VERSION ""

NS_ :

BS_:

BU_: CH DIPF DIPR ETH FC HVI HVS PARTY SDCV VEH VIRT

BO_ 777 DAS_object: 8 CH
 SG_ DAS_leadVeh2Id m0 : 58|6@1+ (1,0) [0|63] ""  aps
 SG_ DAS_leftVeh2Id m1 : 58|6@1+ (1,0) [0|63] ""  aps
 SG_ DAS_rightVeh2Id m2 : 58|6@1+ (1,0) [0|63] ""  aps
 SG_ DAS_cutinVehHeading m5 : 56|8@1+ (0.0245437,-3.1415936) [-3.1415936|3.0925062] "rad"  aps
 SG_ DAS_rightVeh2Dy m2 : 51|7@1+ (0.35,-22.05) [-22.05|22.4] "m"  aps
 SG_ DAS_leadVeh2Dy m0 : 51|7@1+ (0.35,-22.05) [-22.05|22.4] "m"  aps
 SG_ DAS_leftVeh2Dy m1 : 51|7@1+ (0.35,-22.05) [-22.05|22.4] "m"  aps
 SG_ DAS_rightVeh2Heading m5 : 48|8@1+ (0.0245437,-3.1415936) [-3.1415936|3.0925062] "rad"  aps
 SG_ DAS_leftVeh2VxRel m1 : 47|4@1+ (4,-30) [-30|26] "m/s"  aps
 SG_ DAS_rightVeh2VxRel m2 : 47|4@1+ (4,-30) [-30|26] "m/s"  aps
 SG_ DAS_leadVeh2VxRel m0 : 47|4@1+ (4,-30) [-30|26] "m/s"  aps
 SG_ DAS_rightVehHeading m5 : 40|8@1+ (0.0245437,-3.1415936) [-3.1415936|3.0925062] "rad"  aps
 SG_ DAS_leftVeh2Dx m1 : 39|8@1+ (0.5,0) [0|127] "m"  aps
 SG_ DAS_rightVeh2Dx m2 : 39|8@1+ (0.5,0) [0|127] "m"  aps
 SG_ DAS_leadVeh2Dx m0 : 39|8@1+ (0.5,0) [0|127] "m"  aps
 SG_ DAS_leadVeh2RelevantForControl m0 : 38|1@1+ (1,0) [0|1] ""  aps
 SG_ DAS_rightVeh2RelevantForControl m2 : 38|1@1+ (1,0) [0|1] ""  aps
 SG_ DAS_leftVeh2RelevantForControl m1 : 38|1@1+ (1,0) [0|1] ""  aps
 SG_ DAS_leadVeh2Type m0 : 34|3@1+ (1,0) [0|5] ""  aps
 SG_ DAS_leftVeh2Type m1 : 34|3@1+ (1,0) [0|5] ""  aps
 SG_ DAS_rightVeh2Type m2 : 34|3@1+ (1,0) [0|5] ""  aps
 SG_ DAS_leftVeh2Heading m5 : 32|8@1+ (0.0245437,-3.1415936) [-3.1415936|3.0925062] "rad"  aps
 SG_ DAS_roadSignOrientation m4 : 30|2@1+ (1,0) [0|2] ""  aps
 SG_ DAS_roadSignArrow m4 : 27|3@1+ (1,0) [0|4] ""  aps
 SG_ DAS_rightVehId m2 : 27|7@1+ (1,0) [0|127] ""  aps
 SG_ DAS_leadVehId m0 : 27|7@1+ (1,0) [0|127] ""  aps
 SG_ DAS_cutinVehId m3 : 27|7@1+ (1,0) [0|127] ""  aps
 SG_ DAS_leftVehId m1 : 27|7@1+ (1,0) [0|127] ""  aps
 SG_ DAS_roadSignSource m4 : 25|2@1+ (1,0) [0|2] ""  aps
 SG_ DAS_roadSignControlActive m4 : 24|1@1+ (1,0) [0|1] ""  aps
 SG_ DAS_leftVehHeading m5 : 24|8@1+ (0.0245437,-3.1415936) [-3.1415936|3.0925062] "rad"  aps
 SG_ DAS_leadVehDy m0 : 20|7@1+ (0.35,-22.05) [-22.05|22.4] "m"  aps
 SG_ DAS_cutinVehDy m3 : 20|7@1+ (0.35,-22.05) [-22.05|22.4] "m"  aps
 SG_ DAS_leftVehDy m1 : 20|7@1+ (0.35,-22.05) [-22.05|22.4] "m"  aps
 SG_ DAS_rightVehDy m2 : 20|7@1+ (0.35,-22.05) [-22.05|22.4] "m"  aps
 SG_ DAS_leadVehVxRel m0 : 16|4@1+ (4,-30) [-30|26] "m/s"  aps
 SG_ DAS_cutinVehVxRel m3 : 16|4@1+ (4,-30) [-30|26] "m/s"  aps
 SG_ DAS_rightVehVxRel m2 : 16|4@1+ (4,-30) [-30|26] "m/s"  aps
 SG_ DAS_leftVehVxRel m1 : 16|4@1+ (4,-30) [-30|26] "m/s"  aps
 SG_ DAS_leadVeh2Heading m5 : 16|8@1+ (0.0245437,-3.1415936) [-3.1415936|3.0925062] "rad"  aps
 SG_ DAS_roadSignStopLineDist m4 : 14|10@1+ (0.2,-20) [-20|184.4] "m"  aps
 SG_ DAS_rightVehDx m2 : 8|8@1+ (0.5,0) [0|127] "m"  aps
 SG_ DAS_cutinVehDx m3 : 8|8@1+ (0.5,0) [0|127] "m"  aps
 SG_ DAS_leftVehDx m1 : 8|8@1+ (0.5,0) [0|127] "m"  aps
 SG_ DAS_leadVehDx m0 : 8|8@1+ (0.5,0) [0|127] "m"  aps
 SG_ DAS_leadVehHeading m5 : 8|8@1+ (0.0245437,-3.1415936) [-3.1415936|3.0925062] "rad"  aps
 SG_ DAS_leftVehRelevantForControl m1 : 7|1@1+ (1,0) [0|1] ""  aps
 SG_ DAS_rightVehRelevantForControl m2 : 7|1@1+ (1,0) [0|1] ""  aps
 SG_ DAS_leadVehRelevantForControl m0 : 7|1@1+ (1,0) [0|1] ""  aps
 SG_ DAS_cutinVehRelevantForControl m3 : 7|1@1+ (1,0) [0|1] ""  aps
 SG_ DAS_roadSignId m4 : 6|8@1+ (1,0) [0|255] ""  aps
 SG_ DAS_leadVehType m0 : 3|3@1+ (1,0) [0|6] ""  aps
 SG_ DAS_rightVehType m2 : 3|3@1+ (1,0) [0|5] ""  aps
 SG_ DAS_roadSignColor m4 : 3|3@1+ (1,0) [0|4] ""  aps
 SG_ DAS_leftVehType m1 : 3|3@1+ (1,0) [0|5] ""  aps
 SG_ DAS_cutinVehType m3 : 3|3@1+ (1,0) [0|5] ""  aps
 SG_ DAS_objectId M : 0|3@1+ (1,0) [0|5] ""  aps

BO_ 1796 DBG_xcpPMCommand: 8 CH
 SG_ DBG_xcpPMCommand : 7|64@0+ (1,0) [0|18446744073709551615] ""  X

BO_ 737 VCFRONT_status: 8 CH
 SG_ VCFRONT_frunkAccessPost m0 : 62|1@1+ (1,0) [0|1] ""  X
 SG_ VCFRONT_headlampRightFanStatus m0 : 61|1@1+ (1,0) [0|1] ""  X
 SG_ VCFRONT_headlampLeftFanStatus m0 : 60|1@1+ (1,0) [0|1] ""  X
 SG_ VCFRONT_12VOverchargeCounter m4 : 59|4@1+ (1,0) [0|15] ""  X
 SG_ VCFRONT_sleepCurrent m1 : 53|10@1- (1,0) [-512|511] "mA"  X
 SG_ VCFRONT_wiperPositionDeg m0 : 52|8@1+ (1,0) [0|255] "deg"  X
 SG_ VCFRONT_hornOn m0 : 51|1@1+ (1,0) [0|1] ""  X
 SG_ VCFRONT_anyDoorOpen m0 : 50|1@1+ (1,0) [0|1] ""  tas
 SG_ VCFRONT_anyClosureOpen m0 : 49|1@1+ (1,0) [0|1] ""  tas
 SG_ VCFRONT_wiperCycles m3 : 48|16@1+ (100,0) [0|6553500] "Cycles"  X
 SG_ VCFRONT_homelinkCommStatus m2 : 48|2@1+ (1,0) [0|3] ""  X
 SG_ VCFRONT_frunkInteriorRelSwitch m0 : 48|1@1+ (1,0) [0|1] ""  X
 SG_ VCFRONT_timeSpentSleeping m1 : 45|8@1+ (1,0) [0|255] "s"  X
 SG_ VCFRONT_IBSUnfilteredTemperature m4 : 43|16@1- (0.01,0) [-327.68|327.67] "degC"  X
 SG_ VCFRONT_HSDInitCompleteU16 m4 : 42|1@1+ (1,0) [0|1] ""  X
 SG_ VCFRONT_HSDInitCompleteU13 m4 : 41|1@1+ (1,0) [0|1] ""  X
 SG_ VCFRONT_PEResetLineState m4 : 40|1@1+ (1,0) [0|1] ""  X
 SG_ VCFRONT_pressureRefrigDischarge m3 : 40|8@1+ (0.125,0) [0|31.75] "bar"  X
 SG_ VCFRONT_homelinkV2Response4 m2 : 40|8@1+ (1,0) [0|255] ""  X
 SG_ VCFRONT_IBSFault m4 : 39|1@1+ (1,0) [0|1] ""  X
 SG_ VCFRONT_PCSMia m4 : 38|1@1+ (1,0) [0|1] ""  X
 SG_ VCFRONT_headlightRightVPosition m0 : 38|10@1+ (1,0) [0|1023] "ticks"  X
 SG_ VCFRONT_chargeNeeded m4 : 37|1@1+ (1,0) [0|1] ""  X
 SG_ VCFRONT_timeSpentDischarging m1 : 35|10@1+ (1,0) [0|1023] "min"  X
 SG_ VCFRONT_pressureRefrigSuction m3 : 32|7@1+ (0.125,0) [0|11.5] "bar"  X
 SG_ VCFRONT_homelinkV2Response3 m2 : 32|8@1+ (1,0) [0|255] ""  X
 SG_ VCFRONT_hasLowRefrigerant m3 : 29|1@1+ (1,0) [0|1] ""  X
 SG_ VCFRONT_headlightLeftVPosition m0 : 28|10@1+ (1,0) [0|1023] "ticks"  X
 SG_ VCFRONT_compPerfRecoveryLimited m3 : 27|1@1+ (1,0) [0|1] ""  X
 SG_ VCFRONT_chillerDemandActive m3 : 26|1@1+ (1,0) [0|1] ""  X
 SG_ VCFRONT_timeSpentCharging m1 : 25|10@1+ (1,0) [0|1023] "min"  X
 SG_ VCFRONT_isEvapOperationAllowed m3 : 25|1@1+ (1,0) [0|1] ""  X
 SG_ VCFRONT_airCompressorStatus m0 : 25|3@1+ (1,0) [0|7] ""  tas
 SG_ VCFRONT_AS8510Voltage m4 : 25|12@1+ (0.005443676098,0) [0|22.28641] "V"  X
 SG_ VCFRONT_crashUnlockOverrideSet m0 : 24|1@1+ (1,0) [0|1] ""  X
 SG_ VCFRONT_freezeEvapITerm m3 : 24|1@1+ (1,0) [0|1] ""  X
 SG_ VCFRONT_homelinkV2Response2 m2 : 24|8@1+ (1,0) [0|255] ""  X
 SG_ VCFRONT_crashState m0 : 22|2@1+ (1,0) [0|2] ""  X
 SG_ VCFRONT_batterySMState m1 : 22|3@1+ (1,0) [0|7] ""  X
 SG_ VCFRONT_reverseBatteryFault m1 : 21|1@1+ (1,0) [0|1] ""  X
 SG_ VCFRONT_crashDetectedType m0 : 20|2@1+ (1,0) [0|2] ""  X
 SG_ VCFRONT_vehicleStatusDBG m1 : 16|5@1+ (1,0) [0|17] ""  X
 SG_ VCFRONT_wiperState m0 : 16|4@1+ (1,0) [0|12] ""  das
 SG_ VCFRONT_homelinkV2Response1 m2 : 16|8@1+ (1,0) [0|255] ""  X
 SG_ VCFRONT_minEvapHeatRejection m3 : 16|8@1+ (10,0) [0|2500] "W"  X
 SG_ VCFRONT_vbatMonitorVoltage m4 : 13|12@1+ (0.005443676098,0) [0|22.28641] "V"  X
 SG_ VCFRONT_iBoosterStateDBG m1 : 12|3@1+ (1,0) [0|4] ""  X
 SG_ VCFRONT_wiperPosition m0 : 12|3@1+ (1,0) [0|4] ""  X
 SG_ VCFRONT_epasWakeLine m1 : 11|1@1+ (1,0) [0|1] ""  X
 SG_ VCFRONT_iBoosterWakeLine m1 : 10|1@1+ (1,0) [0|1] ""  X
 SG_ VCFRONT_ChargePumpVoltageStable m1 : 9|1@1+ (1,0) [0|1] ""  X
 SG_ VCFRONT_homelinkV2Response0 m2 : 8|8@1+ (1,0) [0|255] ""  X
 SG_ VCFRONT_railBState m1 : 8|1@1+ (1,0) [0|1] ""  X
 SG_ VCFRONT_maxEvapHeatRejection m3 : 8|8@1+ (32,0) [0|8000] "W"  X
 SG_ VCFRONT_wiperSpeed m0 : 8|4@1+ (1,0) [0|8] ""  das
 SG_ VCFRONT_railAState m1 : 7|1@1+ (1,0) [0|1] ""  X
 SG_ VCFRONT_12VBRailStable m1 : 6|1@1+ (1,0) [0|1] ""  X
 SG_ VCFRONT_12VARailStable m1 : 5|1@1+ (1,0) [0|1] ""  X
 SG_ VCFRONT_5VBRailStable m1 : 4|1@1+ (1,0) [0|1] ""  X
 SG_ VCFRONT_frunkLatchStatus m0 : 3|4@1+ (1,0) [0|8] ""  X
 SG_ VCFRONT_tempCompTargetVoltage m4 : 3|10@1+ (0.01,9) [9|16] "V"  X
 SG_ VCFRONT_5VARailStable m1 : 3|1@1+ (1,0) [0|1] ""  X
 SG_ VCFRONT_statusIndex M : 0|3@1+ (1,0) [0|5] ""  X

BO_ 1030 DAS_robDebug: 8 CH
 SG_ DAS_eObj03Elevated m3 : 58|1@1+ (1,0) [0|1] ""  X
 SG_ DAS_eObj00Elevated m0 : 58|1@1+ (1,0) [0|1] ""  X
 SG_ DAS_eObj01Elevated m1 : 58|1@1+ (1,0) [0|1] ""  X
 SG_ DAS_eObj02Elevated m2 : 58|1@1+ (1,0) [0|1] ""  X
 SG_ DAS_eObj00Blacklist m0 : 57|1@1+ (1,0) [0|1] ""  X
 SG_ DAS_eObj01Blacklist m1 : 57|1@1+ (1,0) [0|1] ""  X
 SG_ DAS_eObj02Blacklist m2 : 57|1@1+ (1,0) [0|1] ""  X
 SG_ DAS_eObj03Blacklist m3 : 57|1@1+ (1,0) [0|1] ""  X
 SG_ DAS_eObj00InPath m0 : 56|1@1+ (1,0) [0|1] ""  X
 SG_ DAS_eObj01InPath m1 : 56|1@1+ (1,0) [0|1] ""  X
 SG_ DAS_eObj02InPath m2 : 56|1@1+ (1,0) [0|1] ""  X
 SG_ DAS_robTimeCollision m4 : 56|8@1+ (0.05,0) [0|12.75] "s"  X
 SG_ DAS_eObj03InPath m3 : 56|1@1+ (1,0) [0|1] ""  X
 SG_ DAS_eObj01Moment3 m1 : 48|8@1+ (0.25,-31.875) [-31.875|31.85] "m"  X
 SG_ DAS_eObj02Moment3 m2 : 48|8@1+ (0.25,-31.875) [-31.875|31.85] "m"  X
 SG_ DAS_eObj03Moment3 m3 : 48|8@1+ (0.25,-31.875) [-31.875|31.85] "m"  X
 SG_ DAS_eObj00Moment3 m0 : 48|8@1+ (0.25,-31.875) [-31.875|31.85] "m"  X
 SG_ DAS_robOverlapObstacle m4 : 48|8@1+ (0.1,0) [0|25.5] "m"  X
 SG_ DAS_robWidthObstacle m4 : 40|8@1+ (0.1,0) [0|25.5] "m"  X
 SG_ DAS_eObj02Moment2 m2 : 40|8@1+ (0.25,-31.875) [-31.875|31.85] "m"  X
 SG_ DAS_eObj01Moment2 m1 : 40|8@1+ (0.25,-31.875) [-31.875|31.85] "m"  X
 SG_ DAS_eObj00Moment2 m0 : 40|8@1+ (0.25,-31.875) [-31.875|31.85] "m"  X
 SG_ DAS_eObj03Moment2 m3 : 40|8@1+ (0.25,-31.875) [-31.875|31.85] "m"  X
 SG_ DAS_eObj03Moment1 m3 : 32|8@1+ (0.25,-31.875) [-31.875|31.85] "m"  X
 SG_ DAS_eObj00Moment1 m0 : 32|8@1+ (0.25,-31.875) [-31.875|31.85] "m"  X
 SG_ DAS_eObj01Moment1 m1 : 32|8@1+ (0.25,-31.875) [-31.875|31.85] "m"  X
 SG_ DAS_eObj02Moment1 m2 : 32|8@1+ (0.25,-31.875) [-31.875|31.85] "m"  X
 SG_ DAS_robDistanceObstacle m4 : 32|8@1+ (1,0) [0|255] "m"  X
 SG_ DAS_robActiveLogging m5 : 29|1@1+ (1,0) [0|1] ""  X
 SG_ DAS_robRadarBlind m5 : 28|1@1+ (1,0) [0|1] ""  X
 SG_ DAS_robRadarFault m5 : 27|1@1+ (1,0) [0|1] ""  X
 SG_ DAS_robGPSHealthy m5 : 26|1@1+ (1,0) [0|1] ""  X
 SG_ DAS_robEnableBraking m5 : 25|1@1+ (1,0) [0|1] ""  X
 SG_ DAS_robMapTrust m5 : 24|1@1+ (1,0) [0|1] ""  X
 SG_ DAS_eObj00Moment0 m0 : 24|8@1+ (0.25,-31.875) [-31.875|31.85] "m"  X
 SG_ DAS_eObj03Moment0 m3 : 24|8@1+ (0.25,-31.875) [-31.875|31.85] "m"  X
 SG_ DAS_eObj02Moment0 m2 : 24|8@1+ (0.25,-31.875) [-31.875|31.85] "m"  X
 SG_ DAS_eObj01Moment0 m1 : 24|8@1+ (0.25,-31.875) [-31.875|31.85] "m"  X
 SG_ DAS_robCriticalObjIndex m4 : 24|4@1+ (1,0) [0|15] ""  X
 SG_ DAS_robCriticalObjAge m4 : 20|4@1+ (1,0) [0|15] ""  X
 SG_ DAS_eObj02PositionY m2 : 16|8@1+ (0.25,-31.875) [-31.875|31.85] "m"  X
 SG_ DAS_eObj01PositionY m1 : 16|8@1+ (0.25,-31.875) [-31.875|31.85] "m"  X
 SG_ DAS_robCollisionConf m4 : 16|4@1+ (1,0) [0|15] ""  X
 SG_ DAS_eObj00PositionY m0 : 16|8@1+ (0.25,-31.875) [-31.875|31.85] "m"  X
 SG_ DAS_robClusterEnd m5 : 16|8@1+ (1,0) [0|255] "m"  X
 SG_ DAS_eObj03PositionY m3 : 16|8@1+ (0.25,-31.875) [-31.875|31.85] "m"  X
 SG_ DAS_robMapTrusted m4 : 13|1@1+ (1,0) [0|1] ""  X
 SG_ DAS_robAEBAlertLatch m4 : 12|1@1+ (1,0) [0|1] ""  X
 SG_ DAS_robInfrastructure m4 : 11|1@1+ (1,0) [0|1] ""  X
 SG_ DAS_robRequestEventRecorder m4 : 10|1@1+ (1,0) [0|1] ""  X
 SG_ DAS_robActiveBraking m4 : 9|1@1+ (1,0) [0|1] ""  X
 SG_ DAS_eObj01PositionX m1 : 8|8@1+ (0.5,0) [0|127.5] "m"  X
 SG_ DAS_eObj02PositionX m2 : 8|8@1+ (0.5,0) [0|127.5] "m"  X
 SG_ DAS_robClusterStart m5 : 8|8@1+ (1,-95) [-95|160] "m"  X
 SG_ DAS_eObj03PositionX m3 : 8|8@1+ (0.5,0) [0|127.5] "m"  X
 SG_ DAS_robPossibleCollision m4 : 8|1@1+ (1,0) [0|1] ""  X
 SG_ DAS_eObj00PositionX m0 : 8|8@1+ (0.5,0) [0|127.5] "m"  X
 SG_ DAS_eObj03Age m3 : 5|3@1+ (1,0) [0|7] ""  X
 SG_ DAS_eObj00Age m0 : 5|3@1+ (1,0) [0|7] ""  X
 SG_ DAS_eObj01Age m1 : 5|3@1+ (1,0) [0|7] ""  X
 SG_ DAS_eObj02Age m2 : 5|3@1+ (1,0) [0|7] ""  X
 SG_ DAS_eObj00Valid m0 : 4|1@1+ (1,0) [0|1] ""  X
 SG_ DAS_eObj03Valid m3 : 4|1@1+ (1,0) [0|1] ""  X
 SG_ DAS_eObj02Valid m2 : 4|1@1+ (1,0) [0|1] ""  X
 SG_ DAS_eObj01Valid m1 : 4|1@1+ (1,0) [0|1] ""  X
 SG_ DAS_eObjMultiplexer M : 0|4@1+ (1,0) [0|5] ""  X

BO_ 848 APS_warningMatrix3: 8 CH
 SG_ APS_w231_idfEvent : 38|1@1+ (1,0) [0|1] ""  gtw
 SG_ APS_w230_alcUltrasoundBlocked : 37|1@1+ (1,0) [0|1] ""  gtw
 SG_ APS_w229_alcUltrasoundDamaged : 36|1@1+ (1,0) [0|1] ""  gtw
 SG_ APS_w228_DEPRECATED : 35|1@1+ (1,0) [0|1] ""  gtw
 SG_ APS_w227_virtualWallBlocked : 34|1@1+ (1,0) [0|1] ""  gtw
 SG_ APS_w226_lcCamCalNeededSpeedLmt : 33|1@1+ (1,0) [0|1] ""  gtw
 SG_ APS_w225_lcDegradedVisSpeedLmt : 32|1@1+ (1,0) [0|1] ""  gtw
 SG_ APS_w224_accCameraCalibration : 31|1@1+ (1,0) [0|1] ""  gtw
 SG_ APS_w223_accObjectInPath : 30|1@1+ (1,0) [0|1] ""  gtw
 SG_ APS_w222_accCameraBlind : 29|1@1+ (1,0) [0|1] ""  gtw
 SG_ APS_w221_accRadarBlind : 28|1@1+ (1,0) [0|1] ""  gtw
 SG_ APS_w220_lcTempUnavailableRoad : 27|1@1+ (1,0) [0|1] ""  gtw
 SG_ APS_w219_lcTempUnavailableSpeed : 26|1@1+ (1,0) [0|1] ""  gtw
 SG_ APS_w218_lcSpeedExceededLimit : 25|1@1+ (1,0) [0|1] ""  gtw
 SG_ APS_w217_lcUnavailableSpeeding : 24|1@1+ (1,0) [0|1] ""  gtw
 SG_ APS_w216_driverOverriding : 23|1@1+ (1,0) [0|1] ""  gtw
 SG_ APS_w215_contDriverNotIntracting : 22|1@1+ (1,0) [0|1] ""  gtw
 SG_ APS_w214_driverNotIntracting : 21|1@1+ (1,0) [0|1] ""  gtw
 SG_ APS_w213_autosteerStruckOut : 20|1@1+ (1,0) [0|1] ""  gtw
 SG_ APS_w212_lcUnavailableStrikeOut : 19|1@1+ (1,0) [0|1] ""  gtw
 SG_ APS_w211_accNoSeatBelt : 18|1@1+ (1,0) [0|1] ""  gtw
 SG_ APS_w210_camObstrcted : 17|1@1+ (1,0) [0|1] ""  gtw
 SG_ APS_w209_autoSummonRequest : 16|1@1+ (1,0) [0|1] ""  gtw
 SG_ APS_w208_rackDetected : 15|1@1+ (1,0) [0|1] ""  gtw
 SG_ APS_w207_autosteerUnavailable : 14|1@1+ (1,0) [0|1] ""  gtw
 SG_ APS_w206_autosteerNotEnabled : 13|1@1+ (1,0) [0|1] ""  gtw
 SG_ APS_w205_apcFinalRear : 12|1@1+ (1,0) [0|1] ""  gtw
 SG_ APS_w204_apcFinalFront : 11|1@1+ (1,0) [0|1] ""  gtw
 SG_ APS_w203_apcActivation : 10|1@1+ (1,0) [0|1] ""  gtw
 SG_ APS_w202_scwNoisyEnvironment : 9|1@1+ (1,0) [0|1] ""  gtw
 SG_ APS_w201_lcAborting : 8|1@1+ (1,0) [0|1] ""  gtw
 SG_ APS_w200_lcSlowdown : 7|1@1+ (1,0) [0|1] ""  gtw
 SG_ APS_w199_apcAbort : 6|1@1+ (1,0) [0|1] ""  gtw
 SG_ APS_w198_tsrUnavailable : 5|1@1+ (1,0) [0|1] ""  gtw
 SG_ APS_w197_redLightWarning : 4|1@1+ (1,0) [0|1] ""  gtw
 SG_ APS_w196_stopSignWarning : 3|1@1+ (1,0) [0|1] ""  gtw
 SG_ APS_w195_scwUnavailable : 2|1@1+ (1,0) [0|1] ""  gtw
 SG_ APS_w194_accDriverResumeRqrd : 1|1@1+ (1,0) [0|1] ""  gtw
 SG_ APS_w193_camWindshieldUnclean : 0|1@1+ (1,0) [0|1] ""  gtw

BO_ 1481 APS_alertLog: 8 CH
 SG_ APS_sw060_accActive m60 : 63|1@1+ (1,0) [0|1] ""  gtw
 SG_ APS_sw053_a62strRackMismatch m53 : 63|1@1+ (1,0) [0|1] ""  gtw
 SG_ APS_sw017_Any_FCW_PCW_Msg_Recd m17 : 63|1@1+ (1,0) [0|1] ""  gtw
 SG_ APS_sw050_accActive m50 : 63|1@1+ (1,0) [0|1] ""  gtw
 SG_ APS_sw074_autopilotActive m74 : 63|1@1+ (1,0) [0|1] ""  gtw
 SG_ APS_sw076_accActive m76 : 63|1@1+ (1,0) [0|1] ""  gtw
 SG_ APS_sw016_accActive m16 : 63|1@1+ (1,0) [0|1] ""  gtw
 SG_ APS_sw072_userTimeout m72 : 62|1@1+ (1,0) [0|1] ""  gtw
 SG_ APS_sw027_Unused_word m27 : 62|2@1+ (1,0) [0|3] ""  gtw
 SG_ APS_sw053_a61radPositionMismatch m53 : 62|1@1+ (1,0) [0|1] ""  gtw
 SG_ APS_sw017_Any_Common_Msg_Recd m17 : 62|1@1+ (1,0) [0|1] ""  gtw
 SG_ APS_sw074_cruiseActive m74 : 62|1@1+ (1,0) [0|1] ""  gtw
 SG_ APS_sw016_fcmModeAtEvent m16 : 61|2@1+ (1,0) [0|3] ""  gtw
 SG_ APS_sw076_fcmModeAtEvent m76 : 61|2@1+ (1,0) [0|3] ""  gtw
 SG_ APS_sw053_a60drmiInvalidCount m53 : 61|1@1+ (1,0) [0|1] ""  gtw
 SG_ APS_sw004_visionNotRunning m4 : 61|1@1+ (1,0) [0|1] ""  gtw
 SG_ APS_sw050_fcmModeAtEvent m50 : 61|2@1+ (1,0) [0|3] ""  gtw
 SG_ APS_sw072_garageOpened m72 : 61|1@1+ (1,0) [0|1] ""  gtw
 SG_ APS_sw027_PORST m27 : 61|1@1+ (1,0) [0|1] ""  gtw
 SG_ APS_sw017_Any_Hlb_Msg_Recd m17 : 61|1@1+ (1,0) [0|1] ""  gtw
 SG_ APS_sw060_collisionWarningSource m60 : 60|3@1+ (1,0) [0|7] ""  gtw
 SG_ APS_sw004_SelfGlare m4 : 60|1@1+ (1,0) [0|1] ""  gtw
 SG_ APS_sw016_overrideSteer m16 : 60|1@1+ (1,0) [0|1] ""  gtw
 SG_ APS_sw072_keyfobPress m72 : 60|1@1+ (1,0) [0|1] ""  gtw
 SG_ APS_sw073_freespaceRightFarZ m73 : 60|4@1+ (4,0) [0|60] "m"  gtw
 SG_ APS_sw076_overrideSteer m76 : 60|1@1+ (1,0) [0|1] ""  gtw
 SG_ APS_sw231_predOverlap m231 : 60|4@1+ (10,0) [0|150] "percent"  gtw
 SG_ APS_sw053_a59drmiInvalidChkSm m53 : 60|1@1+ (1,0) [0|1] ""  gtw
 SG_ APS_sw027_STDBY_WDG m27 : 60|1@1+ (1,0) [0|1] ""  gtw
 SG_ APS_sw017_Any_Tsr_Msg_Recd m17 : 60|1@1+ (1,0) [0|1] ""  gtw
 SG_ APS_sw199_numShifts m199 : 60|4@1+ (1,0) [0|15] ""  gtw
 SG_ APS_sw013_numTransportErrors m13 : 60|4@1+ (1,0) [0|15] ""  gtw
 SG_ APS_sw050_overrideSteer m50 : 60|1@1+ (1,0) [0|1] ""  gtw
 SG_ APS_sw072_handlePress m72 : 59|1@1+ (1,0) [0|1] ""  gtw
 SG_ APS_sw074_roadClass m74 : 59|3@1+ (1,0) [0|7] ""  gtw
 SG_ APS_sw027_SWD m27 : 59|1@1+ (1,0) [0|1] ""  gtw
 SG_ APS_sw083_Targ5_wNonObj m83 : 59|5@1+ (0.03125,0) [0|0.96875] "%"  gtw
 SG_ APS_sw016_overrideBrake m16 : 59|1@1+ (1,0) [0|1] ""  gtw
 SG_ APS_sw004_FoggyLights m4 : 59|1@1+ (1,0) [0|1] ""  gtw
 SG_ APS_sw076_overrideBrake m76 : 59|1@1+ (1,0) [0|1] ""  gtw
 SG_ APS_sw103_radAlignment m103 : 59|5@1+ (0.015625,-0.2343) [-0.2343|0.25] "rad"  gtw
 SG_ APS_sw060_overrideSteer m60 : 59|1@1+ (1,0) [0|1] ""  gtw
 SG_ APS_sw050_overrideBrake m50 : 59|1@1+ (1,0) [0|1] ""  gtw
 SG_ APS_sw053_a57dimodValidity m53 : 59|1@1+ (1,0) [0|1] ""  gtw
 SG_ APS_sw231_steeringOverride m231 : 59|1@1+ (1,0) [0|1] ""  gtw
 SG_ APS_sw016_overrideBlinker m16 : 58|1@1+ (1,0) [0|1] ""  gtw
 SG_ APS_sw072_guidanceTimer m72 : 58|1@1+ (1,0) [0|1] ""  gtw
 SG_ APS_sw027_EVR33 m27 : 58|1@1+ (1,0) [0|1] ""  gtw
 SG_ APS_sw053_a56bcmodValidity m53 : 58|1@1+ (1,0) [0|1] ""  gtw
 SG_ APS_sw129_railID m129 : 58|6@1+ (1,0) [0|63] ""  gtw
 SG_ APS_sw047_unused m47 : 58|6@1+ (1,0) [0|63] ""  gtw
 SG_ APS_sw076_overrideBlinker m76 : 58|1@1+ (1,0) [0|1] ""  gtw
 SG_ APS_sw060_overrideBrake m60 : 58|1@1+ (1,0) [0|1] ""  gtw
 SG_ APS_sw006_timeOfDay m6 : 58|2@1+ (1,0) [0|3] ""  gtw
 SG_ APS_sw085_freeSpaceC0Right m85 : 58|5@1+ (1,-15) [-15|16] "m"  gtw
 SG_ APS_sw004_SmearedHalos m4 : 58|1@1+ (1,0) [0|1] ""  gtw
 SG_ APS_sw050_overrideBlinker m50 : 58|1@1+ (1,0) [0|1] ""  gtw
 SG_ APS_sw006_trailerMode m6 : 57|1@1+ (1,0) [0|1] ""  gtw
 SG_ APS_sw053_a55stwmodValidity m53 : 57|1@1+ (1,0) [0|1] ""  gtw
 SG_ APS_sw060_overrideBlinker m60 : 57|1@1+ (1,0) [0|1] ""  gtw
 SG_ APS_sw103_constArea m103 : 57|2@1+ (1,0) [0|3] ""  gtw
 SG_ APS_sw050_overrideAccelPed m50 : 57|1@1+ (1,0) [0|1] ""  gtw
 SG_ APS_sw004_FullBlockage m4 : 57|1@1+ (1,0) [0|1] ""  gtw
 SG_ APS_sw027_EVR13 m27 : 57|1@1+ (1,0) [0|1] ""  gtw
 SG_ APS_sw129_railControl m129 : 57|1@1+ (1,0) [0|1] ""  gtw
 SG_ APS_sw076_overrideAccelPed m76 : 57|1@1+ (1,0) [0|1] ""  gtw
 SG_ APS_sw072_guidanceRunaway m72 : 57|1@1+ (1,0) [0|1] ""  gtw
 SG_ APS_sw026_veh_mean_utilization m26 : 57|7@1+ (1,0) [0|127] "percent"  gtw
 SG_ APS_sw016_overrideAccelPed m16 : 57|1@1+ (1,0) [0|1] ""  gtw
 SG_ APS_sw076_driverPressedBrakePed m76 : 56|1@1+ (1,0) [0|1] ""  gtw
 SG_ APS_sw042_road_class m42 : 56|3@1+ (1,0) [0|7] ""  gtw
 SG_ APS_sw129_powerSequnceError m129 : 56|1@1+ (1,0) [0|1] ""  gtw
 SG_ APS_sw073_freespaceLeftFarZ m73 : 56|4@1+ (4,0) [0|60] "m"  gtw
 SG_ APS_sw047_edrLoggerBuffer m47 : 56|2@1+ (1,0) [0|3] ""  gtw
 SG_ APS_sw016_driverPressedBrakePed m16 : 56|1@1+ (1,0) [0|1] ""  gtw
 SG_ APS_sw027_CBS_APP m27 : 56|1@1+ (1,0) [0|1] ""  gtw
 SG_ APS_sw072_guidanceComplete m72 : 56|1@1+ (1,0) [0|1] ""  gtw
 SG_ APS_sw205_rrRightMiddle m205 : 56|8@1+ (1,0) [0|255] "cm"  gtw
 SG_ APS_sw067_offsetEstimator m67 : 56|8@1+ (0.1,-12.8) [-12.8|12.8] "deg"  gtw
 SG_ APS_sw015_NarrowCameraBadAssoc m15 : 56|2@1+ (1,0) [0|3] ""  gtw
 SG_ APS_sw011_laneWidth m11 : 56|8@1+ (0.025,0) [0|6.375] "m"  gtw
 SG_ APS_sw078_radarTarg1_VxRel m78 : 56|8@1+ (0.2,-25.6) [-25.6|25.4] "m/s"  gtw
 SG_ APS_sw131_trapTaskPrio m131 : 56|8@1+ (1,0) [0|255] ""  gtw
 SG_ APS_sw204_maxSpeed m204 : 56|8@1+ (0.1,-12.2) [-12.2|12.2] "mph"  gtw
 SG_ APS_sw053_a54gtwmodValidity m53 : 56|1@1+ (1,0) [0|1] ""  gtw
 SG_ APS_sw060_overrideAccelPed m60 : 56|1@1+ (1,0) [0|1] ""  gtw
 SG_ APS_sw050_driverPressedBrakePed m50 : 56|1@1+ (1,0) [0|1] ""  gtw
 SG_ APS_sw006_brakeLights m6 : 56|1@1+ (1,0) [0|1] ""  gtw
 SG_ APS_sw103_ipsoApproved m103 : 56|1@1+ (1,0) [0|1] ""  gtw
 SG_ APS_sw004_AutofixOutOfCalibYaw m4 : 56|1@1+ (1,0) [0|1] ""  gtw
 SG_ APS_sw063_detectedSubMinorVer m63 : 56|8@1+ (1,0) [0|255] ""  gtw
 SG_ APS_sw040_view_range m40 : 56|8@1+ (1,0) [0|255] "m"  gtw
 SG_ APS_sw071_activationType m71 : 56|2@1+ (1,0) [0|3] ""  gtw
 SG_ APS_sw004_AutofixOutOfCalibHorzn m4 : 55|1@1+ (1,0) [0|1] ""  gtw
 SG_ APS_sw060_driverPressedBrakePed m60 : 55|1@1+ (1,0) [0|1] ""  gtw
 SG_ APS_sw016_driverPressedAccelPed m16 : 55|1@1+ (1,0) [0|1] ""  gtw
 SG_ APS_sw027_CBS_DEBUG m27 : 55|1@1+ (1,0) [0|1] ""  gtw
 SG_ APS_sw042_controlled_access m42 : 55|1@1+ (1,0) [0|1] ""  gtw
 SG_ APS_sw006_DIaebStateUnavailable m6 : 55|1@1+ (1,0) [0|1] ""  gtw
 SG_ APS_sw076_driverPressedAccelPed m76 : 55|1@1+ (1,0) [0|1] ""  gtw
 SG_ APS_sw053_a53espmodValidity m53 : 55|1@1+ (1,0) [0|1] ""  gtw
 SG_ APS_sw050_driverPressedAccelPed m50 : 55|1@1+ (1,0) [0|1] ""  gtw
 SG_ APS_sw069_drivingLaneRight m69 : 54|8@1+ (1,0) [0|255] ""  gtw
 SG_ APS_sw027_CBS_SYSTEM m27 : 54|1@1+ (1,0) [0|1] ""  gtw
 SG_ APS_sw053_a51yawSanity m53 : 54|1@1+ (1,0) [0|1] ""  gtw
 SG_ APS_sw231_egoVehicleSpeed m231 : 54|5@1+ (5,0) [0|155] "kph"  gtw
 SG_ APS_sw004_AutofixOutOfCalib m4 : 54|1@1+ (1,0) [0|1] ""  gtw
 SG_ APS_sw015_MainCameraBadAssoc m15 : 54|2@1+ (1,0) [0|3] ""  gtw
 SG_ APS_sw006_DIaebState_SNA m6 : 54|1@1+ (1,0) [0|1] ""  gtw
 SG_ APS_sw083_Targ5_wObj m83 : 54|5@1+ (0.03125,0) [0|0.96875] "%"  gtw
 SG_ APS_sw077_oocOffCourseDist_cm m77 : 54|10@1- (1,0) [-512|511] ""  gtw
 SG_ APS_sw074_ipsowExist m74 : 54|5@1+ (1,0) [0|31] ""  gtw
 SG_ APS_sw042_road_match m42 : 54|1@1+ (1,0) [0|1] ""  gtw
 SG_ APS_sw011_scaReasonEldw m11 : 53|1@1+ (1,0) [0|1] ""  gtw
 SG_ APS_sw085_freeSpaceC0Left m85 : 53|5@1+ (1,-15) [-15|16] "m"  gtw
 SG_ APS_sw053_a50velocitySanity m53 : 53|1@1+ (1,0) [0|1] ""  gtw
 SG_ APS_sw080_cruise_speed_check m80 : 53|1@1+ (1,0) [0|1] ""  gtw
 SG_ APS_sw004_PartialBlockage m4 : 53|1@1+ (1,0) [0|1] ""  gtw
 SG_ APS_sw027_STM2 m27 : 53|1@1+ (1,0) [0|1] ""  gtw
 SG_ APS_sw042_cam_OutofFocus m42 : 53|1@1+ (1,0) [0|1] ""  gtw
 SG_ APS_sw012_freescaleTemp m12 : 53|8@1- (1,0) [-128|127] "degC"  gtw
 SG_ APS_sw006_yawRate m6 : 53|1@1+ (1,0) [0|1] ""  gtw
 SG_ APS_sw231_targetIsACar m231 : 53|1@1+ (1,0) [0|1] ""  gtw
 SG_ APS_sw027_STM1 m27 : 52|1@1+ (1,0) [0|1] ""  gtw
 SG_ APS_sw004_SmearedSpots m4 : 52|1@1+ (1,0) [0|1] ""  gtw
 SG_ APS_sw042_cam_SelfGlare m42 : 52|1@1+ (1,0) [0|1] ""  gtw
 SG_ APS_sw011_egoCentered m11 : 52|1@1+ (1,0) [0|1] ""  gtw
 SG_ APS_sw015_NarrowCameraLowLight m15 : 52|2@1+ (1,0) [0|3] ""  gtw
 SG_ APS_sw053_a49tireSizeSanity m53 : 52|1@1+ (1,0) [0|1] ""  gtw
 SG_ APS_sw203_vehicleSkew m203 : 52|12@1+ (0.002,0) [0|8.19] "radians"  gtw
 SG_ APS_sw006_longAccel m6 : 52|1@1+ (1,0) [0|1] ""  gtw
 SG_ APS_sw199_maxSpeed m199 : 52|8@1+ (0.1,-12.2) [-12.2|12.2] "mph"  gtw
 SG_ APS_sw027_STM0 m27 : 51|1@1+ (1,0) [0|1] ""  gtw
 SG_ APS_sw131_trapTIN m131 : 51|3@1+ (1,0) [0|7] ""  gtw
 SG_ APS_sw060_RadarAssociationAge m60 : 51|4@1+ (100,0) [0|1500] "ms"  gtw
 SG_ APS_sw086_activeBraking m86 : 51|1@1+ (1,0) [0|1] ""  gtw
 SG_ APS_sw004_LowSun m4 : 51|1@1+ (1,0) [0|1] ""  gtw
 SG_ APS_sw042_cam_FoggySpots m42 : 51|1@1+ (1,0) [0|1] ""  gtw
 SG_ APS_sw053_a48steerAngOffSanity m53 : 51|1@1+ (1,0) [0|1] ""  gtw
 SG_ APS_sw006_camFcwPcwMsg m6 : 51|1@1+ (1,0) [0|1] ""  gtw
 SG_ APS_sw011_polyValid m11 : 51|1@1+ (1,0) [0|1] ""  gtw
 SG_ APS_sw042_cam_SmearedHalos m42 : 50|1@1+ (1,0) [0|1] ""  gtw
 SG_ APS_sw026_mob_mean_utilization m26 : 50|7@1+ (1,0) [0|127] "percent"  gtw
 SG_ APS_sw004_BlurredImage m4 : 50|1@1+ (1,0) [0|1] ""  gtw
 SG_ APS_sw027_SW m27 : 50|1@1+ (1,0) [0|1] ""  gtw
 SG_ APS_sw011_egoMovingLeft m11 : 50|1@1+ (1,0) [0|1] ""  gtw
 SG_ APS_sw006_camCommonMsg m6 : 50|1@1+ (1,0) [0|1] ""  gtw
 SG_ APS_sw015_MainCameraLowLight m15 : 50|2@1+ (1,0) [0|3] ""  gtw
 SG_ APS_sw080_cruise_lever_state m80 : 50|3@1+ (1,0) [0|7] ""  gtw
 SG_ APS_sw012_mespDDRTempStatus m12 : 50|3@1+ (1,0) [0|7] ""  gtw
 SG_ APS_sw053_a44yawValidity m53 : 50|1@1+ (1,0) [0|1] ""  gtw
 SG_ APS_sw138_ubxErrorReported m138 : 50|1@1+ (1,0) [0|1] ""  gtw
 SG_ APS_sw080_min_speed_check m80 : 49|1@1+ (1,0) [0|1] ""  gtw
 SG_ APS_sw011_egoLeftOfCenter m11 : 49|1@1+ (1,0) [0|1] ""  gtw
 SG_ APS_sw042_cam_FullBlock m42 : 49|1@1+ (1,0) [0|1] ""  gtw
 SG_ APS_sw006_camObjHeader m6 : 49|1@1+ (1,0) [0|1] ""  gtw
 SG_ APS_sw053_a43yawOffValidity m53 : 49|1@1+ (1,0) [0|1] ""  gtw
 SG_ APS_sw004_Splashes m4 : 49|1@1+ (1,0) [0|1] ""  gtw
 SG_ APS_sw027_ESR1 m27 : 49|1@1+ (1,0) [0|1] ""  gtw
 SG_ APS_sw138_gpsReadCfgNoResponse m138 : 49|1@1+ (1,0) [0|1] ""  gtw
 SG_ APS_sw058_unusedW1 m58 : 48|16@1+ (1,0) [0|65535] ""  gtw
 SG_ APS_sw050_hostLongAccel m50 : 48|7@1+ (0.15625,-10) [-10|10] "m/s^2"  gtw
 SG_ APS_sw062_VmaPlausibility m62 : 48|16@1+ (1.52587890625005e-05,0) [0|0.99998474121097] "FIXME"  gtw
 SG_ APS_sw028_multifrm_rx_len m28 : 48|16@1+ (1,0) [0|65535] ""  gtw
 SG_ APS_sw014_assertData m14 : 48|16@1+ (1,0) [0|65535] ""  gtw
 SG_ APS_sw001_APS_alertDataW2 m1 : 48|16@1+ (1,0) [0|65535] ""  gtw
 SG_ APS_sw039_unusedW1 m39 : 48|16@1+ (1,0) [0|65535] ""  gtw
 SG_ APS_sw031_errorData2 m31 : 48|16@1+ (1,0) [0|65535] ""  gtw
 SG_ APS_sw080_cipv_valid m80 : 48|1@1+ (1,0) [0|1] ""  gtw
 SG_ APS_sw034_unusedW1 m34 : 48|16@1+ (1,0) [0|65535] ""  gtw
 SG_ APS_sw049_ffs_version_msw m49 : 48|16@1+ (1,0) [0|65535] ""  gtw
 SG_ APS_sw043_camLongRunTime_unused m43 : 48|16@1+ (1,0) [0|65535] ""  gtw
 SG_ APS_sw138_gpsSetCfgNoAck m138 : 48|1@1+ (1,0) [0|1] ""  gtw
 SG_ APS_sw004_SunRay m4 : 48|1@1+ (1,0) [0|1] ""  gtw
 SG_ APS_sw051_unusedW1 m51 : 48|16@1+ (1,0) [0|65535] ""  gtw
 SG_ APS_sw037_unusedW1 m37 : 48|16@1+ (1,0) [0|65535] ""  gtw
 SG_ APS_sw082_road_class m82 : 48|3@1+ (1,0) [0|7] ""  gtw
 SG_ APS_sw020_unusedW2 m20 : 48|16@1+ (1,0) [0|65535] ""  gtw
 SG_ APS_sw103_distanceEllipse m103 : 48|8@1+ (0.5,0) [0|127.5] "m"  gtw
 SG_ APS_sw055_expectedCrcLsw m55 : 48|16@1+ (1,0) [0|65535] ""  gtw
 SG_ APS_sw081_pedalPosition m81 : 48|7@1+ (1,0) [0|127] "%"  gtw
 SG_ APS_sw025_torsionBarTorque m25 : 48|8@1+ (0.1,-12.8) [-12.8|12.7] "Nm"  gtw
 SG_ APS_sw027_ESR0 m27 : 48|1@1+ (1,0) [0|1] ""  gtw
 SG_ APS_sw042_cam_AutofixYaw m42 : 48|1@1+ (1,0) [0|1] ""  gtw
 SG_ APS_sw013_highestSeqRecd m13 : 48|12@1+ (1,0) [0|4095] ""  gtw
 SG_ APS_sw011_egoMovingRight m11 : 48|1@1+ (1,0) [0|1] ""  gtw
 SG_ APS_sw065_unusedW1 m65 : 48|16@1+ (1,0) [0|65535] ""  gtw
 SG_ APS_sw199_internalState m199 : 48|4@1+ (1,0) [0|15] ""  gtw
 SG_ APS_sw131_trapClass m131 : 48|3@1+ (1,0) [0|7] ""  gtw
 SG_ APS_sw054_unusedW0 m54 : 48|16@1+ (1,0) [0|65535] ""  gtw
 SG_ APS_sw071_temperature m71 : 48|8@1+ (0.5,-40) [-40|87.5] "C"  gtw
 SG_ APS_sw066_unusedW1 m66 : 48|16@1+ (1,0) [0|65535] ""  gtw
 SG_ APS_sw010_VmaPlausibility m10 : 48|16@1+ (1.52587890625005e-05,0) [0|0.99998474121097] "FIXME"  gtw
 SG_ APS_sw083_Targ5_dz m83 : 48|6@1+ (0.25,-5) [-5|10.75] "m"  gtw
 SG_ APS_sw040_torsion_bar_torque m40 : 48|8@1+ (0.1,-12.8) [-12.8|12.7] "Nm"  gtw
 SG_ APS_sw086_ellipseAge m86 : 48|3@1+ (1,0) [0|7] ""  gtw
 SG_ APS_sw036_unusedW1 m36 : 48|16@1+ (1,0) [0|65535] ""  gtw
 SG_ APS_sw205_rrRight m205 : 48|8@1+ (1,0) [0|255] "cm"  gtw
 SG_ APS_sw204_frRightMiddle m204 : 48|8@1+ (1,0) [0|255] "cm"  gtw
 SG_ APS_sw015_OutOfFocusImage m15 : 48|2@1+ (1,0) [0|3] ""  gtw
 SG_ APS_sw053_a42xwdValidity m53 : 48|1@1+ (1,0) [0|1] ""  gtw
 SG_ APS_sw075_unusedW1 m75 : 48|16@1+ (1,0) [0|65535] ""  gtw
 SG_ APS_sw017_highestSeqRecd m17 : 48|12@1+ (1,0) [0|4095] ""  gtw
 SG_ APS_sw016_hostLongAccel m16 : 48|7@1+ (0.15625,-10) [-10|10] "m/s^2"  gtw
 SG_ APS_sw073_freespaceRightC1 m73 : 48|8@1+ (0.0016,-0.2) [-0.2|0.2] "rad"  gtw
 SG_ APS_sw076_hostLongAccel m76 : 48|7@1+ (0.15625,-10) [-10|10] "m/s^2"  gtw
 SG_ APS_sw045_unusedW1 m45 : 48|16@1+ (1,0) [0|65535] ""  gtw
 SG_ APS_sw201_viewRangeOAL m201 : 48|3@1+ (1,0) [0|7] ""  gtw
 SG_ APS_sw160_expectedHash m160 : 48|16@1+ (1,0) [0|65535] ""  gtw
 SG_ APS_sw077_oocUntrackedTime m77 : 48|6@1+ (0.1,0) [0|6.3] "s"  gtw
 SG_ APS_sw032_errorData2 m32 : 48|16@1+ (1,0) [0|65535] ""  gtw
 SG_ APS_sw132_expectedHash m132 : 48|16@1+ (1,0) [0|65535] ""  gtw
 SG_ APS_sw006_camWatchdog m6 : 48|1@1+ (1,0) [0|1] ""  gtw
 SG_ APS_sw056_unusedW1 m56 : 48|16@1+ (1,0) [0|65535] ""  gtw
 SG_ APS_sw194_timeInHold m194 : 48|16@1+ (1,0) [0|65535] ""  gtw
 SG_ APS_sw063_expectedSubMinorVer m63 : 48|8@1+ (1,0) [0|255] ""  gtw
 SG_ APS_sw030_unusedW1 m30 : 48|16@1+ (1,0) [0|65535] ""  gtw
 SG_ APS_sw078_radarTarg1_dx m78 : 48|8@1+ (0.0625,0) [0|15.9375] "m"  gtw
 SG_ APS_sw029_unusedW1 m29 : 48|16@1+ (1,0) [0|65535] ""  gtw
 SG_ APS_sw072_endDistance m72 : 48|8@1+ (1,0) [0|255] "cm"  gtw
 SG_ APS_sw021_unusedWord m21 : 48|16@1+ (1,0) [0|65535] ""  gtw
 SG_ APS_sw074_ipsoConfidence m74 : 48|6@1+ (2,0) [0|126] "percent"  gtw
 SG_ APS_sw018_currentVoltage m18 : 48|16@1+ (1,0) [0|6600] "mV"  gtw
 SG_ APS_sw047_edrStateMachine m47 : 48|8@1+ (1,0) [0|255] ""  gtw
 SG_ APS_sw085_averageSpeedHist m85 : 47|6@1+ (0.25,0) [0|16] "mps"  gtw
 SG_ APS_sw011_egoRightOfCenter m11 : 47|1@1+ (1,0) [0|1] ""  gtw
 SG_ APS_sw018_railControl m18 : 47|1@1+ (1,0) [0|1] ""  gtw
 SG_ APS_sw060_hostLongAccel m60 : 47|4@1+ (1,-7.5) [-7.5|7.5] "m/s^2"  gtw
 SG_ APS_sw004_ImpairedVD m4 : 47|1@1+ (1,0) [0|1] ""  gtw
 SG_ APS_sw053_a41wiperValidity m53 : 47|1@1+ (1,0) [0|1] ""  gtw
 SG_ APS_sw006_speedDerivative m6 : 47|1@1+ (1,0) [0|1] ""  gtw
 SG_ APS_sw042_cam_AutofixHorizon m42 : 47|1@1+ (1,0) [0|1] ""  gtw
 SG_ APS_sw004_OutOfFocusImage m4 : 46|1@1+ (1,0) [0|1] ""  gtw
 SG_ APS_sw006_dasDisabled m6 : 46|1@1+ (1,0) [0|1] ""  gtw
 SG_ APS_sw042_cam_Autofix m42 : 46|1@1+ (1,0) [0|1] ""  gtw
 SG_ APS_sw069_drivingLaneLeft m69 : 46|8@1+ (1,0) [0|255] ""  gtw
 SG_ APS_sw053_a40whlStndStllValidty m53 : 46|1@1+ (1,0) [0|1] ""  gtw
 SG_ APS_sw015_SelfGlare m15 : 46|2@1+ (1,0) [0|3] ""  gtw
 SG_ APS_sw041_unusedW2 m41 : 46|18@1+ (1,0) [0|262143] ""  gtw
 SG_ APS_sw010_unusedBits m10 : 46|2@1+ (1,0) [0|3] ""  gtw
 SG_ APS_sw004_RadarMisalignment m4 : 45|1@1+ (1,0) [0|1] ""  gtw
 SG_ APS_sw006_stabilityControl m6 : 45|1@1+ (1,0) [0|1] ""  gtw
 SG_ APS_sw042_cam_PartialBlock m42 : 45|1@1+ (1,0) [0|1] ""  gtw
 SG_ APS_sw231_targetRelAcceleration m231 : 45|8@1+ (0.1,-12.8) [-12.8|12.7] "m/s2"  gtw
 SG_ APS_sw053_a39whlSpdValidity m53 : 45|1@1+ (1,0) [0|1] ""  gtw
 SG_ APS_sw006_gear m6 : 44|1@1+ (1,0) [0|1] ""  gtw
 SG_ APS_sw067_vehSpeed m67 : 44|12@1+ (0.1,-50) [-50|359.6] "kph"  gtw
 SG_ APS_sw005_RadarLowVisibility m5 : 44|1@1+ (1,0) [0|1] ""  gtw
 SG_ APS_sw194_reasonForHold m194 : 44|4@1+ (1,0) [0|15] ""  gtw
 SG_ APS_sw071_airSuspension m71 : 44|3@1+ (1,0) [0|7] ""  gtw
 SG_ APS_sw053_a38whlRotValidity m53 : 44|1@1+ (1,0) [0|1] ""  gtw
 SG_ APS_sw042_cam_SmearedSpots m42 : 44|1@1+ (1,0) [0|1] ""  gtw
 SG_ APS_sw015_ImpairedVD m15 : 44|2@1+ (1,0) [0|3] ""  gtw
 SG_ APS_sw004_RadarLowVisibility m4 : 44|1@1+ (1,0) [0|1] ""  gtw
 SG_ APS_sw129_minThreshold m129 : 43|13@1+ (1,0) [0|4500] "mV"  gtw
 SG_ APS_sw004_CamWatchdog m4 : 43|1@1+ (1,0) [0|1] ""  gtw
 SG_ APS_sw026_uds_mean_utilization m26 : 43|7@1+ (1,0) [0|127] "percent"  gtw
 SG_ APS_sw042_cam_LowSun m42 : 43|1@1+ (1,0) [0|1] ""  gtw
 SG_ APS_sw053_a37vinValidity m53 : 43|1@1+ (1,0) [0|1] ""  gtw
 SG_ APS_sw080_ego_speed m80 : 43|5@1+ (1,0) [0|31] "mph"  gtw
 SG_ APS_sw005_AutofixOutOfCalibHorzn m5 : 43|1@1+ (1,0) [0|1] ""  gtw
 SG_ APS_sw071_driverPresent m71 : 43|1@1+ (1,0) [0|1] ""  gtw
 SG_ APS_sw006_speed m6 : 43|1@1+ (1,0) [0|1] ""  gtw
 SG_ APS_sw005_camWatchdog m5 : 42|1@1+ (1,0) [0|1] ""  gtw
 SG_ APS_sw053_a36vehStndStllValidty m53 : 42|1@1+ (1,0) [0|1] ""  gtw
 SG_ APS_sw006_steeringAngleRate m6 : 42|1@1+ (1,0) [0|1] ""  gtw
 SG_ APS_sw138_gpsCfgIdFail m138 : 42|6@1+ (1,0) [0|63] ""  gtw
 SG_ APS_sw062_unusedBits m62 : 42|6@1+ (1,0) [0|63] ""  gtw
 SG_ APS_sw004_CamObjectsMIA m4 : 42|1@1+ (1,0) [0|1] ""  gtw
 SG_ APS_sw015_SunRay m15 : 42|2@1+ (1,0) [0|3] ""  gtw
 SG_ APS_sw042_cam_BlurredImage m42 : 42|1@1+ (1,0) [0|1] ""  gtw
 SG_ APS_sw012_mespFatalErrDetails m12 : 42|8@1+ (1,0) [0|255] ""  gtw
 SG_ APS_sw069_roadClass m69 : 42|4@1+ (1,0) [0|15] ""  gtw
 SG_ APS_sw042_cam_RoadSpray m42 : 41|1@1+ (1,0) [0|1] ""  gtw
 SG_ APS_sw053_a35indctrValidity m53 : 41|1@1+ (1,0) [0|1] ""  gtw
 SG_ APS_sw004_CamCommonMIA m4 : 41|1@1+ (1,0) [0|1] ""  gtw
 SG_ APS_sw138_gpsCfgNack m138 : 41|1@1+ (1,0) [0|1] ""  gtw
 SG_ APS_sw203_startDistance m203 : 41|11@1+ (1,0) [0|2047] "cm"  gtw
 SG_ APS_sw006_steeringAngle m6 : 41|1@1+ (1,0) [0|1] ""  gtw
 SG_ APS_sw085_rightLaneExist m85 : 41|6@1+ (2,0) [0|128] "%"  gtw
 SG_ APS_sw005_speedDerivative m5 : 41|1@1+ (1,0) [0|1] ""  gtw
 SG_ APS_sw199_currentSpeed m199 : 40|8@1+ (0.1,-12.2) [-12.2|12.2] "mph"  gtw
 SG_ APS_sw004_appMobileyeNotInVision m4 : 40|1@1+ (1,0) [0|1] ""  gtw
 SG_ APS_sw202_vehicleSpeed m202 : 40|12@1+ (0.1,0) [0|409.6] "kph"  gtw
 SG_ APS_sw016_hostSpeed m16 : 40|8@1+ (1,0) [0|255] "kph"  gtw
 SG_ APS_sw071_roadClass m71 : 40|3@1+ (1,0) [0|7] ""  gtw
 SG_ APS_sw063_detectedMinorVer m63 : 40|8@1+ (1,0) [0|255] ""  gtw
 SG_ APS_sw073_freespaceLeftC1 m73 : 40|8@1+ (0.0016,-0.2) [-0.2|0.2] "rad"  gtw
 SG_ APS_sw040_epas_internal_sas m40 : 40|8@1+ (1,-128) [-128|127] "deg"  gtw
 SG_ APS_sw130_tempSensorId m130 : 40|8@1+ (1,0) [0|255] ""  gtw
 SG_ APS_sw021_currentTemperature m21 : 40|8@1- (1,0) [-128|127] "degC"  gtw
 SG_ APS_sw005_dasDisabled m5 : 40|1@1+ (1,0) [0|1] ""  gtw
 SG_ APS_sw081_cameraTTC m81 : 40|8@1+ (0.02,0) [0|5.11] "seconds"  gtw
 SG_ APS_sw074_ipsoRCS m74 : 40|8@1+ (1,0) [0|255] "dB"  gtw
 SG_ APS_sw013_numNaksReceived m13 : 40|8@1+ (1,0) [0|255] ""  gtw
 SG_ APS_sw025_offsetSide m25 : 40|2@1+ (1,0) [0|3] ""  gtw
 SG_ APS_sw082_R_Lane m82 : 40|8@1+ (0.05,-6.4) [-6.4|6.35] "m"  gtw
 SG_ APS_sw060_hostSpeed m60 : 40|7@1+ (2,0) [0|254] "kph"  gtw
 SG_ APS_sw070_currentSpeed m70 : 40|12@1+ (0.1,-204.7) [-204.7|204.8] "mph"  gtw
 SG_ APS_sw205_rrMiddle m205 : 40|8@1+ (1,0) [0|255] "cm"  gtw
 SG_ APS_sw195_vehicleSpeed m195 : 40|12@1+ (0.1,0) [0|409.6] "kph"  gtw
 SG_ APS_sw051_unusedB0 m51 : 40|8@1+ (1,0) [0|255] ""  gtw
 SG_ APS_sw050_hostSpeed m50 : 40|8@1+ (1,0) [0|255] "kph"  gtw
 SG_ APS_sw204_frRight m204 : 40|8@1+ (1,0) [0|255] "cm"  gtw
 SG_ APS_sw138_PFLASHWriteError m138 : 40|1@1+ (1,0) [0|1] ""  gtw
 SG_ APS_sw054_unusedByte m54 : 40|8@1+ (1,0) [0|255] ""  gtw
 SG_ APS_sw201_vehSpeed m201 : 40|8@1+ (1,0) [0|255] "kph"  gtw
 SG_ APS_sw086_ellipseOverlap m86 : 40|8@1+ (0.1,-12.5) [-12.5|12.5] "m"  gtw
 SG_ APS_sw194_numPedstrian m194 : 40|4@1+ (1,0) [0|15] ""  gtw
 SG_ APS_sw053_a34steerAngSpdValidity m53 : 40|1@1+ (1,0) [0|1] ""  gtw
 SG_ APS_sw017_numTransportErrors m17 : 40|8@1+ (1,0) [0|255] ""  gtw
 SG_ APS_sw006_brakePedal m6 : 40|1@1+ (1,0) [0|1] ""  gtw
 SG_ APS_sw076_hostSpeed m76 : 40|8@1+ (1,0) [0|255] "kph"  gtw
 SG_ APS_sw227_ambientTemperature m227 : 40|8@1+ (0.5,-40) [-40|87.5] "C"  gtw
 SG_ APS_sw027_Unused_Byte m27 : 40|8@1+ (1,0) [0|255] ""  gtw
 SG_ APS_sw068_navigationSTW m68 : 40|14@1+ (0.1,-819.2) [-819.2|819.2] "deg"  gtw
 SG_ APS_sw084_ipsoDy m84 : 40|8@1+ (0.1,-12.6) [-12.6|12.9] "meters"  gtw
 SG_ APS_sw078_radarTarg5_VxRel m78 : 40|8@1+ (0.2,-25.6) [-25.6|25.4] "m/s"  gtw
 SG_ APS_sw042_cam_SunRay m42 : 40|1@1+ (1,0) [0|1] ""  gtw
 SG_ APS_sw080_road_class m80 : 40|3@1+ (1,0) [0|7] ""  gtw
 SG_ APS_sw103_objectDz m103 : 40|8@1+ (0.25,-5) [-5|10.75] "m"  gtw
 SG_ APS_sw015_FoggyLights m15 : 40|2@1+ (1,0) [0|3] ""  gtw
 SG_ APS_sw134_timeSinceLastMsg m134 : 40|16@1+ (1,0) [0|65535] ""  gtw
 SG_ APS_sw053_a33steerAngValidity m53 : 39|1@1+ (1,0) [0|1] ""  gtw
 SG_ APS_sw027_Unused_Bit_4 m27 : 39|1@1+ (1,0) [0|1] ""  gtw
 SG_ APS_sw195_sdiSystemStatus m195 : 39|1@1+ (1,0) [0|1] ""  gtw
 SG_ APS_sw202_sdiSystemStatus m202 : 39|1@1+ (1,0) [0|1] ""  gtw
 SG_ APS_sw005_fcmSensitivity m5 : 39|1@1+ (1,0) [0|1] ""  gtw
 SG_ APS_sw138_PFLASHReadError m138 : 39|1@1+ (1,0) [0|1] ""  gtw
 SG_ APS_sw006_radSGUFailure m6 : 39|1@1+ (1,0) [0|1] ""  gtw
 SG_ APS_sw004_DASFeaturesDisabled m4 : 39|1@1+ (1,0) [0|1] ""  gtw
 SG_ APS_sw231_targetRelVelocity m231 : 39|6@1+ (0.5,0) [0|31.5] "m/s"  gtw
 SG_ APS_sw027_LVD_2v7_IO m27 : 38|1@1+ (1,0) [0|1] ""  gtw
 SG_ APS_sw138_esfWtMsgTimeout m138 : 38|1@1+ (1,0) [0|1] ""  gtw
 SG_ APS_sw015_SmearedHalos m15 : 38|2@1+ (1,0) [0|3] ""  gtw
 SG_ APS_sw006_radSensorBlind m6 : 38|1@1+ (1,0) [0|1] ""  gtw
 SG_ APS_sw004_diSpeedInvalid m4 : 38|1@1+ (1,0) [0|1] ""  gtw
 SG_ APS_sw025_bottsDotsUsage m25 : 38|2@1+ (1,0) [0|3] ""  gtw
 SG_ APS_sw053_a32gearValidity m53 : 38|1@1+ (1,0) [0|1] ""  gtw
 SG_ APS_sw005_accelPedal m5 : 38|1@1+ (1,0) [0|1] ""  gtw
 SG_ APS_sw005_longAccel m5 : 37|1@1+ (1,0) [0|1] ""  gtw
 SG_ APS_sw195_sdiSystemNoise m195 : 37|2@1+ (1,0) [0|3] ""  gtw
 SG_ APS_sw138_UARTtxFifoOverflow m138 : 37|1@1+ (1,0) [0|1] ""  gtw
 SG_ APS_sw053_a31odoValidity m53 : 37|1@1+ (1,0) [0|1] ""  gtw
 SG_ APS_sw004_accelerationInvalid m4 : 37|1@1+ (1,0) [0|1] ""  gtw
 SG_ APS_sw077_vehicleSpeed m77 : 37|10@1+ (0.05,-25) [-25|26.15] "MPH"  gtw
 SG_ APS_sw027_LVD_2v7_Flash m27 : 37|1@1+ (1,0) [0|1] ""  gtw
 SG_ APS_sw202_sdiSystemNoise m202 : 37|2@1+ (1,0) [0|3] ""  gtw
 SG_ APS_sw011_scaSteerAngle m11 : 37|10@1+ (0.1,-51.2) [-51.2|51.1] "deg"  gtw
 SG_ APS_sw006_radHWFailure m6 : 37|1@1+ (1,0) [0|1] ""  gtw
 SG_ APS_sw194_numObstacles m194 : 36|4@1+ (1,0) [0|15] ""  gtw
 SG_ APS_sw041_ego_speed m41 : 36|10@1+ (0.05,0) [0|51.15] "m/s"  gtw
 SG_ APS_sw025_modelUsage m25 : 36|2@1+ (1,0) [0|3] ""  gtw
 SG_ APS_sw026_can_mean_utilization m26 : 36|7@1+ (1,0) [0|127] "percent"  gtw
 SG_ APS_sw072_vehicleHeading m72 : 36|10@1+ (0.005,-2.56) [-2.56|2.55] "rad"  gtw
 SG_ APS_sw027_LVD_2v7_VREG m27 : 36|1@1+ (1,0) [0|1] ""  gtw
 SG_ APS_sw010_VerticalMisalignment m10 : 36|10@1+ (0.087977,-45) [-45|45.000471] "deg"  gtw
 SG_ APS_sw004_stwAngleInvalid m4 : 36|1@1+ (1,0) [0|1] ""  gtw
 SG_ APS_sw042_epas_error_code m42 : 36|4@1+ (1,0) [0|15] ""  gtw
 SG_ APS_sw006_radMia m6 : 36|1@1+ (1,0) [0|1] ""  gtw
 SG_ APS_sw053_a30longAccValidity m53 : 36|1@1+ (1,0) [0|1] ""  gtw
 SG_ APS_sw015_SmearedSpots m15 : 36|2@1+ (1,0) [0|3] ""  gtw
 SG_ APS_sw138_UARTrxFifoUnderflow m138 : 36|1@1+ (1,0) [0|1] ""  gtw
 SG_ APS_sw005_yaw m5 : 36|1@1+ (1,0) [0|1] ""  gtw
 SG_ APS_sw027_Unused_Bit_3 m27 : 35|1@1+ (1,0) [0|1] ""  gtw
 SG_ APS_sw005_blinkers m5 : 35|1@1+ (1,0) [0|1] ""  gtw
 SG_ APS_sw004_accelPedalInvalid m4 : 35|1@1+ (1,0) [0|1] ""  gtw
 SG_ APS_sw138_UARTrxFifoOverflow m138 : 35|1@1+ (1,0) [0|1] ""  gtw
 SG_ APS_sw085_leftLaneExist m85 : 35|6@1+ (2,0) [0|128] "%"  gtw
 SG_ APS_sw077_oocHeight m77 : 35|2@1+ (1,0) [0|3] ""  gtw
 SG_ APS_sw006_accelPedal m6 : 35|1@1+ (1,0) [0|1] ""  gtw
 SG_ APS_sw053_a29longAccOffValidity m53 : 35|1@1+ (1,0) [0|1] ""  gtw
 SG_ APS_sw015_Splashes m15 : 34|2@1+ (1,0) [0|3] ""  gtw
 SG_ APS_sw005_stabilityControl m5 : 34|1@1+ (1,0) [0|1] ""  gtw
 SG_ APS_sw138_UARTparityError m138 : 34|1@1+ (1,0) [0|1] ""  gtw
 SG_ APS_sw050_targetOverlap m50 : 34|6@1+ (0.1,0) [0|6.3] "m"  gtw
 SG_ APS_sw025_navigationUsage m25 : 34|2@1+ (1,0) [0|3] ""  gtw
 SG_ APS_sw027_Watchdog m27 : 34|1@1+ (1,0) [0|1] ""  gtw
 SG_ APS_sw012_mespFatalErrCode m12 : 34|8@1+ (1,0) [0|255] ""  gtw
 SG_ APS_sw004_diMIA m4 : 34|1@1+ (1,0) [0|1] ""  gtw
 SG_ APS_sw060_targetOverlap m60 : 34|6@1+ (0.1,0) [0|6.3] "m"  gtw
 SG_ APS_sw053_a28espValidity m53 : 34|1@1+ (1,0) [0|1] ""  gtw
 SG_ APS_sw006_seatbelt m6 : 34|1@1+ (1,0) [0|1] ""  gtw
 SG_ APS_sw016_targetOverlap m16 : 34|6@1+ (0.1,0) [0|6.3] "m"  gtw
 SG_ APS_sw076_targetOverlap m76 : 34|6@1+ (0.1,0) [0|6.3] "m"  gtw
 SG_ APS_sw051_unusedBits m51 : 34|6@1+ (1,0) [0|63] ""  gtw
 SG_ APS_sw004_diCruiseStateFault m4 : 33|1@1+ (1,0) [0|1] ""  gtw
 SG_ APS_sw005_gear m5 : 33|1@1+ (1,0) [0|1] ""  gtw
 SG_ APS_sw027_Unused_Bit_2 m27 : 33|1@1+ (1,0) [0|1] ""  gtw
 SG_ APS_sw051_SGUFail m51 : 33|1@1+ (1,0) [0|1] ""  gtw
 SG_ APS_sw138_wheelTickInvalidSrc m138 : 33|1@1+ (1,0) [0|1] ""  gtw
 SG_ APS_sw006_blinkers m6 : 33|1@1+ (1,0) [0|1] ""  gtw
 SG_ APS_sw134_appSummon m134 : 33|1@1+ (1,0) [0|1] ""  gtw
 SG_ APS_sw053_a27CntryCdValidity m53 : 33|1@1+ (1,0) [0|1] ""  gtw
 SG_ APS_sw203_slotSizeY m203 : 33|8@1+ (4,0) [0|1020] "cm"  gtw
 SG_ APS_sw204_frMiddle m204 : 32|8@1+ (1,0) [0|255] "cm"  gtw
 SG_ APS_sw037_unusedW0 m37 : 32|16@1+ (1,0) [0|65535] ""  gtw
 SG_ APS_sw046_errorCode m46 : 32|32@1+ (1,0) [0|4294967295] ""  gtw
 SG_ APS_sw213_startSpeed m213 : 32|10@1+ (0.1,-10) [-10|92.3] "m/s"  gtw
 SG_ APS_sw080_stw_angle_deg m80 : 32|8@1+ (1,0) [0|255] "deg"  gtw
 SG_ APS_sw130_minThreshold m130 : 32|8@1- (1,0) [-128|127] "degC"  gtw
 SG_ APS_sw158_timeSinceLastMsg m158 : 32|24@1+ (1,0) [0|16777215] ""  gtw
 SG_ APS_sw021_maxThreshold m21 : 32|8@1- (1,0) [-128|127] "degC"  gtw
 SG_ APS_sw056_unusedW0 m56 : 32|16@1+ (1,0) [0|65535] ""  gtw
 SG_ APS_sw074_ipsoDz m74 : 32|6@1+ (0.2,-6.4) [-6.4|6.2] "m"  gtw
 SG_ APS_sw030_unusedW0 m30 : 32|16@1+ (1,0) [0|65535] ""  gtw
 SG_ APS_sw020_unusedW1 m20 : 32|16@1+ (1,0) [0|65535] ""  gtw
 SG_ APS_sw013_numSeqErrors m13 : 32|8@1+ (1,0) [0|255] ""  gtw
 SG_ APS_sw083_Targ5_dx m83 : 32|12@1+ (0.0625,0) [0|255.9375] "m"  gtw
 SG_ APS_sw063_expectedMinorVer m63 : 32|8@1+ (1,0) [0|255] ""  gtw
 SG_ APS_sw200_startSpeed m200 : 32|10@1+ (0.1,-10) [-10|92.3] "m/s"  gtw
 SG_ APS_sw078_radarTarg5_dx m78 : 32|8@1+ (0.0625,0) [0|15.9375] "m"  gtw
 SG_ APS_sw058_unusedW0 m58 : 32|16@1+ (1,0) [0|65535] ""  gtw
 SG_ APS_sw053_a26brakeValidity m53 : 32|1@1+ (1,0) [0|1] ""  gtw
 SG_ APS_sw218_pedalPosition m218 : 32|7@1+ (1,0) [0|127] "%"  gtw
 SG_ APS_sw019_timeStamp m19 : 32|32@1+ (1,0) [0|4294967295] "ms"  gtw
 SG_ APS_sw085_roadClass m85 : 32|3@1+ (1,0) [0|7] ""  gtw
 SG_ APS_sw031_errorData1 m31 : 32|16@1+ (1,0) [0|65535] ""  gtw
 SG_ APS_sw070_temperature m70 : 32|8@1+ (0.5,-40) [-40|87.5] "C"  gtw
 SG_ APS_sw139_overflowBus m139 : 32|3@1+ (1,0) [0|5] ""  gtw
 SG_ APS_sw066_unusedW0 m66 : 32|16@1+ (1,0) [0|65535] ""  gtw
 SG_ APS_sw017_numSeqErrors m17 : 32|8@1+ (1,0) [0|255] ""  gtw
 SG_ APS_sw034_unusedW0 m34 : 32|16@1+ (1,0) [0|65535] ""  gtw
 SG_ APS_sw075_unusedW0 m75 : 32|16@1+ (1,0) [0|65535] ""  gtw
 SG_ APS_sw205_rrLeftMiddle m205 : 32|8@1+ (1,0) [0|255] "cm"  gtw
 SG_ APS_sw005_speed m5 : 32|1@1+ (1,0) [0|1] ""  gtw
 SG_ APS_sw028_highestSeqRcvd m28 : 32|16@1+ (1,0) [0|65535] ""  gtw
 SG_ APS_sw047_edrReturn m47 : 32|16@1+ (1,0) [0|65535] ""  gtw
 SG_ APS_sw202_sdiRearCC m202 : 32|5@1+ (1,0) [0|31] ""  gtw
 SG_ APS_sw103_objectDy m103 : 32|8@1+ (0.5,-15.5) [-15.5|16] "m"  gtw
 SG_ APS_sw231_targetDistance m231 : 32|7@1+ (0.1,0) [0|12.7] "m"  gtw
 SG_ APS_sw018_maxThreshold m18 : 32|15@1+ (1,50) [50|5500] "mV"  gtw
 SG_ APS_sw086_ellipseWidth m86 : 32|8@1+ (0.1,0) [0|25.5] "m"  gtw
 SG_ APS_sw049_app_version_msw m49 : 32|16@1+ (1,0) [0|65535] ""  gtw
 SG_ APS_sw006_SelfGlare m6 : 32|1@1+ (1,0) [0|1] ""  gtw
 SG_ APS_sw195_sdiRearCC m195 : 32|5@1+ (1,0) [0|31] ""  gtw
 SG_ APS_sw082_L_Lane m82 : 32|8@1+ (0.05,-6.4) [-6.4|6.35] "m"  gtw
 SG_ APS_sw012_bootDDRTempStatus m12 : 32|2@1+ (1,0) [0|3] ""  gtw
 SG_ APS_sw073_freespaceRightC0 m73 : 32|8@1+ (0.1,-12.8) [-12.8|12.7] "m"  gtw
 SG_ APS_sw015_AutofixOOfCalibHorizon m15 : 32|2@1+ (1,0) [0|3] ""  gtw
 SG_ APS_sw065_unusedW0 m65 : 32|16@1+ (1,0) [0|65535] ""  gtw
 SG_ APS_sw032_errorData1 m32 : 32|16@1+ (1,0) [0|65535] ""  gtw
 SG_ APS_sw044_timestampms m44 : 32|32@1+ (1,0) [0|4294967295] "ms"  gtw
 SG_ APS_sw134_dasChNm m134 : 32|1@1+ (1,0) [0|1] ""  gtw
 SG_ APS_sw022_errorCode m22 : 32|32@1+ (1,0) [0|4294967295] ""  gtw
 SG_ APS_sw084_ipsoDx m84 : 32|8@1+ (0.1,0) [0|25.5] "meters"  gtw
 SG_ APS_sw036_unusedW0 m36 : 32|16@1+ (1,0) [0|65535] ""  gtw
 SG_ APS_sw138_baudrateMismatch m138 : 32|1@1+ (1,0) [0|1] ""  gtw
 SG_ APS_sw062_VerticalMisalignment m62 : 32|10@1+ (0.087977,-45) [-45|45.000471] "deg"  gtw
 SG_ APS_sw077_oocCollisionSide m77 : 32|3@1+ (1,0) [0|7] ""  gtw
 SG_ APS_sw029_highestSeqRcvd m29 : 32|16@1+ (1,0) [0|65535] ""  gtw
 SG_ APS_sw043_mesp_health_main_state m43 : 32|16@1+ (1,0) [0|65535] ""  gtw
 SG_ APS_sw081_cameraDistance m81 : 32|8@1+ (0.0625,0) [0|15.9375] "m"  gtw
 SG_ APS_sw011_scaSonicDist m11 : 32|5@1+ (0.05,0) [0|1.5] "m"  gtw
 SG_ APS_sw024_taskProgramCounter m24 : 32|32@1+ (1,0) [0|4294967295] ""  gtw
 SG_ APS_sw001_APS_alertDataW1 m1 : 32|16@1+ (1,0) [0|65535] ""  gtw
 SG_ APS_sw207_lcUnavailableReason m207 : 32|8@1+ (1,0) [0|255] ""  gtw
 SG_ APS_sw051_HWFail m51 : 32|1@1+ (1,0) [0|1] ""  gtw
 SG_ APS_sw039_unusedW0 m39 : 32|16@1+ (1,0) [0|65535] ""  gtw
 SG_ APS_sw040_das_steering_req m40 : 32|8@1+ (1,-128) [-128|127] "deg"  gtw
 SG_ APS_sw201_timeHorizon m201 : 32|8@1+ (0.1,0) [0|25.5] "s"  gtw
 SG_ APS_sw027_LVD_1v2 m27 : 32|1@1+ (1,0) [0|1] ""  gtw
 SG_ APS_sw054_Autofix_yaw m54 : 32|8@1+ (1,0) [0|255] ""  gtw
 SG_ APS_sw042_state_before_abort m42 : 32|4@1+ (1,0) [0|15] ""  gtw
 SG_ APS_sw014_lineNumberInCode m14 : 32|16@1+ (1,0) [0|65535] ""  gtw
 SG_ APS_sw025_hppUsage m25 : 32|2@1+ (1,0) [0|3] ""  gtw
 SG_ APS_sw045_unusedW0 m45 : 32|16@1+ (1,0) [0|65535] ""  gtw
 SG_ APS_sw134_dasSteeringControlPty m134 : 31|1@1+ (1,0) [0|1] ""  gtw
 SG_ APS_sw053_a25ambTValidity m53 : 31|1@1+ (1,0) [0|1] ""  gtw
 SG_ APS_sw005_steeringAngleRate m5 : 31|1@1+ (1,0) [0|1] ""  gtw
 SG_ APS_sw138_wheeltickUARTfault m138 : 31|1@1+ (1,0) [0|1] ""  gtw
 SG_ APS_sw018_powerSequnceError m18 : 31|1@1+ (1,0) [0|1] ""  gtw
 SG_ APS_sw200_epasHandsOnDetected m200 : 31|1@1+ (1,0) [0|1] ""  gtw
 SG_ APS_sw213_epasHandsOnDetected m213 : 31|1@1+ (1,0) [0|1] ""  gtw
 SG_ APS_sw006_FoggyLights m6 : 31|1@1+ (1,0) [0|1] ""  gtw
 SG_ APS_sw006_SmearedHalos m6 : 30|1@1+ (1,0) [0|1] ""  gtw
 SG_ APS_sw071_endPosY m71 : 30|10@1+ (0.05,-25.6) [-25.6|25.5] "m"  gtw
 SG_ APS_sw015_AutofixOutOfCalibYaw m15 : 30|2@1+ (1,0) [0|3] ""  gtw
 SG_ APS_sw158_dasChNm m158 : 30|1@1+ (1,0) [0|1] ""  gtw
 SG_ APS_sw047_edrBlackBox m47 : 30|2@1+ (1,0) [0|3] ""  gtw
 SG_ APS_sw134_dasVisualDebug m134 : 30|1@1+ (1,0) [0|1] ""  gtw
 SG_ APS_sw138_invalidAsciiNMEA m138 : 30|1@1+ (1,0) [0|1] ""  gtw
 SG_ APS_sw067_epasSTW m67 : 30|14@1+ (0.1,-819.2) [-819.2|819] "deg"  gtw
 SG_ APS_sw194_leadVx m194 : 30|6@1- (0.2,0.0) [-6|6] "m/s"  gtw
 SG_ APS_sw053_a24absValidity m53 : 30|1@1+ (1,0) [0|1] ""  gtw
 SG_ APS_sw227_sensorMeasurement m227 : 30|9@1+ (1,0) [0|511] "cm"  gtw
 SG_ APS_sw069_torsionBar m69 : 30|12@1+ (0.01,-20.5) [-20.5|20.45] "Nm"  gtw
 SG_ APS_sw005_steeringAngle m5 : 30|1@1+ (1,0) [0|1] ""  gtw
 SG_ APS_sw129_maxThreshold m129 : 30|13@1+ (1,50) [50|5500] "mV"  gtw
 SG_ APS_sw006_FullBlockage m6 : 29|1@1+ (1,0) [0|1] ""  gtw
 SG_ APS_sw218_mcuAutosteerRestricted m218 : 29|1@1+ (1,0) [0|1] ""  gtw
 SG_ APS_sw158_dasSteeringControlPty m158 : 29|1@1+ (1,0) [0|1] ""  gtw
 SG_ APS_sw069_parkCal m69 : 29|1@1+ (1,0) [0|1] ""  gtw
 SG_ APS_sw025_vehiclesUsage m25 : 29|2@1+ (1,0) [0|3] ""  gtw
 SG_ APS_sw134_dasSteeringControl m134 : 29|1@1+ (1,0) [0|1] ""  gtw
 SG_ APS_sw053_a23sccmInvalidChkSm m53 : 29|1@1+ (1,0) [0|1] ""  gtw
 SG_ APS_sw138_emptyValidNMEA m138 : 29|1@1+ (1,0) [0|1] ""  gtw
 SG_ APS_sw005_brakePedal m5 : 29|1@1+ (1,0) [0|1] ""  gtw
 SG_ APS_sw018_railID m18 : 29|2@1+ (1,0) [0|3] ""  gtw
 SG_ APS_sw070_accRail m70 : 28|1@1+ (1,0) [0|1] ""  gtw
 SG_ APS_sw005_radCalibration m5 : 28|1@1+ (1,0) [0|1] ""  gtw
 SG_ APS_sw015_AutofixOutOfCalib m15 : 28|2@1+ (1,0) [0|3] ""  gtw
 SG_ APS_sw006_AutofixOutOfCalibYaw m6 : 28|1@1+ (1,0) [0|1] ""  gtw
 SG_ APS_sw048_parkerIssue m48 : 28|1@1+ (1,0) [0|1] ""  gtw
 SG_ APS_sw057_phoneLocStatusMia m57 : 28|1@1+ (1,0) [0|1] ""  gtw
 SG_ APS_sw158_dasVisualDebug m158 : 28|1@1+ (1,0) [0|1] ""  gtw
 SG_ APS_sw027_Unused_Nibble m27 : 28|4@1+ (1,0) [0|15] ""  gtw
 SG_ APS_sw004_appMobileyeStatus m4 : 28|5@1+ (1,0) [0|31] ""  gtw
 SG_ APS_sw053_a22sccmInvalidChkSm m53 : 28|1@1+ (1,0) [0|1] ""  gtw
 SG_ APS_sw134_dasStatus2 m134 : 28|1@1+ (1,0) [0|1] ""  gtw
 SG_ APS_sw044_meMainState m44 : 28|4@1+ (1,0) [0|15] ""  gtw
 SG_ APS_sw138_UBXrxFrameTooBig m138 : 28|1@1+ (1,0) [0|1] ""  gtw
 SG_ APS_sw057_hvacRequest m57 : 27|1@1+ (1,0) [0|1] ""  gtw
 SG_ APS_sw005_radMia m5 : 27|1@1+ (1,0) [0|1] ""  gtw
 SG_ APS_sw053_a21espInvalidChkSm m53 : 27|1@1+ (1,0) [0|1] ""  gtw
 SG_ APS_sw070_driveRail m70 : 27|1@1+ (1,0) [0|1] ""  gtw
 SG_ APS_sw134_dasStatus m134 : 27|1@1+ (1,0) [0|1] ""  gtw
 SG_ APS_sw027_f_PLL_1_Off m27 : 27|1@1+ (1,0) [0|1] ""  gtw
 SG_ APS_sw048_camIssue m48 : 27|1@1+ (1,0) [0|1] ""  gtw
 SG_ APS_sw158_dasSteeringControl m158 : 27|1@1+ (1,0) [0|1] ""  gtw
 SG_ APS_sw006_AutofixOutOfCalibHorzn m6 : 27|1@1+ (1,0) [0|1] ""  gtw
 SG_ APS_sw138_UARTframeError m138 : 27|1@1+ (1,0) [0|1] ""  gtw
 SG_ APS_sw059_oocStatus m59 : 27|1@1+ (1,0) [0|1] ""  gtw
 SG_ APS_sw230_sensor12Blocked m230 : 27|1@1+ (1,0) [0|1] ""  gtw
 SG_ APS_sw025_rightLaneUsage m25 : 27|2@1+ (1,0) [0|3] ""  gtw
 SG_ APS_sw026_execution_time m26 : 27|9@1+ (0.125,0) [0|65.411] "ms"  gtw
 SG_ APS_sw138_UARTbusFull m138 : 26|1@1+ (1,0) [0|1] ""  gtw
 SG_ APS_sw199_currentSTW m199 : 26|14@1+ (0.1,-819.2) [-819.2|819] "deg"  gtw
 SG_ APS_sw015_PartialBlockage m15 : 26|2@1+ (1,0) [0|3] ""  gtw
 SG_ APS_sw041_max_rate m41 : 26|10@1- (1,0) [-512|511] "deg/s"  gtw
 SG_ APS_sw006_AutofixOutOfCalib m6 : 26|1@1+ (1,0) [0|1] ""  gtw
 SG_ APS_sw017_numCrcErrors m17 : 26|6@1+ (1,0) [0|63] ""  gtw
 SG_ APS_sw068_virtualLaneSTW m68 : 26|14@1+ (0.1,-819.2) [-819.2|819.2] "deg"  gtw
 SG_ APS_sw151_parkerType m151 : 26|1@1+ (1,0) [0|1] ""  gtw
 SG_ APS_sw059_oloDict m59 : 26|1@1+ (1,0) [0|1] ""  gtw
 SG_ APS_sw230_sensor11Blocked m230 : 26|1@1+ (1,0) [0|1] ""  gtw
 SG_ APS_sw027_Unused_Bit_1 m27 : 26|1@1+ (1,0) [0|1] ""  gtw
 SG_ APS_sw134_dasPscControl m134 : 26|1@1+ (1,0) [0|1] ""  gtw
 SG_ APS_sw053_a20bdyInvalidChkSm m53 : 26|1@1+ (1,0) [0|1] ""  gtw
 SG_ APS_sw057_odo m57 : 26|1@1+ (1,0) [0|1] ""  gtw
 SG_ APS_sw005_radSGUFailure m5 : 26|1@1+ (1,0) [0|1] ""  gtw
 SG_ APS_sw158_dasStatus2 m158 : 26|1@1+ (1,0) [0|1] ""  gtw
 SG_ APS_sw072_vehicleY m72 : 26|10@1+ (0.05,-25.6) [-25.6|25.5] "m"  gtw
 SG_ APS_sw048_eyeQVersionMismatch m48 : 26|1@1+ (1,0) [0|1] ""  gtw
 SG_ APS_sw025_leftLaneUsage m25 : 25|2@1+ (1,0) [0|3] ""  gtw
 SG_ APS_sw006_PartialBlockage m6 : 25|1@1+ (1,0) [0|1] ""  gtw
 SG_ APS_sw077_oocConfidence m77 : 25|7@1+ (1,0) [0|100] "%"  gtw
 SG_ APS_sw017_Any_TFL_Msg_Recd m17 : 25|1@1+ (1,0) [0|1] ""  gtw
 SG_ APS_sw050_targetRelSpeed m50 : 25|9@1+ (0.0625,-31) [-31|0.9375] "m/s"  gtw
 SG_ APS_sw203_slotSizeX m203 : 25|8@1+ (4,0) [0|1020] "cm"  gtw
 SG_ APS_sw057_cruiseControl m57 : 25|1@1+ (1,0) [0|1] ""  gtw
 SG_ APS_sw230_sensor10Blocked m230 : 25|1@1+ (1,0) [0|1] ""  gtw
 SG_ APS_sw158_dasStatus m158 : 25|1@1+ (1,0) [0|1] ""  gtw
 SG_ APS_sw060_targetRelSpeed m60 : 25|9@1+ (0.0625,-31) [-31|0.9375] "m/s"  gtw
 SG_ APS_sw027_PLL_1_Failure m27 : 25|1@1+ (1,0) [0|1] ""  gtw
 SG_ APS_sw076_targetRelSpeed m76 : 25|9@1+ (0.0625,-31) [-31|0.9375] "m/s"  gtw
 SG_ APS_sw069_diAPState m69 : 25|4@1+ (1,0) [0|9] ""  gtw
 SG_ APS_sw005_radSensorBlind m5 : 25|1@1+ (1,0) [0|1] ""  gtw
 SG_ APS_sw016_targetRelSpeed m16 : 25|9@1+ (0.0625,-31) [-31|0.9375] "m/s"  gtw
 SG_ APS_sw059_status2 m59 : 25|1@1+ (1,0) [0|1] ""  gtw
 SG_ APS_sw218_handsOnState m218 : 25|4@1+ (1,0) [0|15] ""  gtw
 SG_ APS_sw133_unused m133 : 25|39@1+ (1,0) [0|549755813887] ""  gtw
 SG_ APS_sw048_radcMia m48 : 25|1@1+ (1,0) [0|1] ""  gtw
 SG_ APS_sw134_dasObject m134 : 25|1@1+ (1,0) [0|1] ""  gtw
 SG_ APS_sw231_predImpactVelocity m231 : 25|7@1+ (0.5,0) [0|63.5] "m/s"  gtw
 SG_ APS_sw053_a19sccmInvalidCount m53 : 25|1@1+ (1,0) [0|1] ""  gtw
 SG_ APS_sw138_unexpectedNMEAmsg m138 : 25|1@1+ (1,0) [0|1] ""  gtw
 SG_ APS_sw045_unusedByte m45 : 24|8@1+ (1,0) [0|255] ""  gtw
 SG_ APS_sw086_distanceEllipse m86 : 24|8@1+ (0.5,0) [0|127.5] "m"  gtw
 SG_ APS_sw202_sdiFrontCC m202 : 24|5@1+ (1,0) [0|31] ""  gtw
 SG_ APS_sw017_Any_Objects_Msg_Recd m17 : 24|1@1+ (1,0) [0|1] ""  gtw
 SG_ APS_sw066_mobileye_main_state m66 : 24|8@1+ (1,0) [0|255] ""  gtw
 SG_ APS_sw080_rad_tar_5_dist m80 : 24|6@1+ (1,0) [0|63] "m"  gtw
 SG_ APS_sw047_edrType m47 : 24|6@1+ (1,0) [0|63] ""  gtw
 SG_ APS_sw040_ego_veh_speed m40 : 24|8@1+ (0.2,0) [0|51] "m/s"  gtw
 SG_ APS_sw015_FullBlockage m15 : 24|2@1+ (1,0) [0|3] ""  gtw
 SG_ APS_sw082_R_VL m82 : 24|8@1+ (0.05,-6.4) [-6.4|6.35] "m"  gtw
 SG_ APS_sw139_numMessagesDropped m139 : 24|8@1+ (1,0) [0|255] ""  gtw
 SG_ APS_sw056_unusedByte m56 : 24|8@1+ (1,0) [0|255] ""  gtw
 SG_ APS_sw051_SCUTemperature m51 : 24|8@1- (1,0) [-128|127] ""  gtw
 SG_ APS_sw030_unusedByte m30 : 24|8@1+ (1,0) [0|255] ""  gtw
 SG_ APS_sw044_appStatus m44 : 24|4@1+ (1,0) [0|15] ""  gtw
 SG_ APS_sw011_scaSpeed m11 : 24|7@1+ (1,0) [0|127] "MPH"  gtw
 SG_ APS_sw021_minThreshold m21 : 24|8@1- (1,0) [-128|127] "degC"  gtw
 SG_ APS_sw081_radarTTC m81 : 24|8@1+ (0.02,0) [0|5.11] "seconds"  gtw
 SG_ APS_sw070_diGear m70 : 24|3@1+ (1,0) [0|7] ""  gtw
 SG_ APS_sw074_ipsoDy m74 : 24|6@1+ (0.1,-3.2) [-3.2|3.1] "m"  gtw
 SG_ APS_sw019_numFreeBytes m19 : 24|8@1+ (1,-191) [-191|64] "# of bytes"  gtw
 SG_ APS_sw059_pscVehSlot m59 : 24|1@1+ (1,0) [0|1] ""  gtw
 SG_ APS_sw036_unusedByte m36 : 24|8@1+ (1,0) [0|255] ""  gtw
 SG_ APS_sw042_view_range m42 : 24|8@1+ (1,0) [0|255] ""  gtw
 SG_ APS_sw065_mobileye_main_state m65 : 24|8@1+ (1,0) [0|255] ""  gtw
 SG_ APS_sw084_ipsoRCS m84 : 24|8@1+ (1,0) [0|255] ""  gtw
 SG_ APS_sw160_actualHash m160 : 24|24@1+ (1,0) [0|16777215] ""  gtw
 SG_ APS_sw073_freespaceLeftC0 m73 : 24|8@1+ (0.1,-12.8) [-12.8|12.7] "m"  gtw
 SG_ APS_sw132_actualHash m132 : 24|24@1+ (1,0) [0|16777215] ""  gtw
 SG_ APS_sw151_recoveryPathway m151 : 24|2@1+ (1,0) [0|3] ""  gtw
 SG_ APS_sw039_unusedByte m39 : 24|8@1+ (1,0) [0|255] ""  gtw
 SG_ APS_sw204_frLeftMiddle m204 : 24|8@1+ (1,0) [0|255] "cm"  gtw
 SG_ APS_sw133_switchInReset m133 : 24|1@1+ (1,0) [0|1] ""  gtw
 SG_ APS_sw054_Autofix_horizon m54 : 24|8@1+ (1,0) [0|255] ""  gtw
 SG_ APS_sw032_errorType m32 : 24|8@1+ (1,0) [0|255] ""  gtw
 SG_ APS_sw063_detectedMajorVer m63 : 24|8@1+ (1,0) [0|255] ""  gtw
 SG_ APS_sw195_sdiFrontCC m195 : 24|5@1+ (1,0) [0|31] ""  gtw
 SG_ APS_sw048_radcCalibration m48 : 24|1@1+ (1,0) [0|1] ""  gtw
 SG_ APS_sw218_drivingOnHighway m218 : 24|1@1+ (1,0) [0|1] ""  gtw
 SG_ APS_sw207_eyeq3MainState m207 : 24|8@1+ (1,0) [0|255] ""  gtw
 SG_ APS_sw137_exitTransportMode m137 : 24|1@1+ (1,0) [0|1] ""  gtw
 SG_ APS_sw013_numCrcErrors m13 : 24|8@1+ (1,0) [0|255] ""  gtw
 SG_ APS_sw005_radHWFailure m5 : 24|1@1+ (1,0) [0|1] ""  gtw
 SG_ APS_sw103_objectRCS m103 : 24|8@1+ (1,0) [0|255] ""  gtw
 SG_ APS_sw037_issue m37 : 24|8@1+ (1,0) [0|255] ""  gtw
 SG_ APS_sw158_dasPscControl m158 : 24|1@1+ (1,0) [0|1] ""  gtw
 SG_ APS_sw134_dasLanes m134 : 24|1@1+ (1,0) [0|1] ""  gtw
 SG_ APS_sw025_controlled_access m25 : 24|1@1+ (1,0) [0|1] ""  gtw
 SG_ APS_sw230_sensor9Blocked m230 : 24|1@1+ (1,0) [0|1] ""  gtw
 SG_ APS_sw024_currentVehicleApp m24 : 24|8@1+ (1,0) [0|255] ""  gtw
 SG_ APS_sw058_unusedByte m58 : 24|8@1+ (1,0) [0|255] ""  gtw
 SG_ APS_sw027_Flash_Fatal_Error m27 : 24|1@1+ (1,0) [0|1] ""  gtw
 SG_ APS_sw006_SmearedSpots m6 : 24|1@1+ (1,0) [0|1] ""  gtw
 SG_ APS_sw075_unusedByte m75 : 24|8@1+ (1,0) [0|255] ""  gtw
 SG_ APS_sw078_ttc m78 : 24|8@1+ (0.02,0) [0|5.11] "seconds"  gtw
 SG_ APS_sw205_rrLeft m205 : 24|8@1+ (1,0) [0|255] "cm"  gtw
 SG_ APS_sw201_stwAngleReq m201 : 24|8@1- (1,0) [-128|127] "deg"  gtw
 SG_ APS_sw034_unusedByte m34 : 24|8@1+ (1,0) [0|255] ""  gtw
 SG_ APS_sw138_NMEAinvalidChecksum m138 : 24|1@1+ (1,0) [0|1] ""  gtw
 SG_ APS_sw130_maxThreshold m130 : 24|8@1- (1,0) [-128|127] "degC"  gtw
 SG_ APS_sw057_vehicleModes m57 : 24|1@1+ (1,0) [0|1] ""  gtw
 SG_ APS_sw085_radarTTC m85 : 24|8@1+ (0.02,0) [0|5.11] "seconds"  gtw
 SG_ APS_sw053_a18espInvalidCount m53 : 24|1@1+ (1,0) [0|1] ""  gtw
 SG_ APS_sw031_errorType m31 : 24|8@1+ (1,0) [0|255] ""  gtw
 SG_ APS_sw004_accState m4 : 24|4@1+ (1,0) [0|15] ""  gtw
 SG_ APS_sw230_sensor8Blocked m230 : 23|1@1+ (1,0) [0|1] ""  gtw
 SG_ APS_sw047_controlledAccess m47 : 23|1@1+ (1,0) [0|1] ""  gtw
 SG_ APS_sw011_scaThreshold m11 : 23|1@1+ (1,0) [0|1] ""  gtw
 SG_ APS_sw080_pedestrian_check m80 : 23|1@1+ (1,0) [0|1] ""  gtw
 SG_ APS_sw027_LVD_4v5 m27 : 23|1@1+ (1,0) [0|1] ""  gtw
 SG_ APS_sw017_Any_Lanes_Msg_Recd m17 : 23|1@1+ (1,0) [0|1] ""  gtw
 SG_ APS_sw025_road_match m25 : 23|1@1+ (1,0) [0|1] ""  gtw
 SG_ APS_sw052_sensorBlocked m52 : 23|1@1+ (1,0) [0|1] ""  gtw
 SG_ APS_sw138_mcuFwdNMEAfail m138 : 23|1@1+ (1,0) [0|1] ""  gtw
 SG_ APS_sw006_LowSun m6 : 23|1@1+ (1,0) [0|1] ""  gtw
 SG_ APS_sw158_dasObject m158 : 23|1@1+ (1,0) [0|1] ""  gtw
 SG_ APS_sw059_pscStatus m59 : 23|1@1+ (1,0) [0|1] ""  gtw
 SG_ APS_sw005_camFcwPcwMsg m5 : 23|1@1+ (1,0) [0|1] ""  gtw
 SG_ APS_sw137_wheelTickCfgMissmatch m137 : 23|1@1+ (1,0) [0|1] ""  gtw
 SG_ APS_sw048_radcVersionMismatch m48 : 23|1@1+ (1,0) [0|1] ""  gtw
 SG_ APS_sw134_dasIntSafetyFrontPty m134 : 23|1@1+ (1,0) [0|1] ""  gtw
 SG_ APS_sw053_a17adasInvalidCount m53 : 23|1@1+ (1,0) [0|1] ""  gtw
 SG_ APS_sw057_solarData m57 : 23|1@1+ (1,0) [0|1] ""  gtw
 SG_ APS_sw203_roadClass m203 : 22|3@1+ (1,0) [0|7] ""  gtw
 SG_ APS_sw004_espMIA m4 : 22|1@1+ (1,0) [0|1] ""  gtw
 SG_ APS_sw059_pasRearMiddle m59 : 22|1@1+ (1,0) [0|1] ""  gtw
 SG_ APS_sw057_chassisControl m57 : 22|1@1+ (1,0) [0|1] ""  gtw
 SG_ APS_sw137_esfStatusMsgMIA m137 : 22|1@1+ (1,0) [0|1] ""  gtw
 SG_ APS_sw053_a16bdyInvalidCount m53 : 22|1@1+ (1,0) [0|1] ""  gtw
 SG_ APS_sw052_rspError m52 : 22|1@1+ (1,0) [0|1] ""  gtw
 SG_ APS_sw194_leadDx m194 : 22|8@1+ (0.1,0) [0|25] "m"  gtw
 SG_ APS_sw138_mcuDbgMsgTooBig m138 : 22|1@1+ (1,0) [0|1] ""  gtw
 SG_ APS_sw080_freespace_check m80 : 22|1@1+ (1,0) [0|1] ""  gtw
 SG_ APS_sw048_ecuReset m48 : 22|1@1+ (1,0) [0|1] ""  gtw
 SG_ APS_sw158_dasLanes m158 : 22|1@1+ (1,0) [0|1] ""  gtw
 SG_ APS_sw140_okToUseHighPower m140 : 22|1@1+ (1,0) [0|1] ""  gtw
 SG_ APS_sw230_sensor7Blocked m230 : 22|1@1+ (1,0) [0|1] ""  gtw
 SG_ APS_sw005_camCommonMsg m5 : 22|1@1+ (1,0) [0|1] ""  gtw
 SG_ APS_sw073_freespaceLDW m73 : 22|2@1+ (1,0) [0|3] ""  gtw
 SG_ APS_sw006_BlurredImage m6 : 22|1@1+ (1,0) [0|1] ""  gtw
 SG_ APS_sw015_BlurredImage m15 : 22|2@1+ (1,0) [0|3] ""  gtw
 SG_ APS_sw027_Clock_Monitor_0_Off m27 : 22|1@1+ (1,0) [0|1] ""  gtw
 SG_ APS_sw193_smearedSpots m193 : 22|1@1+ (1,0) [0|1] ""  gtw
 SG_ APS_sw017_Camera_Msg_TFL_MIA m17 : 22|1@1+ (1,0) [0|1] ""  gtw
 SG_ APS_sw038_TooManyResets m38 : 22|1@1+ (1,0) [0|1] ""  gtw
 SG_ APS_sw134_dasControlPty m134 : 22|1@1+ (1,0) [0|1] ""  gtw
 SG_ APS_sw134_dasControl m134 : 21|1@1+ (1,0) [0|1] ""  gtw
 SG_ APS_sw052_chirpError m52 : 21|1@1+ (1,0) [0|1] ""  gtw
 SG_ APS_sw051_unused m51 : 21|3@1+ (1,0) [0|7] ""  gtw
 SG_ APS_sw195_s12Blocked m195 : 21|1@1+ (1,0) [0|1] ""  gtw
 SG_ APS_sw017_Camera_Msg_FCW_PCW_MIA m17 : 21|1@1+ (1,0) [0|1] ""  gtw
 SG_ APS_sw006_Splashes m6 : 21|1@1+ (1,0) [0|1] ""  gtw
 SG_ APS_sw193_smearedHalos m193 : 21|1@1+ (1,0) [0|1] ""  gtw
 SG_ APS_sw069_eacStatus m69 : 21|4@1+ (1,0) [0|15] ""  gtw
 SG_ APS_sw038_FullBlockage m38 : 21|1@1+ (1,0) [0|1] ""  gtw
 SG_ APS_sw200_endSpeed m200 : 21|10@1+ (0.1,-10) [-10|92.3] "m/s"  gtw
 SG_ APS_sw027_Clock_Monitor_0_Low m27 : 21|1@1+ (1,0) [0|1] ""  gtw
 SG_ APS_sw005_camObjHeader m5 : 21|1@1+ (1,0) [0|1] ""  gtw
 SG_ APS_sw202_s12Blocked m202 : 21|1@1+ (1,0) [0|1] ""  gtw
 SG_ APS_sw138_mcuDbgMsgInvalid m138 : 21|1@1+ (1,0) [0|1] ""  gtw
 SG_ APS_sw213_endSpeed m213 : 21|10@1+ (0.1,-10) [-10|92.3] "m/s"  gtw
 SG_ APS_sw004_radDynamicsError m4 : 21|1@1+ (1,0) [0|1] ""  gtw
 SG_ APS_sw199_abortCodePARK m199 : 21|5@1+ (1,0) [0|31] ""  gtw
 SG_ APS_sw080_ultrasonic_obs_check m80 : 21|1@1+ (1,0) [0|1] ""  gtw
 SG_ APS_sw011_scaBlinker m11 : 21|2@1+ (1,0) [0|3] ""  gtw
 SG_ APS_sw053_a15adasMIA m53 : 21|1@1+ (1,0) [0|1] ""  gtw
 SG_ APS_sw137_gpsCfgFail m137 : 21|1@1+ (1,0) [0|1] ""  gtw
 SG_ APS_sw151_diGear m151 : 21|3@1+ (1,0) [0|7] ""  gtw
 SG_ APS_sw230_sensor6Blocked m230 : 21|1@1+ (1,0) [0|1] ""  gtw
 SG_ APS_sw140_coolant m140 : 21|1@1+ (1,0) [0|1] ""  gtw
 SG_ APS_sw158_dasIntSafetyFrontPty m158 : 21|1@1+ (1,0) [0|1] ""  gtw
 SG_ APS_sw048_ecuWatchdog m48 : 21|1@1+ (1,0) [0|1] ""  gtw
 SG_ APS_sw028_unusedBits m28 : 21|11@1+ (1,0) [0|2047] ""  gtw
 SG_ APS_sw059_sensorStatusRear m59 : 21|1@1+ (1,0) [0|1] ""  gtw
 SG_ APS_sw013_numEyeqResets m13 : 21|3@1+ (1,0) [0|7] ""  gtw
 SG_ APS_sw057_telemetryControl m57 : 21|1@1+ (1,0) [0|1] ""  gtw
 SG_ APS_sw220_vehicleSpeed m220 : 20|12@1+ (0.05,-25) [-25|179.75] "mph"  gtw
 SG_ APS_sw138_mcuNMEAmsgUDPinvalid m138 : 20|1@1+ (1,0) [0|1] ""  gtw
 SG_ APS_sw142_chassisControl m142 : 20|1@1+ (1,0) [0|1] ""  gtw
 SG_ APS_sw158_dasControlPty m158 : 20|1@1+ (1,0) [0|1] ""  gtw
 SG_ APS_sw027_PLL_0_Failure m27 : 20|1@1+ (1,0) [0|1] ""  gtw
 SG_ APS_sw071_endPosX m71 : 20|10@1+ (0.05,-25.6) [-25.6|25.5] "m"  gtw
 SG_ APS_sw137_fusionModeDisabled m137 : 20|1@1+ (1,0) [0|1] ""  gtw
 SG_ APS_sw195_s11Blocked m195 : 20|1@1+ (1,0) [0|1] ""  gtw
 SG_ APS_sw038_AutofixOutOfCalibYaw m38 : 20|1@1+ (1,0) [0|1] ""  gtw
 SG_ APS_sw200_autopilotRestricted m200 : 20|1@1+ (1,0) [0|1] ""  gtw
 SG_ APS_sw202_s11Blocked m202 : 20|1@1+ (1,0) [0|1] ""  gtw
 SG_ APS_sw069_parkMismatch m69 : 20|1@1+ (1,0) [0|1] ""  gtw
 SG_ APS_sw057_driverAssistControl m57 : 20|1@1+ (1,0) [0|1] ""  gtw
 SG_ APS_sw213_autopilotRestricted m213 : 20|1@1+ (1,0) [0|1] ""  gtw
 SG_ APS_sw051_a52radomeHtrInop m51 : 20|1@1+ (1,0) [0|1] ""  gtw
 SG_ APS_sw005_fullBlockage m5 : 20|1@1+ (1,0) [0|1] ""  gtw
 SG_ APS_sw011_scaRight m11 : 20|1@1+ (1,0) [0|1] ""  gtw
 SG_ APS_sw053_a14sccmMIA m53 : 20|1@1+ (1,0) [0|1] ""  gtw
 SG_ APS_sw059_pasFrontMiddle m59 : 20|1@1+ (1,0) [0|1] ""  gtw
 SG_ APS_sw048_checkStop m48 : 20|1@1+ (1,0) [0|1] ""  gtw
 SG_ APS_sw203_curbType m203 : 20|2@1+ (1,0) [0|3] ""  gtw
 SG_ APS_sw134_dasBodyControlsVEH m134 : 20|1@1+ (1,0) [0|1] ""  gtw
 SG_ APS_sw010_HorizontalMisalignment m10 : 20|16@1+ (0.00137332,-45) [-45|45.0005262] "deg"  gtw
 SG_ APS_sw015_LowSun m15 : 20|2@1+ (1,0) [0|3] ""  gtw
 SG_ APS_sw140_sensors m140 : 20|1@1+ (1,0) [0|1] ""  gtw
 SG_ APS_sw022_recordId m22 : 20|12@1+ (1,0) [0|4095] ""  gtw
 SG_ APS_sw047_roadClass m47 : 20|3@1+ (1,0) [0|7] ""  gtw
 SG_ APS_sw219_vehicleSpeed m219 : 20|12@1+ (0.05,-25) [-25|179.75] "mph"  gtw
 SG_ APS_sw004_radMia m4 : 20|1@1+ (1,0) [0|1] ""  gtw
 SG_ APS_sw025_road_class m25 : 20|3@1+ (1,0) [0|7] ""  gtw
 SG_ APS_sw052_underTemperature m52 : 20|1@1+ (1,0) [0|1] ""  gtw
 SG_ APS_sw073_rawMobileyeLDW m73 : 20|2@1+ (1,0) [0|3] ""  gtw
 SG_ APS_sw006_SunRay m6 : 20|1@1+ (1,0) [0|1] ""  gtw
 SG_ APS_sw080_rad_tar_5_check m80 : 20|1@1+ (1,0) [0|1] ""  gtw
 SG_ APS_sw028_inv_multifrm_next m28 : 20|1@1+ (1,0) [0|1] ""  gtw
 SG_ APS_sw024_numVirtualLaneVeh m24 : 20|4@1+ (1,0) [0|15] ""  gtw
 SG_ APS_sw017_Camera_Msg_Common_MIA m17 : 20|1@1+ (1,0) [0|1] ""  gtw
 SG_ APS_sw193_partialBlockage m193 : 20|1@1+ (1,0) [0|1] ""  gtw
 SG_ APS_sw230_sensor5Blocked m230 : 20|1@1+ (1,0) [0|1] ""  gtw
 SG_ APS_sw080_stw_angle_check m80 : 19|1@1+ (1,0) [0|1] ""  gtw
 SG_ APS_sw033_carState m33 : 19|1@1+ (1,0) [0|1] ""  gtw
 SG_ APS_sw042_abort_reason m42 : 19|5@1+ (1,0) [0|31] ""  gtw
 SG_ APS_sw153_eacInternalState m153 : 19|3@1+ (1,0) [0|7] ""  gtw
 SG_ APS_sw038_AutofixOutOfCalibHorzn m38 : 19|1@1+ (1,0) [0|1] ""  gtw
 SG_ APS_sw136_badgpsfix m136 : 19|1@1+ (1,0) [0|1] ""  gtw
 SG_ APS_sw198_tsrMsgInvalid m198 : 19|1@1+ (1,0) [0|1] ""  gtw
 SG_ APS_sw158_dasControl m158 : 19|1@1+ (1,0) [0|1] ""  gtw
 SG_ APS_sw195_s8Blocked m195 : 19|1@1+ (1,0) [0|1] ""  gtw
 SG_ APS_sw028_inv_multifrm_id m28 : 19|1@1+ (1,0) [0|1] ""  gtw
 SG_ APS_sw140_lighting m140 : 19|1@1+ (1,0) [0|1] ""  gtw
 SG_ APS_sw230_sensor4Blocked m230 : 19|1@1+ (1,0) [0|1] ""  gtw
 SG_ APS_sw069_sccmMia m69 : 19|1@1+ (1,0) [0|1] ""  gtw
 SG_ APS_sw053_a13gtwMIA m53 : 19|1@1+ (1,0) [0|1] ""  gtw
 SG_ APS_sw010_a08PlantMode m10 : 19|1@1+ (1,0) [0|1] ""  gtw
 SG_ APS_sw011_scaLeft m11 : 19|1@1+ (1,0) [0|1] ""  gtw
 SG_ APS_sw017_Camera_Msg_Hlb_MIA m17 : 19|1@1+ (1,0) [0|1] ""  gtw
 SG_ APS_sw137_gpsUBXmissing m137 : 19|1@1+ (1,0) [0|1] ""  gtw
 SG_ APS_sw051_a09configMismatch m51 : 19|1@1+ (1,0) [0|1] ""  gtw
 SG_ APS_sw006_OutOfFocusImage m6 : 19|1@1+ (1,0) [0|1] ""  gtw
 SG_ APS_sw138_navx5CfgFailed m138 : 19|1@1+ (1,0) [0|1] ""  gtw
 SG_ APS_sw142_torque m142 : 19|1@1+ (1,0) [0|1] ""  gtw
 SG_ APS_sw059_sensorStatusFront m59 : 19|1@1+ (1,0) [0|1] ""  gtw
 SG_ APS_sw193_outOfFocusImage m193 : 19|1@1+ (1,0) [0|1] ""  gtw
 SG_ APS_sw052_overTemperature m52 : 19|1@1+ (1,0) [0|1] ""  gtw
 SG_ APS_sw027_CPU_Checkstop_Error m27 : 19|1@1+ (1,0) [0|1] ""  gtw
 SG_ APS_sw048_stackOverflow m48 : 19|1@1+ (1,0) [0|1] ""  gtw
 SG_ APS_sw070_lastTireFitment m70 : 19|3@1+ (1,0) [0|7] ""  gtw
 SG_ APS_sw134_appStatus m134 : 19|1@1+ (1,0) [0|1] ""  gtw
 SG_ APS_sw202_s8Blocked m202 : 19|1@1+ (1,0) [0|1] ""  gtw
 SG_ APS_sw005_partialBlockage m5 : 19|1@1+ (1,0) [0|1] ""  gtw
 SG_ APS_sw201_steeringErrorOAL m201 : 19|3@1+ (1,0) [0|7] ""  gtw
 SG_ APS_sw057_autopilotControl m57 : 19|1@1+ (1,0) [0|1] ""  gtw
 SG_ APS_sw143_wheelSpeeds m143 : 19|1@1+ (1,0) [0|1] ""  gtw
 SG_ APS_sw004_radSGUFailure m4 : 19|1@1+ (1,0) [0|1] ""  gtw
 SG_ APS_sw053_a12espMIA m53 : 18|1@1+ (1,0) [0|1] ""  gtw
 SG_ APS_sw059_status m59 : 18|1@1+ (1,0) [0|1] ""  gtw
 SG_ APS_sw004_radSensorBlind m4 : 18|1@1+ (1,0) [0|1] ""  gtw
 SG_ APS_sw147_lightStatus m147 : 18|1@1+ (1,0) [0|1] ""  gtw
 SG_ APS_sw227_vehicleSpeed m227 : 18|12@1+ (0.05,-25) [-25|179.75] "mph"  gtw
 SG_ APS_sw151_apWatchDogState m151 : 18|3@1+ (1,0) [0|7] ""  gtw
 SG_ APS_sw009_DI_MIA m9 : 18|1@1+ (1,0) [0|1] ""  gtw
 SG_ APS_sw051_a03vBatHigh m51 : 18|1@1+ (1,0) [0|1] ""  gtw
 SG_ APS_sw140_status m140 : 18|1@1+ (1,0) [0|1] ""  gtw
 SG_ APS_sw195_s7Blocked m195 : 18|1@1+ (1,0) [0|1] ""  gtw
 SG_ APS_sw017_Camera_Msg_Tsr_MIA m17 : 18|1@1+ (1,0) [0|1] ""  gtw
 SG_ APS_sw143_wheelRotation m143 : 18|1@1+ (1,0) [0|1] ""  gtw
 SG_ APS_sw033_vin m33 : 18|1@1+ (1,0) [0|1] ""  gtw
 SG_ APS_sw138_gpsBufferOverflow m138 : 18|1@1+ (1,0) [0|1] ""  gtw
 SG_ APS_sw069_parkMia m69 : 18|1@1+ (1,0) [0|1] ""  gtw
 SG_ APS_sw073_escalateLDWreason m73 : 18|2@1+ (1,0) [0|3] ""  gtw
 SG_ APS_sw015_RadarMisalignment m15 : 18|2@1+ (1,0) [0|3] ""  gtw
 SG_ APS_sw136_antennaUnplugged m136 : 18|1@1+ (1,0) [0|1] ""  gtw
 SG_ APS_sw080_road_class_check m80 : 18|1@1+ (1,0) [0|1] ""  gtw
 SG_ APS_sw028_inv_multifrm_1st m28 : 18|1@1+ (1,0) [0|1] ""  gtw
 SG_ APS_sw158_dasBodyControlsVEH m158 : 18|1@1+ (1,0) [0|1] ""  gtw
 SG_ APS_sw026_tardiness m26 : 18|9@1+ (0.25,0) [0|127.75] "ms"  gtw
 SG_ APS_sw198_tflMsgInvalid m198 : 18|1@1+ (1,0) [0|1] ""  gtw
 SG_ APS_sw193_impairedVD m193 : 18|1@1+ (1,0) [0|1] ""  gtw
 SG_ APS_sw142_systemStatus m142 : 18|1@1+ (1,0) [0|1] ""  gtw
 SG_ APS_sw027_Unused_Bit_0 m27 : 18|1@1+ (1,0) [0|1] ""  gtw
 SG_ APS_sw150_leftStalk m150 : 18|1@1+ (1,0) [0|1] ""  gtw
 SG_ APS_sw006_radCalibration m6 : 18|1@1+ (1,0) [0|1] ""  gtw
 SG_ APS_sw230_sensor3Blocked m230 : 18|1@1+ (1,0) [0|1] ""  gtw
 SG_ APS_sw202_s7Blocked m202 : 18|1@1+ (1,0) [0|1] ""  gtw
 SG_ APS_sw134_appInfo m134 : 18|1@1+ (1,0) [0|1] ""  gtw
 SG_ APS_sw035_wheelRotation m35 : 18|1@1+ (1,0) [0|1] ""  gtw
 SG_ APS_sw005_RadarMisalignment m5 : 18|1@1+ (1,0) [0|1] ""  gtw
 SG_ APS_sw038_AutofixOutOfCalib m38 : 18|1@1+ (1,0) [0|1] ""  gtw
 SG_ APS_sw057_gpsVehicleSpeed m57 : 18|1@1+ (1,0) [0|1] ""  gtw
 SG_ APS_sw048_powerIssue m48 : 18|1@1+ (1,0) [0|1] ""  gtw
 SG_ APS_sw137_gpsNMEAmissing m137 : 18|1@1+ (1,0) [0|1] ""  gtw
 SG_ APS_sw010_a06calibNotOK m10 : 18|1@1+ (1,0) [0|1] ""  gtw
 SG_ APS_sw052_HWFail m52 : 18|1@1+ (1,0) [0|1] ""  gtw
 SG_ APS_sw146_status m146 : 17|1@1+ (1,0) [0|1] ""  gtw
 SG_ APS_sw148_lightStatus m148 : 17|1@1+ (1,0) [0|1] ""  gtw
 SG_ APS_sw051_a02flashPerformance m51 : 17|1@1+ (1,0) [0|1] ""  gtw
 SG_ APS_sw033_chNm m33 : 17|1@1+ (1,0) [0|1] ""  gtw
 SG_ APS_sw195_s6Blocked m195 : 17|1@1+ (1,0) [0|1] ""  gtw
 SG_ APS_sw053_a11bdyMIA m53 : 17|1@1+ (1,0) [0|1] ""  gtw
 SG_ APS_sw202_s6Blocked m202 : 17|1@1+ (1,0) [0|1] ""  gtw
 SG_ APS_sw230_sensor2Blocked m230 : 17|1@1+ (1,0) [0|1] ""  gtw
 SG_ APS_sw138_invalidID m138 : 17|1@1+ (1,0) [0|1] ""  gtw
 SG_ APS_sw220_roadClass m220 : 17|3@1+ (1,0) [0|7] ""  gtw
 SG_ APS_sw059_sdiRear m59 : 17|1@1+ (1,0) [0|1] ""  gtw
 SG_ APS_sw158_apbStatus m158 : 17|1@1+ (1,0) [0|1] ""  gtw
 SG_ APS_sw057_locationStatus m57 : 17|1@1+ (1,0) [0|1] ""  gtw
 SG_ APS_sw029_unusedBits m29 : 17|15@1+ (1,0) [0|32767] ""  gtw
 SG_ APS_sw004_radHWFailure m4 : 17|1@1+ (1,0) [0|1] ""  gtw
 SG_ APS_sw027_Core_Reset m27 : 17|1@1+ (1,0) [0|1] ""  gtw
 SG_ APS_sw140_vehicleStatus m140 : 17|1@1+ (1,0) [0|1] ""  gtw
 SG_ APS_sw143_status m143 : 17|1@1+ (1,0) [0|1] ""  gtw
 SG_ APS_sw227_sensorNumber m227 : 17|1@1+ (1,0) [0|1] ""  gtw
 SG_ APS_sw193_fullBlockage m193 : 17|1@1+ (1,0) [0|1] ""  gtw
 SG_ APS_sw010_a05calibReqd m10 : 17|1@1+ (1,0) [0|1] ""  gtw
 SG_ APS_sw134_appCameraLux m134 : 17|1@1+ (1,0) [0|1] ""  gtw
 SG_ APS_sw038_OutOfFocusImage m38 : 17|1@1+ (1,0) [0|1] ""  gtw
 SG_ APS_sw136_fusionIrrecoverable m136 : 17|1@1+ (1,0) [0|1] ""  gtw
 SG_ APS_sw005_AutofixOutOfCalibYaw m5 : 17|1@1+ (1,0) [0|1] ""  gtw
 SG_ APS_sw150_rightStalk m150 : 17|1@1+ (1,0) [0|1] ""  gtw
 SG_ APS_sw009_DI_aeb_unresponsive m9 : 17|1@1+ (1,0) [0|1] ""  gtw
 SG_ APS_sw048_thermalIssue m48 : 17|1@1+ (1,0) [0|1] ""  gtw
 SG_ APS_sw141_inertial2 m141 : 17|1@1+ (1,0) [0|1] ""  gtw
 SG_ APS_sw073_silentEscalatedLDW m73 : 17|1@1+ (1,0) [0|1] ""  gtw
 SG_ APS_sw028_rx_inv_len m28 : 17|1@1+ (1,0) [0|1] ""  gtw
 SG_ APS_sw064_status m64 : 17|1@1+ (1,0) [0|1] ""  gtw
 SG_ APS_sw052_sensorDirty m52 : 17|1@1+ (1,0) [0|1] ""  gtw
 SG_ APS_sw142_locStatus m142 : 17|1@1+ (1,0) [0|1] ""  gtw
 SG_ APS_sw137_gpsJunkData m137 : 17|1@1+ (1,0) [0|1] ""  gtw
 SG_ APS_sw147_switchStatus m147 : 17|1@1+ (1,0) [0|1] ""  gtw
 SG_ APS_sw219_roadClass m219 : 17|3@1+ (1,0) [0|7] ""  gtw
 SG_ APS_sw069_espMia m69 : 17|1@1+ (1,0) [0|1] ""  gtw
 SG_ APS_sw006_RadarMisaligned m6 : 17|1@1+ (1,0) [0|1] ""  gtw
 SG_ APS_sw198_partialBlockage m198 : 17|1@1+ (1,0) [0|1] ""  gtw
 SG_ APS_sw080_dist_travelled_check m80 : 17|1@1+ (1,0) [0|1] ""  gtw
 SG_ APS_sw017_Camera_Msg_Objects_MIA m17 : 17|1@1+ (1,0) [0|1] ""  gtw
 SG_ APS_sw035_status m35 : 17|1@1+ (1,0) [0|1] ""  gtw
 SG_ APS_sw205_oocDistance m205 : 16|8@1+ (1,0) [0|255] "cm"  gtw
 SG_ APS_sw131_trapAddr m131 : 16|32@1+ (1,0) [0|4294967295] ""  gtw
 SG_ APS_sw140_lvPowerState m140 : 16|1@1+ (1,0) [0|1] ""  gtw
 SG_ APS_sw078_camCipv_dx m78 : 16|8@1+ (0.2,0) [0|51] "m"  gtw
 SG_ APS_sw148_doorStatus m148 : 16|1@1+ (1,0) [0|1] ""  gtw
 SG_ APS_sw130_currentTemperature m130 : 16|8@1- (1,0) [-128|127] "degC"  gtw
 SG_ APS_sw195_s1Blocked m195 : 16|1@1+ (1,0) [0|1] ""  gtw
 SG_ APS_sw043_mobileye_status m43 : 16|16@1+ (1,0) [0|65535] ""  gtw
 SG_ APS_sw049_boot_version_msw m49 : 16|16@1+ (1,0) [0|65535] ""  gtw
 SG_ APS_sw199_abortCodeDAS m199 : 16|5@1+ (1,0) [0|31] ""  gtw
 SG_ APS_sw055_detectedRadcVersion m55 : 16|32@1+ (1,0) [0|4294967295] ""  gtw
 SG_ APS_sw142_speed m142 : 16|1@1+ (1,0) [0|1] ""  gtw
 SG_ APS_sw077_oocDistance m77 : 16|9@1+ (1,0) [0|512] "cm"  gtw
 SG_ APS_sw022_operation m22 : 16|4@1+ (1,0) [0|15] ""  gtw
 SG_ APS_sw153_eacInhibitReason m153 : 16|3@1+ (1,0) [0|7] ""  gtw
 SG_ APS_sw218_cipvDist m218 : 16|8@1+ (0.2,0) [0|51] "m"  gtw
 SG_ APS_sw060_targetDist m60 : 16|9@1+ (0.2,0) [0|102.2] "m"  gtw
 SG_ APS_sw025_state_before_override m25 : 16|4@1+ (1,0) [0|15] ""  gtw
 SG_ APS_sw141_inertial1 m141 : 16|1@1+ (1,0) [0|1] ""  gtw
 SG_ APS_sw069_epasMia m69 : 16|1@1+ (1,0) [0|1] ""  gtw
 SG_ APS_sw144_restraintStatus m144 : 16|1@1+ (1,0) [0|1] ""  gtw
 SG_ APS_sw044_countLSB m44 : 16|8@1+ (1,0) [0|255] ""  gtw
 SG_ APS_sw080_sensors_healty_check m80 : 16|1@1+ (1,0) [0|1] ""  gtw
 SG_ APS_sw014_fileNameHash m14 : 16|16@1+ (1,0) [0|65535] ""  gtw
 SG_ APS_sw150_steeringAngleSensor m150 : 16|1@1+ (1,0) [0|1] ""  gtw
 SG_ APS_sw220_controlledAccess m220 : 16|1@1+ (1,0) [0|1] ""  gtw
 SG_ APS_sw230_sensor1Blocked m230 : 16|1@1+ (1,0) [0|1] ""  gtw
 SG_ APS_sw081_radarDistance m81 : 16|8@1+ (0.0625,0) [0|15.9375] "m"  gtw
 SG_ APS_sw059_sdiFront m59 : 16|1@1+ (1,0) [0|1] ""  gtw
 SG_ APS_sw103_objectDx m103 : 16|8@1+ (0.5,0) [0|127.5] "m"  gtw
 SG_ APS_sw068_percentConsistency m68 : 16|10@1+ (0.1,0) [0|100] "%"  gtw
 SG_ APS_sw030_heaterState m30 : 16|8@1+ (1,0) [0|255] ""  gtw
 SG_ APS_sw021_tempSensorId m21 : 16|8@1+ (1,0) [0|255] ""  gtw
 SG_ APS_sw047_edrStatus m47 : 16|4@1+ (1,0) [0|15] ""  gtw
 SG_ APS_sw029_tx_buffer_full m29 : 16|1@1+ (1,0) [0|1] ""  gtw
 SG_ APS_sw010_a04calibNotDone m10 : 16|1@1+ (1,0) [0|1] ""  gtw
 SG_ APS_sw034_sccmMia m34 : 16|8@1+ (1,0) [0|255] ""  gtw
 SG_ APS_sw231_timeToImpact m231 : 16|9@1+ (1,0) [0|511] "ms"  gtw
 SG_ APS_sw156_LWIPAssertLine m156 : 16|16@1+ (1,0) [0|65535] ""  gtw
 SG_ APS_sw054_Autofix_cnvrgnceStatus m54 : 16|8@1+ (1,0) [0|255] ""  gtw
 SG_ APS_sw145_restraintStatus m145 : 16|1@1+ (1,0) [0|1] ""  gtw
 SG_ APS_sw016_targetDist m16 : 16|9@1+ (0.2,0) [0|102.2] "m"  gtw
 SG_ APS_sw155_InUnicastError m155 : 16|1@1+ (1,0) [0|1] ""  gtw
 SG_ APS_sw035_wheelSpeeds m35 : 16|1@1+ (1,0) [0|1] ""  gtw
 SG_ APS_sw063_expectedMajorVer m63 : 16|8@1+ (1,0) [0|255] ""  gtw
 SG_ APS_sw194_leadAx m194 : 16|6@1- (0.2,0.0) [-6|6] "m/s^2"  gtw
 SG_ APS_sw129_currentVoltage m129 : 16|14@1+ (1,0) [0|6600] "mV"  gtw
 SG_ APS_sw039_sdm_rcm_Mia m39 : 16|8@1+ (1,0) [0|255] ""  gtw
 SG_ APS_sw106_torsionBarOffset m106 : 16|8@1+ (0.005,-0.64) [-0.64|0.635] "Nm"  gtw
 SG_ APS_sw135_appCriticalReason m135 : 16|4@1+ (1,0) [0|5] ""  gtw
 SG_ APS_sw158_apbInfo m158 : 16|1@1+ (1,0) [0|1] ""  gtw
 SG_ APS_sw051_a01ecuInternalPerf m51 : 16|1@1+ (1,0) [0|1] ""  gtw
 SG_ APS_sw053_a10canBusOff m53 : 16|1@1+ (1,0) [0|1] ""  gtw
 SG_ APS_sw013_stateBeforeWatchdog m13 : 16|5@1+ (1,0) [0|31] ""  gtw
 SG_ APS_sw012_bootTestResults m12 : 16|16@1+ (1,0) [0|65535] ""  gtw
 SG_ APS_sw024_Task_ID m24 : 16|4@1+ (1,0) [0|15] ""  gtw
 SG_ APS_sw133_failedInitStep m133 : 16|8@1+ (1,0) [0|255] ""  gtw
 SG_ APS_sw004_radIssue m4 : 16|1@1+ (1,0) [0|1] ""  gtw
 SG_ APS_sw227_sensorSide m227 : 16|1@1+ (1,0) [0|1] ""  gtw
 SG_ APS_sw062_HorizontalMisalignment m62 : 16|16@1+ (0.00137332,-45) [-45|45.0005262] "deg"  gtw
 SG_ APS_sw076_targetDist m76 : 16|9@1+ (0.2,0) [0|102.2] "m"  gtw
 SG_ APS_sw033_carConfig m33 : 16|1@1+ (1,0) [0|1] ""  gtw
 SG_ APS_sw086_distanceException m86 : 16|8@1+ (1,90) [90|165] "m"  gtw
 SG_ APS_sw071_selfParkType m71 : 16|4@1+ (1,0) [0|15] ""  gtw
 SG_ APS_sw015_RadarLowVisibility m15 : 16|2@1+ (1,0) [0|3] ""  gtw
 SG_ APS_sw065_app_mobileye_status m65 : 16|8@1+ (1,0) [0|255] ""  gtw
 SG_ APS_sw074_ipsoDx m74 : 16|6@1+ (2,0) [0|126] "m"  gtw
 SG_ APS_sw152_fusionStatus m152 : 16|2@1+ (1,0) [0|3] ""  gtw
 SG_ APS_sw067_sccmSTW m67 : 16|14@1+ (0.1,-819.2) [-819.2|819] "deg"  gtw
 SG_ APS_sw075_scMia m75 : 16|8@1+ (1,0) [0|255] ""  gtw
 SG_ APS_sw027_JTAG_Reset m27 : 16|1@1+ (1,0) [0|1] ""  gtw
 SG_ APS_sw136_gpsCommIrrecoverable m136 : 16|1@1+ (1,0) [0|1] ""  gtw
 SG_ APS_sw064_sysStatus m64 : 16|1@1+ (1,0) [0|1] ""  gtw
 SG_ APS_sw038_RadarMisalignment m38 : 16|1@1+ (1,0) [0|1] ""  gtw
 SG_ APS_sw200_autopilotIntState m200 : 16|4@1+ (1,0) [0|15] ""  gtw
 SG_ APS_sw041_rate m41 : 16|10@1- (1,0) [-512|511] "deg/s"  gtw
 SG_ APS_sw005_AutofixOutOfCalib m5 : 16|1@1+ (1,0) [0|1] ""  gtw
 SG_ APS_sw036_bdyMia m36 : 16|8@1+ (1,0) [0|255] ""  gtw
 SG_ APS_sw058_epbMia m58 : 16|8@1+ (1,0) [0|255] ""  gtw
 SG_ APS_sw139_numMessagesRx m139 : 16|8@1+ (1,0) [0|255] ""  gtw
 SG_ APS_sw057_driverAssistMapData m57 : 16|1@1+ (1,0) [0|1] ""  gtw
 SG_ APS_sw009_DIaebState_fault m9 : 16|1@1+ (1,0) [0|1] ""  gtw
 SG_ APS_sw073_escalateLDWs m73 : 16|1@1+ (1,0) [0|1] ""  gtw
 SG_ APS_sw147_doorStatus m147 : 16|1@1+ (1,0) [0|1] ""  gtw
 SG_ APS_sw149_status m149 : 16|1@1+ (1,0) [0|1] ""  gtw
 SG_ APS_sw019_taskId m19 : 16|8@1+ (1,0) [0|255] ""  gtw
 SG_ APS_sw006_RadarLowVisibility m6 : 16|1@1+ (1,0) [0|1] ""  gtw
 SG_ APS_sw161_antennaDisconnected m161 : 16|1@1+ (1,0) [0|1] ""  gtw
 SG_ APS_sw201_virtualLaneInputOAL m201 : 16|3@1+ (1,0) [0|7] ""  gtw
 SG_ APS_sw037_camera m37 : 16|8@1+ (1,0) [0|255] ""  gtw
 SG_ APS_sw072_vehicleX m72 : 16|10@1+ (0.05,-25.6) [-25.6|25.5] "m"  gtw
 SG_ APS_sw213_autopilotIntState m213 : 16|4@1+ (1,0) [0|15] ""  gtw
 SG_ APS_sw001_APS_alertDataW0 m1 : 16|16@1+ (1,0) [0|65535] ""  gtw
 SG_ APS_sw193_blurredImage m193 : 16|1@1+ (1,0) [0|1] ""  gtw
 SG_ APS_sw146_sysStatus m146 : 16|1@1+ (1,0) [0|1] ""  gtw
 SG_ APS_sw011_scaState m11 : 16|3@1+ (1,0) [0|7] ""  gtw
 SG_ APS_sw203_controlType m203 : 16|4@1+ (1,0) [0|15] ""  gtw
 SG_ APS_sw050_targetDist m50 : 16|9@1+ (0.2,0) [0|102.2] "m"  gtw
 SG_ APS_sw061_states m61 : 16|1@1+ (1,0) [0|1] ""  gtw
 SG_ APS_sw143_motorLimits m143 : 16|1@1+ (1,0) [0|1] ""  gtw
 SG_ APS_sw082_L_VL m82 : 16|8@1+ (0.05,-6.4) [-6.4|6.35] "m"  gtw
 SG_ APS_sw052_a07sensorBlinded m52 : 16|1@1+ (1,0) [0|1] ""  gtw
 SG_ APS_sw045_radMia m45 : 16|8@1+ (1,0) [0|255] ""  gtw
 SG_ APS_sw083_Targ5_RCS m83 : 16|16@1+ (0.0039063096,0) [0|256] "dB"  gtw
 SG_ APS_sw026_task_id m26 : 16|2@1+ (1,0) [0|3] ""  gtw
 SG_ APS_sw056_diMia m56 : 16|8@1+ (1,0) [0|255] ""  gtw
 SG_ APS_sw160_mismatchType m160 : 16|1@1+ (1,0) [0|1] ""  gtw
 SG_ APS_sw028_rx_buffer_full m28 : 16|1@1+ (1,0) [0|1] ""  gtw
 SG_ APS_sw040_accel_pedal_pos m40 : 16|8@1+ (0.5,0) [0|127.5] "%"  gtw
 SG_ APS_sw219_controlledAccess m219 : 16|1@1+ (1,0) [0|1] ""  gtw
 SG_ APS_sw207_appMobileyeStatus m207 : 16|8@1+ (1,0) [0|255] ""  gtw
 SG_ APS_sw018_minThreshold m18 : 16|13@1+ (1,0) [0|4500] "mV"  gtw
 SG_ APS_sw132_mismatchType m132 : 16|1@1+ (1,0) [0|1] ""  gtw
 SG_ APS_sw159_apbCriticalReason m159 : 16|4@1+ (1,0) [0|5] ""  gtw
 SG_ APS_sw066_app_mobileye_status m66 : 16|8@1+ (1,0) [0|255] ""  gtw
 SG_ APS_sw204_frLeft m204 : 16|8@1+ (1,0) [0|255] "cm"  gtw
 SG_ APS_sw020_unusedW0 m20 : 16|16@1+ (1,0) [0|65535] ""  gtw
 SG_ APS_sw134_appCamCalibStatus m134 : 16|1@1+ (1,0) [0|1] ""  gtw
 SG_ APS_sw137_gpsCommMissing m137 : 16|1@1+ (1,0) [0|1] ""  gtw
 SG_ APS_sw198_fullBlockage m198 : 16|1@1+ (1,0) [0|1] ""  gtw
 SG_ APS_sw017_Camera_Msg_Lanes_MIA m17 : 16|1@1+ (1,0) [0|1] ""  gtw
 SG_ APS_sw032_canBus m32 : 16|4@1+ (1,0) [0|15] ""  gtw
 SG_ APS_sw202_s1Blocked m202 : 16|1@1+ (1,0) [0|1] ""  gtw
 SG_ APS_sw042_health_state m42 : 16|3@1+ (1,0) [0|7] ""  gtw
 SG_ APS_sw138_cfgBufNull m138 : 16|1@1+ (1,0) [0|1] ""  gtw
 SG_ APS_sw070_currTireFitment m70 : 16|3@1+ (1,0) [0|7] ""  gtw
 SG_ APS_sw085_radarDistance m85 : 16|8@1+ (0.0625,0) [0|15.9375] "m"  gtw
 SG_ APS_sw151_apGpioState m151 : 16|2@1+ (1,0) [0|3] ""  gtw
 SG_ APS_sw031_canBus m31 : 16|4@1+ (1,0) [0|15] ""  gtw
 SG_ APS_sw048_swAssert m48 : 16|1@1+ (1,0) [0|1] ""  gtw
 SG_ APS_sw046_recordId m46 : 16|16@1+ (1,0) [0|65535] ""  gtw
 SG_ APS_sw084_ipsoTTC m84 : 16|8@1+ (0.02,0) [0|5.11] "seconds"  gtw
 SG_ APS_alertState : 15|1@1+ (1,0) [0|1] ""  gtw
 SG_ APS_alertID M : 0|15@1+ (1,0) [0|231] ""  gtw

BO_ 1849 DAS_IsotermSMS: 8 CH
 SG_ DAS_IsotermSMS : 7|64@0+ (1,0) [0|18446744073709551615] ""  dbg

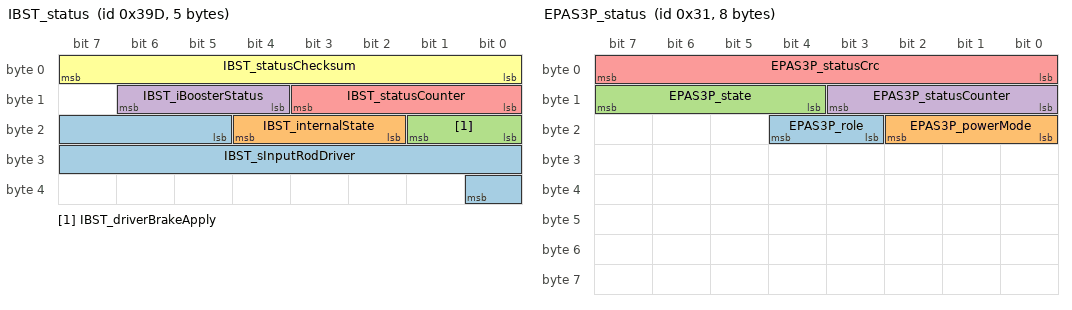
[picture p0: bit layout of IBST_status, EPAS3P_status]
BO_ 925 IBST_status: 5 CH
 SG_ IBST_sInputRodDriver : 21|12@1+ (0.015625,-5) [-5|47] "mm"  gtw
 SG_ IBST_internalState : 18|3@1+ (1,0) [0|6] ""  gtw
 SG_ IBST_driverBrakeApply : 16|2@1+ (1,0) [0|3] ""  gtw
 SG_ IBST_iBoosterStatus : 12|3@1+ (1,0) [0|6] ""  gtw
 SG_ IBST_statusCounter : 8|4@1+ (1,0) [0|15] ""  X
 SG_ IBST_statusChecksum : 0|8@1+ (1,0) [0|255] ""  X

BO_ 49 EPAS3P_status: 8 CH
 SG_ EPAS3P_role : 19|2@1+ (1,0) [0|2] ""  epas3s
 SG_ EPAS3P_powerMode : 16|3@1+ (1,0) [0|7] ""  epas3s
 SG_ EPAS3P_state : 12|4@1+ (1,0) [0|15] ""  epas3s
 SG_ EPAS3P_statusCounter : 8|4@1+ (1,0) [0|15] ""  epas3s
 SG_ EPAS3P_statusCrc : 0|8@1+ (1,0) [0|255] ""  epas3s

BO_ 841 DAS_warningMatrix2: 8 CH
 SG_ DAS_w181_rRepeatCamCalSaved : 52|1@1+ (1,0) [0|1] ""  gtw
 SG_ DAS_w180_lRepeatCamCalSaved : 51|1@1+ (1,0) [0|1] ""  gtw
 SG_ DAS_w179_rPillarCamCalSaved : 50|1@1+ (1,0) [0|1] ""  gtw
 SG_ DAS_w178_lPillarCamCalSaved : 49|1@1+ (1,0) [0|1] ""  gtw
 SG_ DAS_w177_fisheyeCamCalSaved : 48|1@1+ (1,0) [0|1] ""  gtw
 SG_ DAS_w175_rRepeatCamExtNotCal : 46|1@1+ (1,0) [0|1] ""  gtw
 SG_ DAS_w174_lRepeatCamExtNotCal : 45|1@1+ (1,0) [0|1] ""  gtw
 SG_ DAS_w173_rPillarCamExtNotCal : 44|1@1+ (1,0) [0|1] ""  gtw
 SG_ DAS_w172_lPillarCamExtNotCal : 43|1@1+ (1,0) [0|1] ""  gtw
 SG_ DAS_w171_fisheyeCamExtNotCal : 42|1@1+ (1,0) [0|1] ""  gtw
 SG_ DAS_w144_selfieCamInitFault : 15|1@1+ (1,0) [0|1] ""  gtw
 SG_ DAS_w143_IDF_event : 14|1@1+ (1,0) [0|1] ""  gtw
 SG_ DAS_w142_fwdCamPitchProblem : 13|1@1+ (1,0) [0|1] ""  gtw
 SG_ DAS_w141_ECU_Thermal_Issue : 12|1@1+ (1,0) [0|1] ""  gtw
 SG_ DAS_w140_backupCamInitFault : 11|1@1+ (1,0) [0|1] ""  gtw
 SG_ DAS_w139_rRepeatCamInitFault : 10|1@1+ (1,0) [0|1] ""  gtw
 SG_ DAS_w138_lRepeatCamInitFault : 9|1@1+ (1,0) [0|1] ""  gtw
 SG_ DAS_w137_rPillarCamInitFault : 8|1@1+ (1,0) [0|1] ""  gtw
 SG_ DAS_w136_lPillarCamInitFault : 7|1@1+ (1,0) [0|1] ""  gtw
 SG_ DAS_w135_fisheyeCamInitFault : 6|1@1+ (1,0) [0|1] ""  gtw
 SG_ DAS_w134_narrowCamInitFault : 5|1@1+ (1,0) [0|1] ""  gtw
 SG_ DAS_w133_mainCamInitFault : 4|1@1+ (1,0) [0|1] ""  gtw
 SG_ DAS_w132_narrowCamCalSaved : 3|1@1+ (1,0) [0|1] ""  gtw
 SG_ DAS_w131_mainCamCalSaved : 2|1@1+ (1,0) [0|1] ""  gtw
 SG_ DAS_w130_narrowCamExtNotCal : 1|1@1+ (1,0) [0|1] ""  gtw
 SG_ DAS_w129_mainCamExtNotCal : 0|1@1+ (1,0) [0|1] ""  gtw

BO_ 1629 IBST_udsResponse: 8 CH
 SG_ IBST_udsResponseData : 7|64@0+ (1,0) [0|18446744073709551615] ""  gtw

BO_ 1349 VCFRONT_systemStatus: 8 CH
 SG_ VCFRONT_systemStatusChecksum : 56|8@1+ (1,0) [0|255] ""  X
 SG_ VCFRONT_systemStatusCounter : 52|4@1+ (1,0) [0|15] ""  X
 SG_ VCFRONT_vcrightVoltage m0 : 40|12@1+ (0.005443676098,0) [0|22.28641] "V"  X
 SG_ VCFRONT_vcleftVoltage m0 : 28|12@1+ (0.005443676098,0) [0|22.28641] "V"  X
 SG_ VCFRONT_loadShedTAS m1 : 23|1@1+ (1,0) [0|1] ""  tas
 SG_ VCFRONT_vcrightCurrent m0 : 16|12@1+ (0.05,0) [0|204.7] "A"  X
 SG_ VCFRONT_loadShedPumps_duty m1 : 16|7@1+ (1,0) [0|100] "%"  X
 SG_ VCFRONT_loadShedUI m1 : 15|1@1+ (1,0) [0|1] ""  X
 SG_ VCFRONT_loadShedRSeatHeaters m1 : 14|1@1+ (1,0) [0|1] ""  X
 SG_ VCFRONT_loadShedDefrosters m1 : 13|1@1+ (1,0) [0|1] ""  X
 SG_ VCFRONT_loadShedBlower_duty m1 : 6|7@1+ (1,0) [0|100] "%"  X
 SG_ VCFRONT_loadShed12VAuxLoads m1 : 5|1@1+ (1,0) [0|1] ""  X
 SG_ VCFRONT_loadShedAmplifier m1 : 4|1@1+ (1,0) [0|1] ""  X
 SG_ VCFRONT_loadShedFSeatHeaters m1 : 3|1@1+ (1,0) [0|1] ""  X
 SG_ VCFRONT_vcleftCurrent m0 : 1|12@1+ (0.05,0) [0|204.7] "A"  X
 SG_ VCFRONT_loadShedSMState m1 : 1|2@1+ (1,0) [0|3] ""  X
 SG_ VCFRONT_systemStatusMuxIndex M : 0|1@1+ (1,0) [0|1] ""  X

BO_ 986 DAS_telemetryEvent: 8 CH
 SG_ DAS_TE_vlFuse m5 : 63|1@1+ (1,0) [0|1] ""  gtw
 SG_ DAS_TE_hppFuse m3 : 63|1@1+ (1,0) [0|1] ""  gtw
 SG_ DAS_TE_llFuse m1 : 63|1@1+ (1,0) [0|1] ""  gtw
 SG_ DAS_TE_navFuse m4 : 63|1@1+ (1,0) [0|1] ""  gtw
 SG_ DAS_TE_rlFuse m2 : 63|1@1+ (1,0) [0|1] ""  gtw
 SG_ DAS_TE_meIpsoValid m8 : 57|1@1+ (1,0) [0|1] ""  gtw
 SG_ DAS_TE_navRange m4 : 56|7@1+ (1,0) [0|127] "m"  gtw
 SG_ DAS_TE_rlRange m2 : 56|7@1+ (1,0) [0|127] "m"  gtw
 SG_ DAS_TE_crashPedPro m8 : 56|1@1+ (1,0) [0|1] ""  gtw
 SG_ DAS_TE_hppRange m3 : 56|7@1+ (1,0) [0|127] "m"  gtw
 SG_ DAS_TE_llRange m1 : 56|7@1+ (1,0) [0|127] "m"  gtw
 SG_ DAS_TE_vlRange m5 : 56|7@1+ (1,0) [0|127] "m"  gtw
 SG_ DAS_TE_rlQlty m2 : 55|1@1+ (1,0) [0|1] ""  gtw
 SG_ DAS_TE_navQlty m4 : 55|1@1+ (1,0) [0|1] ""  gtw
 SG_ DAS_TE_vlQlty m5 : 55|1@1+ (1,0) [0|1] ""  gtw
 SG_ DAS_TE_llQlty m1 : 55|1@1+ (1,0) [0|1] ""  gtw
 SG_ DAS_TE_hppQlty m3 : 55|1@1+ (1,0) [0|1] ""  gtw
 SG_ DAS_TE_crashRollover m8 : 55|1@1+ (1,0) [0|1] ""  gtw
 SG_ DAS_TE_crashRight m8 : 54|1@1+ (1,0) [0|1] ""  gtw
 SG_ DAS_TE_robActiveBraking m9 : 53|1@1+ (1,0) [0|1] ""  gtw
 SG_ DAS_TE_crashRear m8 : 53|1@1+ (1,0) [0|1] ""  gtw
 SG_ DAS_TE_crashLeft m8 : 52|1@1+ (1,0) [0|1] ""  gtw
 SG_ DAS_TE_meAebFlag m7 : 52|1@1+ (1,0) [0|1] ""  gtw
 SG_ DAS_TE_robTrustRadarMap m9 : 52|1@1+ (1,0) [0|1] ""  gtw
 SG_ DAS_TE_crashFront m8 : 51|1@1+ (1,0) [0|1] ""  gtw
 SG_ DAS_TE_robInfrastructure m9 : 51|1@1+ (1,0) [0|1] ""  gtw
 SG_ DAS_TE_extendedAccLimits m8 : 50|1@1+ (1,0) [0|1] ""  gtw
 SG_ DAS_TE_emergencyBrake m8 : 49|1@1+ (1,0) [0|1] ""  gtw
 SG_ DAS_TE_brakeCapacityWarning m8 : 48|1@1+ (1,0) [0|1] ""  gtw
 SG_ DAS_TE_robEllipseAge m9 : 48|3@1+ (1,0) [0|7] ""  gtw
 SG_ DAS_TE_fcmDecelReqAeb m7 : 45|7@1- (0.1,-6.3) [-12.7|0] "m/s^2"  gtw
 SG_ DAS_TE_accControlType m8 : 44|4@1+ (1,0) [0|15] ""  gtw
 SG_ DAS_TE_csaOfframpValid m8 : 43|1@1+ (1,0) [0|1] ""  gtw
 SG_ DAS_TE_restrictedAccess m8 : 42|1@1+ (1,0) [0|1] ""  gtw
 SG_ DAS_TE_rlC3 m2 : 41|14@1- (1.6e-08,0.0) [-0.000131072|0.000131056] "1/m2"  gtw
 SG_ DAS_TE_navC3 m4 : 41|14@1- (1.6e-08,0.0) [-0.000131072|0.000131056] "1/m2"  gtw
 SG_ DAS_TE_vlC3 m5 : 41|14@1- (1.6e-08,0.0) [-0.000131072|0.000131056] "1/m2"  gtw
 SG_ DAS_TE_hppC3 m3 : 41|14@1- (1.6e-08,0.0) [-0.000131072|0.000131056] "1/m2"  gtw
 SG_ DAS_TE_llC3 m1 : 41|14@1- (1.6e-08,0.0) [-0.000131072|0.000131056] "1/m2"  gtw
 SG_ DAS_TE_ipsoIsTarget5 m8 : 41|1@1+ (1,0) [0|1] ""  gtw
 SG_ DAS_TE_ipsoIsTarget1 m8 : 40|1@1+ (1,0) [0|1] ""  gtw
 SG_ DAS_TE_robEllipseOverlap m9 : 40|8@1+ (0.1,-12.5) [-12.5|12.5] "m"  gtw
 SG_ DAS_TE_fcmDecelReqInstant m7 : 38|7@1- (0.1,-6.3) [-12.7|0] "m/s^2"  gtw
 SG_ DAS_TE_accMinJ m6 : 37|5@1- (0.5,-7.5) [-15.5|0] "m/s^3"  gtw
 SG_ DAS_TE_swaProjection m8 : 34|6@1+ (0.1,-3.2) [-3.2|3.1] "m"  gtw
 SG_ DAS_TE_fcmTargetProb m7 : 33|5@1+ (5,0) [0|160] "%"  gtw
 SG_ DAS_TE_robDistanceEllipse m9 : 32|8@1+ (0.5,0) [0|127.5] "m"  gtw
 SG_ DAS_TE_accMinAccel m6 : 32|5@1- (0.5,-7.5) [-15.5|0] "m/s^2"  gtw
 SG_ DAS_TE_lcAbortReason m0 : 32|5@1+ (1,0) [0|31] ""  gtw
 SG_ DAS_TE_fcmTargetAccel m7 : 28|5@1+ (0.5,-15.5) [-15.5|0] "m/s^2"  gtw
 SG_ DAS_TE_vlDyAtIpsoDx m8 : 28|6@1+ (0.1,-3.2) [-3.2|3.1] "m"  gtw
 SG_ DAS_TE_hppC2 m3 : 27|14@1- (4e-06,0.0) [-0.032768|0.032764] "1/m"  gtw
 SG_ DAS_TE_llC2 m1 : 27|14@1- (4e-06,0.0) [-0.032768|0.032764] "1/m"  gtw
 SG_ DAS_TE_rlC2 m2 : 27|14@1- (4e-06,0.0) [-0.032768|0.032764] "1/m"  gtw
 SG_ DAS_TE_navC2 m4 : 27|14@1- (4e-06,0.0) [-0.032768|0.032764] "1/m"  gtw
 SG_ DAS_TE_accTargetRelA m6 : 27|5@1- (0.5,-7.5) [-15.5|0] "m/s^2"  gtw
 SG_ DAS_TE_vlC2 m5 : 27|14@1- (4e-06,0.0) [-0.032768|0.032764] "1/m"  gtw
 SG_ DAS_TE_eventType m0 : 24|6@1+ (1,0) [0|14] ""  gtw
 SG_ DAS_TE_robExceptionEnd m9 : 24|8@1+ (1,0) [0|255] "m"  gtw
 SG_ DAS_TE_ipsoDy m8 : 22|6@1+ (0.1,-3.2) [-3.2|3.1] "m"  gtw
 SG_ DAS_TE_fcmTargetVRel m7 : 21|7@1+ (0.25,-31.75) [-31.75|0] "m/s"  gtw
 SG_ DAS_TE_accTargetRelVel m6 : 20|7@1- (0.25,-15.75) [-31.75|0] "m/s"  gtw
 SG_ DAS_TE_hppC1 m3 : 18|9@1- (0.001953125,0.0) [-0.5|0.498046875] "rad"  gtw
 SG_ DAS_TE_llC1 m1 : 18|9@1- (0.001953125,0.0) [-0.5|0.498046875] "rad"  gtw
 SG_ DAS_TE_vlC1 m5 : 18|9@1- (0.001953125,0.0) [-0.5|0.498046875] "rad"  gtw
 SG_ DAS_TE_rlC1 m2 : 18|9@1- (0.001953125,0.0) [-0.5|0.498046875] "rad"  gtw
 SG_ DAS_TE_navC1 m4 : 18|9@1- (0.001953125,0.0) [-0.5|0.498046875] "rad"  gtw
 SG_ DAS_TE_ipsoDx m8 : 16|6@1+ (2,0) [0|126] "m"  gtw
 SG_ DAS_TE_fcmTargetDy m7 : 16|5@1+ (0.2,-3.2) [-3.2|3] "m"  gtw
 SG_ DAS_TE_robExceptionStart m9 : 16|8@1+ (1,-95) [-95|160] "m"  gtw
 SG_ DAS_TE_accTargetDy m6 : 14|6@1+ (0.2,-6.4) [-6.4|6.2] "m"  gtw
 SG_ DAS_TE_ipsoConfidence m8 : 9|7@1+ (1,0) [0|127] ""  gtw
 SG_ DAS_TE_fcmTargetDx m7 : 8|8@1+ (0.25,0) [0|63.75] "m"  gtw
 SG_ DAS_TE_llC0 m1 : 8|10@1- (0.02,0.0) [-10.24|10.22] "m"  gtw
 SG_ DAS_TE_hppC0 m3 : 8|10@1- (0.02,0.0) [-10.24|10.22] "m"  gtw
 SG_ DAS_TE_vlC0 m5 : 8|10@1- (0.02,0.0) [-10.24|10.22] "m"  gtw
 SG_ DAS_TE_eventID m0 : 8|16@1+ (1,0) [0|65535] ""  gtw
 SG_ DAS_TE_accTargetDx m6 : 8|6@1+ (2,0) [0|126] "m"  gtw
 SG_ DAS_TE_navC0 m4 : 8|10@1- (0.02,0.0) [-10.24|10.22] "m"  gtw
 SG_ DAS_TE_rlC0 m2 : 8|10@1- (0.02,0.0) [-10.24|10.22] "m"  gtw
 SG_ DAS_TE_ipsoValid m8 : 8|1@1+ (1,0) [0|1] ""  gtw
 SG_ DAS_TE_vlCounter m5 : 5|3@1+ (1,0) [0|7] ""  gtw
 SG_ DAS_TE_llCounter m1 : 5|3@1+ (1,0) [0|7] ""  gtw
 SG_ DAS_TE_counter m0 : 5|3@1+ (1,0) [0|7] ""  gtw
 SG_ DAS_TE_hppCounter m3 : 5|3@1+ (1,0) [0|7] ""  gtw
 SG_ DAS_TE_navCounter m4 : 5|3@1+ (1,0) [0|7] ""  gtw
 SG_ DAS_TE_robCounter m9 : 5|3@1+ (1,0) [0|7] ""  X
 SG_ DAS_TE_ipsoCounter m8 : 5|3@1+ (1,0) [0|7] ""  gtw
 SG_ DAS_TE_fcmCounter m7 : 5|3@1+ (1,0) [0|7] ""  gtw
 SG_ DAS_TE_rlCounter m2 : 5|3@1+ (1,0) [0|7] ""  gtw
 SG_ DAS_TE_accCounter m6 : 5|3@1+ (1,0) [0|7] ""  gtw
 SG_ DAS_TE_multiplexer M : 0|5@1+ (1,0) [0|9] ""  gtw

BO_ 1352 APB_info: 8 CH
 SG_ APB_infoApbApGitHashBytes m2 : 8|56@1+ (1,0) [0|72057594037927935] ""  aps
 SG_ APB_buildType m0 : 8|8@1+ (1,0) [0|3] ""  aps
 SG_ APB_infoApbFwGitHashBytes m1 : 8|56@1+ (1,0) [0|72057594037927935] ""  aps
 SG_ APB_infoIndex M : 0|8@1+ (1,0) [0|2] ""  aps

BO_ 877 TAS_warningMatrix2: 8 CH
 SG_ TAS_w128_maxDutyCompressor : 63|1@1+ (1,0) [0|1] ""  gtw
 SG_ TAS_w127_maxDutyBoost : 62|1@1+ (1,0) [0|1] ""  gtw
 SG_ TAS_w126_maxDutyExhaust : 61|1@1+ (1,0) [0|1] ""  gtw
 SG_ TAS_w125_maxDutyReservoir : 60|1@1+ (1,0) [0|1] ""  gtw
 SG_ TAS_w124_maxDutyRR : 59|1@1+ (1,0) [0|1] ""  gtw
 SG_ TAS_w123_maxDutyRL : 58|1@1+ (1,0) [0|1] ""  gtw
 SG_ TAS_w122_maxDutyFR : 57|1@1+ (1,0) [0|1] ""  gtw
 SG_ TAS_w121_maxDutyFL : 56|1@1+ (1,0) [0|1] ""  gtw
 SG_ TAS_w107_HighStackUsage : 42|1@1+ (1,0) [0|1] ""  gtw
 SG_ TAS_w106_HighCPULoad : 41|1@1+ (1,0) [0|1] ""  gtw
 SG_ TAS_w105_ECUDebugMode : 40|1@1+ (1,0) [0|1] ""  gtw
 SG_ TAS_w103_GTW_MIA : 38|1@1+ (1,0) [0|1] ""  gtw
 SG_ TAS_w102_DI_MIA : 37|1@1+ (1,0) [0|1] ""  gtw
 SG_ TAS_w101_ESP_MIA : 36|1@1+ (1,0) [0|1] ""  gtw
 SG_ TAS_w100_RCM_MIA : 35|1@1+ (1,0) [0|1] ""  gtw
 SG_ TAS_w099_UI_MIA : 34|1@1+ (1,0) [0|1] ""  gtw
 SG_ TAS_w098_VCFRONT_MIA : 33|1@1+ (1,0) [0|1] ""  gtw
 SG_ TAS_w093_OTPError : 28|1@1+ (1,0) [0|1] ""  gtw
 SG_ TAS_w079_DvrSideCfgMismatch : 14|1@1+ (1,0) [0|1] ""  gtw
 SG_ TAS_w078_pressureSigVTooHigh : 13|1@1+ (1,0) [0|1] ""  gtw
 SG_ TAS_w077_pressureSigVTooLow : 12|1@1+ (1,0) [0|1] ""  gtw
 SG_ TAS_w076_overVoltage5VOffBoard : 11|1@1+ (1,0) [0|1] ""  gtw
 SG_ TAS_w075_underVoltage5VOffBoard : 10|1@1+ (1,0) [0|1] ""  gtw
 SG_ TAS_w074_shortCircuit5VOffBoard : 9|1@1+ (1,0) [0|1] ""  gtw
 SG_ TAS_w073_underVoltage5VOnBoard : 8|1@1+ (1,0) [0|1] ""  gtw
 SG_ TAS_w072_shortCircuit5VOnBoard : 7|1@1+ (1,0) [0|1] ""  gtw
 SG_ TAS_w071_overVoltage12V : 6|1@1+ (1,0) [0|1] ""  gtw
 SG_ TAS_w070_underVoltage12V : 5|1@1+ (1,0) [0|1] ""  gtw

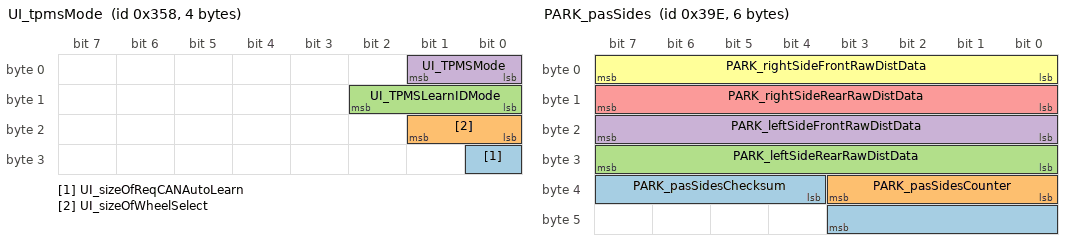
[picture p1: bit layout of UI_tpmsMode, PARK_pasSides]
BO_ 856 UI_tpmsMode: 4 CH
 SG_ UI_sizeOfReqCANAutoLearn : 24|1@1+ (1,0) [0|1] ""  tpms
 SG_ UI_sizeOfWheelSelect : 16|2@1+ (1,0) [0|2] ""  tpms
 SG_ UI_TPMSLearnIDMode : 8|3@1+ (1,0) [0|4] ""  tpms
 SG_ UI_TPMSMode : 0|2@1+ (1,0) [0|2] ""  tpms

BO_ 1821 DBG_cpControl: 6 CH
 SG_ DBG_cp1khzDebugOutput m0 : 40|1@1+ (1,0) [0|1] ""  X
 SG_ DBG_cpLEDDutyWhite m0 : 32|8@1+ (0.39215686275,0) [0|100] "%"  X
 SG_ DBG_cpLatch2MotorDirection m1 : 31|1@1+ (1,0) [0|1] ""  X
 SG_ DBG_cpSWCANRelayActive m4 : 27|1@1+ (1,0) [0|1] ""  X
 SG_ DBG_cpSWCANRelayControlEnable m4 : 26|1@1+ (1,0) [0|1] ""  X
 SG_ DBG_cpGoToSleep m4 : 25|1@1+ (1,0) [0|1] ""  X
 SG_ DBG_cpLatch2HBridgeDuty m1 : 24|7@1+ (1,0) [0|100] "%"  X
 SG_ DBG_cpLEDDutyBlue m0 : 24|8@1+ (0.39215686275,0) [0|100] "%"  X
 SG_ DBG_cpProxEnGBActive m4 : 24|1@1+ (1,0) [0|1] ""  X
 SG_ DBG_cpLatchMotorDirection m1 : 23|1@1+ (1,0) [0|1] ""  X
 SG_ DBG_cpProxEnGBControlEnable m4 : 23|1@1+ (1,0) [0|1] ""  X
 SG_ DBG_cpProxEnGBCC1Active m4 : 22|1@1+ (1,0) [0|1] ""  X
 SG_ DBG_cpProxEnGBCC1ControlEnable m4 : 21|1@1+ (1,0) [0|1] ""  X
 SG_ DBG_cpLatch2EnActive m4 : 20|1@1+ (1,0) [0|1] ""  X
 SG_ DBG_cpLatch2EnControlEnable m4 : 19|1@1+ (1,0) [0|1] ""  X
 SG_ DBG_cpLatchEnActive m4 : 18|1@1+ (1,0) [0|1] ""  X
 SG_ DBG_cpLatchEnControlEnable m4 : 17|1@1+ (1,0) [0|1] ""  X
 SG_ DBG_cpLEDDutyGreen m0 : 16|8@1+ (0.39215686275,0) [0|100] "%"  X
 SG_ DBG_cpLatchHBridgeDuty m1 : 16|7@1+ (1,0) [0|100] "%"  X
 SG_ DBG_cpDoorEnActive m4 : 16|1@1+ (1,0) [0|1] ""  X
 SG_ DBG_cpDoorEnControlEnable m4 : 15|1@1+ (1,0) [0|1] ""  X
 SG_ DBG_latchControlEnable m1 : 15|1@1+ (1,0) [0|1] ""  X
 SG_ DBG_cpLEDEnActive m4 : 14|1@1+ (1,0) [0|1] ""  X
 SG_ DBG_cpLEDEnControlEnable m4 : 13|1@1+ (1,0) [0|1] ""  X
 SG_ DBG_cpProxEnActive m4 : 12|1@1+ (1,0) [0|1] ""  X
 SG_ DBG_cpProxEnControlEnable m4 : 11|1@1+ (1,0) [0|1] ""  X
 SG_ DBG_cpEVSEAcceptActive m4 : 10|1@1+ (1,0) [0|1] ""  X
 SG_ DBG_cpEVSEAcceptControlEnable m4 : 9|1@1+ (1,0) [0|1] ""  X
 SG_ DBG_cpFaultActive m4 : 8|1@1+ (1,0) [0|1] ""  X
 SG_ DBG_cpDoorHeaterDuty m3 : 8|7@1+ (1,0) [0|127] "%"  X
 SG_ DBG_cpDoorHBridgeDuty m1 : 8|7@1+ (1,0) [0|127] "%"  X
 SG_ DBG_cpLEDDutyRed m0 : 8|8@1+ (0.39215686275,0) [0|100] "%"  X
 SG_ DBG_cpFaultControlEnable m4 : 7|1@1+ (1,0) [0|1] ""  X
 SG_ DBG_cp3vActive m4 : 6|1@1+ (1,0) [0|1] ""  X
 SG_ DBG_cp3vControlEnable m4 : 5|1@1+ (1,0) [0|1] ""  X
 SG_ DBG_cpLEDStartSequence m0 : 5|1@1+ (1,0) [0|1] ""  X
 SG_ DBG_cpDoorHeaterControlEnable m3 : 5|1@1+ (1,0) [0|1] ""  X
 SG_ DBG_cpDebugLEDOvrEnable m0 : 4|1@1+ (1,0) [0|1] ""  X
 SG_ DBG_evseRequest m3 : 4|1@1+ (1,0) [0|1] ""  X
 SG_ DBG_cp5vActive m4 : 4|1@1+ (1,0) [0|1] ""  X
 SG_ DBG_cpDoorMotorDirection m1 : 4|1@1+ (1,0) [0|1] ""  X
 SG_ DBG_cpDebugEnable m0 : 3|1@1+ (1,0) [0|1] ""  X
 SG_ DBG_evseRequestControlEnable m3 : 3|1@1+ (1,0) [0|1] ""  X
 SG_ DBG_doorControlEnable m1 : 3|1@1+ (1,0) [0|1] ""  X
 SG_ DBG_cp5vControlEnable m4 : 3|1@1+ (1,0) [0|1] ""  X
 SG_ DBG_CP_debugControls_dataSelect M : 0|3@1+ (1,0) [0|4] ""  X

BO_ 1019 UI_autopilotControl: 8 CH
 SG_ UI_alcViewRangeSensitivity m0 : 56|2@1+ (1,0) [0|3] ""  das
 SG_ UI_alcAssertivenessRate m0 : 54|2@1+ (1,0) [0|2] ""  das
 SG_ UI_alcMergingIntervalHeadwayHyst m0 : 52|2@1+ (1,0) [0|3] ""  das
 SG_ UI_alcMergIntervalRearDHyst m0 : 50|2@1+ (1,0) [0|3] ""  das
 SG_ UI_alcEgoLeadingReactionAccel m0 : 48|2@1+ (1,0) [0|3] ""  das
 SG_ UI_alcUltrasonicWaitTime m0 : 42|3@1+ (1,0) [0|7] ""  das
 SG_ UI_alcUltrasonicDistance m0 : 38|4@1+ (1,0) [0|8] ""  das
 SG_ UI_alcDisableUltrasonicCheck m0 : 37|1@1+ (1,0) [0|1] ""  das
 SG_ UI_donMinGoreWidthForAbortNotMap m0 : 33|4@1+ (1,0) [0|11] ""  das
 SG_ UI_donAlcProgGoreAbortThres m0 : 29|4@1+ (1,0) [0|9] ""  das
 SG_ UI_donMinGoreWidthForAbortMap m0 : 25|4@1+ (1,0) [0|11] ""  das
 SG_ UI_donDisableCutin m0 : 24|1@1+ (1,0) [0|1] ""  das
 SG_ UI_donStopEndOfRampBuffer m0 : 21|3@1+ (1,0) [0|4] ""  das
 SG_ UI_blindspotTTC m0 : 18|3@1+ (1,0) [0|7] ""  das
 SG_ UI_stopAndGo m1 : 17|1@1+ (1,0) [0|1] ""  das
 SG_ UI_blindspotDistance m0 : 15|3@1+ (1,0) [0|5] ""  das
 SG_ UI_blindspotMinSpeed m0 : 11|4@1+ (1,0) [0|10] ""  das
 SG_ UI_camBlockBlurThreshold m1 : 11|6@1+ (0.01587,0) [0|0.99981] "%"  das
 SG_ UI_camBlockBlurDisable m1 : 10|1@1+ (1,0) [0|1] ""  das
 SG_ UI_donDisableOnAutoWiperSpeed m0 : 7|4@1+ (1,0) [0|15] ""  das
 SG_ UI_camBlockLaneCheckThreshold m1 : 4|6@1+ (0.01587,0) [0|0.99981] "%"  das
 SG_ UI_donDisableAutoWiperDuration m0 : 4|3@1+ (1,0) [0|6] ""  das
 SG_ UI_camBlockLaneCheckDisable m1 : 3|1@1+ (1,0) [0|1] ""  das
 SG_ UI_hovEnabled m0 : 3|1@1+ (1,0) [0|1] ""  das
 SG_ UI_autopilotControlIndex M : 0|3@1+ (1,0) [0|7] ""  das

BO_ 1065 APP_warningMatrix2: 8 CH
 SG_ APP_w192_emergencySpeakerFail : 63|1@1+ (1,0) [0|1] ""  gtw
 SG_ APP_w191_autopilotAborting : 62|1@1+ (1,0) [0|1] ""  gtw
 SG_ APP_w190_selfieCameraStreamExit : 61|1@1+ (1,0) [0|1] ""  gtw
 SG_ APP_w189_backupCameraStreamExit : 60|1@1+ (1,0) [0|1] ""  gtw
 SG_ APP_w188_rRepeatCameraStreamExit : 59|1@1+ (1,0) [0|1] ""  gtw
 SG_ APP_w187_lRepeatCameraStreamExit : 58|1@1+ (1,0) [0|1] ""  gtw
 SG_ APP_w186_rPillarCameraStreamExit : 57|1@1+ (1,0) [0|1] ""  gtw
 SG_ APP_w185_lPillarCameraStreamExit : 56|1@1+ (1,0) [0|1] ""  gtw
 SG_ APP_w184_fisheyeCameraStreamExit : 55|1@1+ (1,0) [0|1] ""  gtw
 SG_ APP_w183_narrowCameraStreamExit : 54|1@1+ (1,0) [0|1] ""  gtw
 SG_ APP_w182_mainCameraStreamExit : 53|1@1+ (1,0) [0|1] ""  gtw
 SG_ APP_w181_rRepeatCamCalSaved : 52|1@1+ (1,0) [0|1] ""  gtw
 SG_ APP_w180_lRepeatCamCalSaved : 51|1@1+ (1,0) [0|1] ""  gtw
 SG_ APP_w179_rPillarCamCalSaved : 50|1@1+ (1,0) [0|1] ""  gtw
 SG_ APP_w178_lPillarCamCalSaved : 49|1@1+ (1,0) [0|1] ""  gtw
 SG_ APP_w177_fisheyeCamCalSaved : 48|1@1+ (1,0) [0|1] ""  gtw
 SG_ APP_w176_rRepeatCamExtNotCal : 47|1@1+ (1,0) [0|1] ""  gtw
 SG_ APP_w175_lRepeatCamExtNotCal : 46|1@1+ (1,0) [0|1] ""  gtw
 SG_ APP_w174_rPillarCamExtNotCal : 45|1@1+ (1,0) [0|1] ""  gtw
 SG_ APP_w173_lPillarCamExtNotCal : 44|1@1+ (1,0) [0|1] ""  gtw
 SG_ APP_w172_fisheyeCamExtNotCal : 43|1@1+ (1,0) [0|1] ""  gtw
 SG_ APP_w171_appHighCoolantFlowReq : 42|1@1+ (1,0) [0|1] ""  gtw
 SG_ APP_w170_selfieCameraTypeError : 41|1@1+ (1,0) [0|1] ""  gtw
 SG_ APP_w169_backupCameraTypeError : 40|1@1+ (1,0) [0|1] ""  gtw
 SG_ APP_w168_rRepeatCameraTypeError : 39|1@1+ (1,0) [0|1] ""  gtw
 SG_ APP_w167_lRepeatCameraTypeError : 38|1@1+ (1,0) [0|1] ""  gtw
 SG_ APP_w166_rPillarCameraTypeError : 37|1@1+ (1,0) [0|1] ""  gtw
 SG_ APP_w165_lPillarCameraTypeError : 36|1@1+ (1,0) [0|1] ""  gtw
 SG_ APP_w164_fisheyeCameraTypeError : 35|1@1+ (1,0) [0|1] ""  gtw
 SG_ APP_w163_narrowCameraTypeError : 34|1@1+ (1,0) [0|1] ""  gtw
 SG_ APP_w162_mainCameraTypeError : 33|1@1+ (1,0) [0|1] ""  gtw
 SG_ APP_w161_backupCameraUnavailable : 32|1@1+ (1,0) [0|1] ""  gtw
 SG_ APP_w160_vcrightMiaVehBus : 31|1@1+ (1,0) [0|1] ""  gtw
 SG_ APP_w159_vcleftMiaVehBus : 30|1@1+ (1,0) [0|1] ""  gtw
 SG_ APP_w158_vcfrontMiaVehBus : 29|1@1+ (1,0) [0|1] ""  gtw
 SG_ APP_w157_sccmMiaVehBus : 28|1@1+ (1,0) [0|1] ""  gtw
 SG_ APP_w156_epblMiaVehBus : 27|1@1+ (1,0) [0|1] ""  gtw
 SG_ APP_w155_vcrightMiaPartyBus : 26|1@1+ (1,0) [0|1] ""  gtw
 SG_ APP_w154_vcleftMiaPartyBus : 25|1@1+ (1,0) [0|1] ""  gtw
 SG_ APP_w153_rcmMiaPartyBus : 24|1@1+ (1,0) [0|1] ""  gtw
 SG_ APP_w152_espMiaPartyBus : 23|1@1+ (1,0) [0|1] ""  gtw
 SG_ APP_w151_epasMiaPartyBus : 22|1@1+ (1,0) [0|1] ""  gtw
 SG_ APP_w150_diMiaPartyBus : 21|1@1+ (1,0) [0|1] ""  gtw
 SG_ APP_w149_diskFull : 20|1@1+ (1,0) [0|1] ""  gtw
 SG_ APP_w148_overlayActive : 19|1@1+ (1,0) [0|1] ""  gtw
 SG_ APP_w147_selfieCamInitFault : 18|1@1+ (1,0) [0|1] ""  gtw
 SG_ APP_w146_telemetryProblem : 17|1@1+ (1,0) [0|1] ""  gtw
 SG_ APP_w145_camSelfCalIssue : 16|1@1+ (1,0) [0|1] ""  gtw
 SG_ APP_w144_fanctrldError : 15|1@1+ (1,0) [0|1] ""  gtw
 SG_ APP_w143_IDF_event : 14|1@1+ (1,0) [0|1] ""  gtw
 SG_ APP_w142_fwdCamPitchProblem : 13|1@1+ (1,0) [0|1] ""  gtw
 SG_ APP_w141_ECU_Thermal_Issue : 12|1@1+ (1,0) [0|1] ""  gtw
 SG_ APP_w140_backupCamInitFault : 11|1@1+ (1,0) [0|1] ""  gtw
 SG_ APP_w139_rRepeatCamInitFault : 10|1@1+ (1,0) [0|1] ""  gtw
 SG_ APP_w138_lRepeatCamInitFault : 9|1@1+ (1,0) [0|1] ""  gtw
 SG_ APP_w137_rPillarCamInitFault : 8|1@1+ (1,0) [0|1] ""  gtw
 SG_ APP_w136_lPillarCamInitFault : 7|1@1+ (1,0) [0|1] ""  gtw
 SG_ APP_w135_fisheyeCamInitFault : 6|1@1+ (1,0) [0|1] ""  gtw
 SG_ APP_w134_narrowCamInitFault : 5|1@1+ (1,0) [0|1] ""  gtw
 SG_ APP_w133_mainCamInitFault : 4|1@1+ (1,0) [0|1] ""  gtw
 SG_ APP_w132_narrowCamCalSaved : 3|1@1+ (1,0) [0|1] ""  gtw
 SG_ APP_w131_mainCamCalSaved : 2|1@1+ (1,0) [0|1] ""  gtw
 SG_ APP_w130_narrowCamExtNotCal : 1|1@1+ (1,0) [0|1] ""  gtw
 SG_ APP_w129_mainCamExtNotCal : 0|1@1+ (1,0) [0|1] ""  gtw

BO_ 1497 DAS_carLog: 8 CH
 SG_ DAS_radarTarget4_dx m3 : 48|12@1+ (0.0625,0) [0|255.9375] "m"  gtw
 SG_ DAS_driveOnNavUnavailableReason m2 : 40|5@1+ (1,0) [0|16] ""  gtw
 SG_ DAS_radarTarget1_VxRel m1 : 36|8@1+ (0.2,-25.6) [-25.6|25.4] "m/s"  gtw
 SG_ DAS_handsOnDetected m2 : 36|2@1+ (1,0) [0|2] ""  X
 SG_ DAS_radarTarget3_dx m3 : 36|12@1+ (0.0625,0) [0|255.9375] "m"  gtw
 SG_ DAS_aeb_not_activating_reason m2 : 32|4@1+ (1,0) [0|15] ""  gtw
 SG_ DAS_ACC_camStatus m2 : 30|2@1+ (1,0) [0|3] ""  gtw
 SG_ DAS_radarTarget2_dx m3 : 24|12@1+ (0.0625,0) [0|255.9375] "m"  gtw
 SG_ DAS_radarTarget1_dx m1 : 24|12@1+ (0.0625,0) [0|255.9375] "m"  gtw
 SG_ DAS_LC_handsOnReason m2 : 24|6@1+ (1,0) [0|24] ""  gtw
 SG_ DAS_associated_rad_object m2 : 22|2@1+ (1,0) [0|3] ""  gtw
 SG_ DAS_restrictionLowSpeedTraffic m2 : 21|1@1+ (1,0) [0|1] ""  gtw
 SG_ DAS_constructionArea m2 : 19|2@1+ (1,0) [0|3] ""  gtw
 SG_ DAS_fcmThreatAssesmentMode m2 : 16|3@1+ (1,0) [0|7] ""  gtw
 SG_ DAS_fcmCollisionStage3Checks m2 : 8|8@1+ (1,0) [0|255] ""  gtw
 SG_ DAS_fcmSteeringOverride m2 : 7|1@1+ (1,0) [0|1] ""  gtw
 SG_ DAS_mobileyeIPSOapproved m2 : 6|1@1+ (1,0) [0|1] ""  gtw
 SG_ DAS_mobileyePedAebFlag m2 : 5|1@1+ (1,0) [0|1] ""  gtw
 SG_ DAS_radarTarget5_dx m1 : 4|12@1+ (0.0625,0) [0|255.9375] "m"  gtw
 SG_ DAS_mobileyeVehAebFlag m2 : 4|1@1+ (1,0) [0|1] ""  gtw
 SG_ DAS_carLogMultiplexer M : 0|4@1+ (1,0) [1|3] ""  X

BO_ 926 PARK_pasSides: 6 CH
 SG_ PARK_pasSidesChecksum : 36|8@1+ (1,0) [0|255] ""  X
 SG_ PARK_pasSidesCounter : 32|4@1+ (1,0) [0|15] ""  X
 SG_ PARK_leftSideRearRawDistData : 24|8@1+ (1,0) [0|255] "cm"  gtw
 SG_ PARK_leftSideFrontRawDistData : 16|8@1+ (1,0) [0|255] "cm"  gtw
 SG_ PARK_rightSideRearRawDistData : 8|8@1+ (1,0) [0|255] "cm"  gtw
 SG_ PARK_rightSideFrontRawDistData : 0|8@1+ (1,0) [0|255] "cm"  gtw

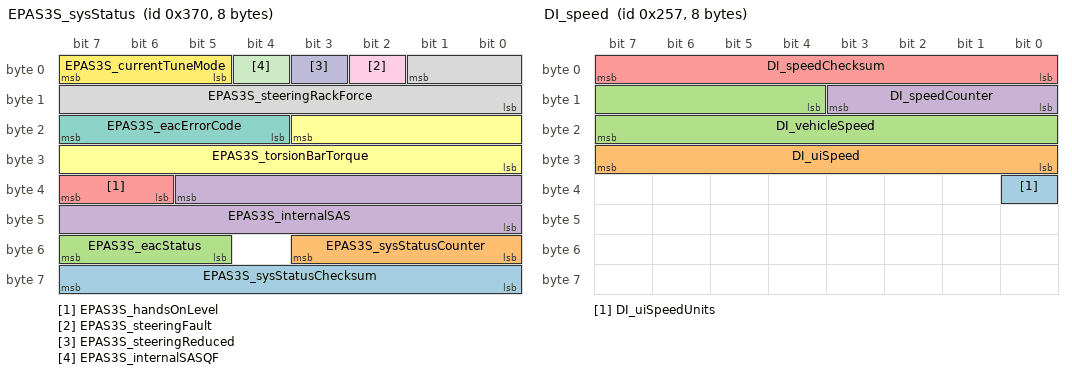
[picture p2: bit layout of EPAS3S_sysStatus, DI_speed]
BO_ 880 EPAS3S_sysStatus: 8 CH
 SG_ EPAS3S_sysStatusChecksum : 63|8@0+ (1,0) [0|255] ""  park
 SG_ EPAS3S_sysStatusCounter : 51|4@0+ (1,0) [0|15] ""  gtw
 SG_ EPAS3S_eacStatus : 55|3@0+ (1,0) [0|7] ""  das
 SG_ EPAS3S_internalSAS : 37|14@0+ (0.1,-819.2) [-819.2|819] "deg"  das
 SG_ EPAS3S_handsOnLevel : 39|2@0+ (1,0) [0|3] ""  das
 SG_ EPAS3S_torsionBarTorque : 19|12@0+ (0.01,-20.5) [-20.5|20.45] "Nm"  das
 SG_ EPAS3S_eacErrorCode : 23|4@0+ (1,0) [0|15] ""  das
 SG_ EPAS3S_steeringRackForce : 1|10@0+ (50,-25575) [-25575|25575] "N"  gtw
 SG_ EPAS3S_steeringFault : 2|1@0+ (1,0) [0|1] ""  das
 SG_ EPAS3S_steeringReduced : 3|1@0+ (1,0) [0|1] ""  das
 SG_ EPAS3S_internalSASQF : 4|1@0+ (1,0) [0|1] ""  gtw
 SG_ EPAS3S_currentTuneMode : 7|3@0+ (1,0) [0|5] ""  gtw

BO_ 1529 DAS_dataLog: 8 CH
 SG_ DAS_scaTTCDuration m22 : 60|4@1+ (0.1,0) [0|1.6] "s"  X
 SG_ DAS_scaOnHighway m22 : 59|1@1+ (1,0) [0|1] ""  X
 SG_ DAS_Reserved_1 m14 : 56|8@1+ (1,0) [0|255] ""  X
 SG_ DAS_bootmsg_EyeQ_Temp_CPU m18 : 56|8@1- (1,0) [-128|127] ""  X
 SG_ DAS_min_lane_width m13 : 56|8@1+ (0.1,0) [0|255] "m"  X
 SG_ DAS_horizonFull m10 : 56|8@1+ (1,0) [0|255] ""  X
 SG_ DAS_maxHorizon m11 : 56|8@1- (1,0) [-128|127] ""  X
 SG_ DAS_bootmsg_Flash_2_Size m21 : 56|8@1+ (1,0) [0|255] ""  X
 SG_ DAS_bootmsg_BoardRevision m19 : 56|8@1+ (1,0) [0|255] ""  X
 SG_ DAS_refPointY m12 : 56|8@1+ (0.1,0) [0|255] "m"  X
 SG_ DAS_mesp_health_sub_state m16 : 56|8@1+ (1,0) [0|255] ""  X
 SG_ DAS_yawRate m23 : 56|8@1+ (0.015625,-2) [-2|2] "rad/s"  X
 SG_ DAS_scaMaxSteeringWheelAngleRate m22 : 52|7@1+ (1,-64) [-64|63] "deg/s"  X
 SG_ DAS_mesp_health_state_data_2 m17 : 48|8@1+ (1,0) [0|255] ""  X
 SG_ DAS_OC_REDUCED_SENSITIVITY m14 : 48|8@1+ (0.1,0) [0|25.5] "smth"  X
 SG_ DAS_bootmsg_FlashSize m21 : 48|8@1+ (1,0) [0|255] ""  X
 SG_ DAS_scaMinTTC m22 : 48|4@1+ (0.1,0) [0|1.6] "s"  X
 SG_ DAS_narrow_lane_width m13 : 48|8@1+ (0.1,0) [0|25.5] "m"  X
 SG_ DAS_stwAngle m23 : 48|8@1- (1,0) [-128|127] "deg"  X
 SG_ DAS_mesp_health_main_state m16 : 48|8@1+ (1,0) [0|255] ""  X
 SG_ DAS_minHorizon m11 : 48|8@1- (1,0) [-128|127] ""  X
 SG_ DAS_refPointX m12 : 48|8@1+ (0.1,0) [0|25.5] "m"  X
 SG_ DAS_bootmsg_DDR_Size m21 : 40|8@1+ (1,0) [0|255] ""  X
 SG_ DAS_outer_dist_term_warn m13 : 40|8@1+ (0.01,0) [0|255] "m"  X
 SG_ DAS_enableLaneCenterPred m14 : 40|8@1+ (1,0) [0|255] ""  X
 SG_ DAS_drivingSide m12 : 40|2@1+ (1,0) [0|3] ""  X
 SG_ DAS_mesp_health_error_details m16 : 40|8@1+ (1,0) [0|255] ""  X
 SG_ DAS_focalLength m10 : 40|16@1+ (1,0) [0|65535] ""  X
 SG_ DAS_mesp_health_state_data_1 m17 : 40|8@1+ (1,0) [0|255] ""  X
 SG_ DAS_Reserved_2 m15 : 40|8@1+ (1,0) [0|255] ""  X
 SG_ DAS_bootmsg_EyeQ_LotNumber m20 : 40|24@1+ (1,0) [0|16777215] ""  X
 SG_ DAS_top m11 : 40|8@1+ (1,0) [0|255] ""  X
 SG_ DAS_camPed_dx m23 : 40|8@1+ (0.2,0) [0|51] "m"  X
 SG_ DAS_scaMaxTorsionBarTorque m22 : 36|12@1+ (0.01,-20.5) [-20.5|20.45] "Nm"  X
 SG_ DAS_camCipv_dx m23 : 32|8@1+ (0.2,0) [0|51] "m"  X
 SG_ DAS_bottom m11 : 32|8@1- (1,0) [-128|127] ""  X
 SG_ DAS_bootmsg_Flash_2_MfgCode m21 : 32|8@1+ (1,0) [0|255] ""  X
 SG_ DAS_disableRectangular m15 : 32|8@1+ (1,0) [0|255] ""  X
 SG_ DAS_cameraHeight m10 : 32|8@1+ (0.01,0) [0|150] "m"  X
 SG_ DAS_t_min_wrn m14 : 32|8@1+ (1,0) [0|255] ""  X
 SG_ DAS_pos_warn_dist_thresh m13 : 32|8@1+ (0.01,0) [0|255] "m"  X
 SG_ DAS_mesp_health_error_code m16 : 32|8@1+ (1,0) [0|255] ""  X
 SG_ DAS_regionCode m12 : 32|8@1+ (1,0) [0|255] ""  X
 SG_ DAS_scaMinRightUltraDist m22 : 27|9@1+ (0.01,0) [0|5.11] "m"  X
 SG_ DAS_camGenObj_dx m23 : 24|8@1+ (0.05,0) [0|10] "m"  X
 SG_ DAS_bootmsg_BoardProjectCode m21 : 24|8@1+ (1,0) [0|255] ""  X
 SG_ DAS_RightWheel m10 : 24|8@1+ (0.01,0) [0|100] "m"  X
 SG_ DAS_bootmsg_EyeQST_Test m18 : 24|32@1+ (1,0) [0|4294967295] ""  X
 SG_ DAS_forcedNonParallel m15 : 24|8@1+ (1,0) [0|255] ""  X
 SG_ DAS_init_autofixYaw m11 : 24|8@1- (1,0) [-128|127] ""  X
 SG_ DAS_mesp_health_diag_flag_1 m17 : 24|16@1+ (1,0) [0|65535] ""  X
 SG_ DAS_bootmsg_BootVersion m19 : 24|32@1+ (1,0) [0|4294967295] ""  X
 SG_ DAS_t_max_wrn m14 : 24|8@1+ (1,0) [0|255] ""  X
 SG_ DAS_calib_reply_ct_ver m16 : 24|8@1+ (1,0) [0|255] ""  X
 SG_ DAS_corridor_outer_boundary m13 : 24|8@1+ (0.01,0) [0|255] "m"  X
 SG_ DAS_scaMinLeftUltraDist m22 : 18|9@1+ (0.01,0) [0|5.11] "m"  X
 SG_ DAS_scaRightLaneChange m22 : 17|1@1+ (1,0) [0|1] ""  X
 SG_ DAS_calib_reply_ct_type m16 : 16|8@1+ (1,0) [0|255] ""  X
 SG_ DAS_scaLeftLaneChange m22 : 16|1@1+ (1,0) [0|1] ""  X
 SG_ DAS_init_autofixHorizon m11 : 16|8@1- (1,0) [-128|127] ""  X
 SG_ DAS_bootmsg_LPDDR2_temp_status m19 : 16|8@1+ (1,0) [0|255] ""  X
 SG_ DAS_speed_turn_on m14 : 16|8@1+ (0.1,0) [0|255] "m/s"  X
 SG_ DAS_StartupFrameIndex m15 : 16|8@1+ (1,0) [0|255] ""  X
 SG_ DAS_leftWheel m10 : 16|8@1+ (0.01,0) [0|100] "m"  X
 SG_ DAS_rollAngle m12 : 16|16@1- (0.001,0.0) [-1500|1500] "rads"  X
 SG_ DAS_radarTarg1_dx m23 : 16|8@1+ (0.0625,0) [0|15.9375] "m"  X
 SG_ DAS_bootmsg_Flash_MfgCode m21 : 16|8@1+ (1,0) [0|255] ""  X
 SG_ DAS_detectConstructionArea m13 : 16|8@1+ (1,0) [0|255] ""  X
 SG_ DAS_scaLDWstatus m22 : 14|2@1+ (1,0) [0|3] ""  X
 SG_ DAS_scaLogType m22 : 11|3@1+ (1,0) [0|7] ""  X
 SG_ DAS_bootmsg_EyeQ_Temp_VMP m19 : 8|8@1+ (1,0) [0|255] ""  X
 SG_ DAS_radarTarg5_dx m23 : 8|8@1+ (0.0625,0) [0|15.9375] "m"  X
 SG_ DAS_bootmsg_testResults m18 : 8|16@1+ (1,0) [0|65535] ""  X
 SG_ DAS_mesp_health_diag_flag_0 m17 : 8|16@1+ (1,0) [0|65535] ""  X
 SG_ DAS_scaLogVersion m22 : 8|3@1+ (1,0) [0|7] ""  X
 SG_ DAS_init_version m10 : 8|8@1+ (1,0) [0|255] ""  X
 SG_ DAS_yawFull m11 : 8|8@1- (1,0) [-128|127] ""  X
 SG_ DAS_bootmsg_ApplicationtVersion m20 : 8|32@1+ (1,0) [0|4294967295] ""  X
 SG_ DAS_calib_reply_ret m16 : 8|8@1+ (1,0) [0|255] ""  X
 SG_ DAS_roadEdgeWarningEnabled m13 : 8|8@1+ (1,0) [0|255] ""  X
 SG_ DAS_bootmsg_DDR_MfgCode m21 : 8|8@1+ (1,0) [0|255] ""  X
 SG_ DAS_maxYaw m12 : 8|8@1+ (1,0) [0|255] ""  X
 SG_ DAS_HilMode m15 : 8|8@1+ (1,0) [0|255] ""  X
 SG_ DAS_speed_turn_off m14 : 8|8@1+ (0.1,0) [0|255] "m/s"  X
 SG_ DAS_logMltplxr M : 0|8@1+ (1,0) [10|23] ""  X

BO_ 561 OCS1P_debugSeatbackSelfCNT: 8 CH
 SG_ OCS1P_seatbackSelfCNTDuty : 32|32@1+ (1,0) [0|4294967295] ""  dbg
 SG_ OCS1P_seatbackSelfCNTFreq : 0|32@1+ (1,0) [0|4294967295] ""  dbg

BO_ 599 DI_speed: 8 CH
 SG_ DI_uiSpeedUnits : 32|1@1+ (1,0) [0|1] ""  das
 SG_ DI_uiSpeed : 24|8@1+ (1,0) [0|254] ""  das
 SG_ DI_vehicleSpeed : 12|12@1+ (0.08,-40) [-40|285] "kph"  park
 SG_ DI_speedCounter : 8|4@1+ (1,0) [0|15] ""  park
 SG_ DI_speedChecksum : 0|8@1+ (1,0) [0|255] ""  park

BO_ 1486 PARK_alertLog: 8 CH
 SG_ PARK_sw039_reverbFreqJitter m39 : 52|1@1+ (1,0) [0|1] ""  gtw
 SG_ PARK_sw034_reverbFreqJitter m34 : 52|1@1+ (1,0) [0|1] ""  gtw
 SG_ PARK_sw054_reverbFreqJitter m54 : 52|1@1+ (1,0) [0|1] ""  gtw
 SG_ PARK_sw009_reverbFreqJitter m9 : 52|1@1+ (1,0) [0|1] ""  gtw
 SG_ PARK_sw024_reverbFreqJitter m24 : 52|1@1+ (1,0) [0|1] ""  gtw
 SG_ PARK_sw019_reverbFreqJitter m19 : 52|1@1+ (1,0) [0|1] ""  gtw
 SG_ PARK_sw044_reverbFreqJitter m44 : 52|1@1+ (1,0) [0|1] ""  gtw
 SG_ PARK_sw014_reverbFreqJitter m14 : 52|1@1+ (1,0) [0|1] ""  gtw
 SG_ PARK_sw049_reverbFreqJitter m49 : 52|1@1+ (1,0) [0|1] ""  gtw
 SG_ PARK_sw059_reverbFreqJitter m59 : 52|1@1+ (1,0) [0|1] ""  gtw
 SG_ PARK_sw004_reverbFreqJitter m4 : 52|1@1+ (1,0) [0|1] ""  gtw
 SG_ PARK_sw029_reverbFreqJitter m29 : 52|1@1+ (1,0) [0|1] ""  gtw
 SG_ PARK_sw059_attenTimeJitter m59 : 51|1@1+ (1,0) [0|1] ""  gtw
 SG_ PARK_sw004_attenTimeJitter m4 : 51|1@1+ (1,0) [0|1] ""  gtw
 SG_ PARK_sw034_attenTimeJitter m34 : 51|1@1+ (1,0) [0|1] ""  gtw
 SG_ PARK_sw039_attenTimeJitter m39 : 51|1@1+ (1,0) [0|1] ""  gtw
 SG_ PARK_sw024_attenTimeJitter m24 : 51|1@1+ (1,0) [0|1] ""  gtw
 SG_ PARK_sw054_attenTimeJitter m54 : 51|1@1+ (1,0) [0|1] ""  gtw
 SG_ PARK_sw009_attenTimeJitter m9 : 51|1@1+ (1,0) [0|1] ""  gtw
 SG_ PARK_sw014_attenTimeJitter m14 : 51|1@1+ (1,0) [0|1] ""  gtw
 SG_ PARK_sw049_attenTimeJitter m49 : 51|1@1+ (1,0) [0|1] ""  gtw
 SG_ PARK_sw044_attenTimeJitter m44 : 51|1@1+ (1,0) [0|1] ""  gtw
 SG_ PARK_sw019_attenTimeJitter m19 : 51|1@1+ (1,0) [0|1] ""  gtw
 SG_ PARK_sw029_attenTimeJitter m29 : 51|1@1+ (1,0) [0|1] ""  gtw
 SG_ PARK_sw054_lowAttenTime m54 : 50|1@1+ (1,0) [0|1] ""  gtw
 SG_ PARK_sw009_lowAttenTime m9 : 50|1@1+ (1,0) [0|1] ""  gtw
 SG_ PARK_sw059_lowAttenTime m59 : 50|1@1+ (1,0) [0|1] ""  gtw
 SG_ PARK_sw004_lowAttenTime m4 : 50|1@1+ (1,0) [0|1] ""  gtw
 SG_ PARK_sw039_lowAttenTime m39 : 50|1@1+ (1,0) [0|1] ""  gtw
 SG_ PARK_sw014_lowAttenTime m14 : 50|1@1+ (1,0) [0|1] ""  gtw
 SG_ PARK_sw049_lowAttenTime m49 : 50|1@1+ (1,0) [0|1] ""  gtw
 SG_ PARK_sw029_lowAttenTime m29 : 50|1@1+ (1,0) [0|1] ""  gtw
 SG_ PARK_sw024_lowAttenTime m24 : 50|1@1+ (1,0) [0|1] ""  gtw
 SG_ PARK_sw034_lowAttenTime m34 : 50|1@1+ (1,0) [0|1] ""  gtw
 SG_ PARK_sw019_lowAttenTime m19 : 50|1@1+ (1,0) [0|1] ""  gtw
 SG_ PARK_sw044_lowAttenTime m44 : 50|1@1+ (1,0) [0|1] ""  gtw
 SG_ PARK_sw019_closeConstEcho m19 : 49|1@1+ (1,0) [0|1] ""  gtw
 SG_ PARK_sw044_closeConstEcho m44 : 49|1@1+ (1,0) [0|1] ""  gtw
 SG_ PARK_sw049_closeConstEcho m49 : 49|1@1+ (1,0) [0|1] ""  gtw
 SG_ PARK_sw014_closeConstEcho m14 : 49|1@1+ (1,0) [0|1] ""  gtw
 SG_ PARK_sw029_closeConstEcho m29 : 49|1@1+ (1,0) [0|1] ""  gtw
 SG_ PARK_sw059_closeConstEcho m59 : 49|1@1+ (1,0) [0|1] ""  gtw
 SG_ PARK_sw004_closeConstEcho m4 : 49|1@1+ (1,0) [0|1] ""  gtw
 SG_ PARK_sw039_closeConstEcho m39 : 49|1@1+ (1,0) [0|1] ""  gtw
 SG_ PARK_sw034_closeConstEcho m34 : 49|1@1+ (1,0) [0|1] ""  gtw
 SG_ PARK_sw024_closeConstEcho m24 : 49|1@1+ (1,0) [0|1] ""  gtw
 SG_ PARK_sw054_closeConstEcho m54 : 49|1@1+ (1,0) [0|1] ""  gtw
 SG_ PARK_sw009_closeConstEcho m9 : 49|1@1+ (1,0) [0|1] ""  gtw
 SG_ PARK_sw059_highAttenTime m59 : 48|1@1+ (1,0) [0|1] ""  gtw
 SG_ PARK_sw004_highAttenTime m4 : 48|1@1+ (1,0) [0|1] ""  gtw
 SG_ PARK_sw029_highAttenTime m29 : 48|1@1+ (1,0) [0|1] ""  gtw
 SG_ PARK_sw034_highAttenTime m34 : 48|1@1+ (1,0) [0|1] ""  gtw
 SG_ PARK_sw039_highAttenTime m39 : 48|1@1+ (1,0) [0|1] ""  gtw
 SG_ PARK_sw009_highAttenTime m9 : 48|1@1+ (1,0) [0|1] ""  gtw
 SG_ PARK_sw054_highAttenTime m54 : 48|1@1+ (1,0) [0|1] ""  gtw
 SG_ PARK_sw024_highAttenTime m24 : 48|1@1+ (1,0) [0|1] ""  gtw
 SG_ PARK_sw049_highAttenTime m49 : 48|1@1+ (1,0) [0|1] ""  gtw
 SG_ PARK_sw014_highAttenTime m14 : 48|1@1+ (1,0) [0|1] ""  gtw
 SG_ PARK_sw044_highAttenTime m44 : 48|1@1+ (1,0) [0|1] ""  gtw
 SG_ PARK_sw019_highAttenTime m19 : 48|1@1+ (1,0) [0|1] ""  gtw
 SG_ PARK_sw082_errorType m82 : 44|3@1+ (1,0) [0|5] ""  gtw
 SG_ PARK_sw081_errorType m81 : 44|3@1+ (1,0) [0|5] ""  gtw
 SG_ PARK_sw080_errorType m80 : 44|3@1+ (1,0) [0|5] ""  gtw
 SG_ PARK_sw077_errorType m77 : 44|3@1+ (1,0) [0|5] ""  gtw
 SG_ PARK_sw078_errorType m78 : 44|3@1+ (1,0) [0|5] ""  gtw
 SG_ PARK_sw084_errorType m84 : 44|3@1+ (1,0) [0|5] ""  gtw
 SG_ PARK_sw079_errorType m79 : 44|3@1+ (1,0) [0|5] ""  gtw
 SG_ PARK_sw083_errorType m83 : 44|3@1+ (1,0) [0|5] ""  gtw
 SG_ PARK_sw059_reverbTime m59 : 32|16@1+ (1,0) [0|65535] "microseconds"  gtw
 SG_ PARK_sw004_reverbTime m4 : 32|16@1+ (1,0) [0|65535] "microseconds"  gtw
 SG_ PARK_sw083_messageID m83 : 32|12@1+ (1,0) [0|4095] ""  gtw
 SG_ PARK_sw086_currentErrorCode m86 : 32|8@1+ (1,0) [0|255] ""  gtw
 SG_ PARK_sw049_reverbTime m49 : 32|16@1+ (1,0) [0|65535] "microseconds"  gtw
 SG_ PARK_sw082_messageID m82 : 32|12@1+ (1,0) [0|4095] ""  gtw
 SG_ PARK_sw014_reverbTime m14 : 32|16@1+ (1,0) [0|65535] "microseconds"  gtw
 SG_ PARK_sw078_messageID m78 : 32|12@1+ (1,0) [0|4095] ""  gtw
 SG_ PARK_sw065_calculatedCRC m65 : 32|16@1+ (1,0) [0|65535] ""  gtw
 SG_ PARK_sw039_reverbTime m39 : 32|16@1+ (1,0) [0|65535] "microseconds"  gtw
 SG_ PARK_sw079_messageID m79 : 32|12@1+ (1,0) [0|4095] ""  gtw
 SG_ PARK_sw084_messageID m84 : 32|12@1+ (1,0) [0|4095] ""  gtw
 SG_ PARK_sw029_reverbTime m29 : 32|16@1+ (1,0) [0|65535] "microseconds"  gtw
 SG_ PARK_sw081_messageID m81 : 32|12@1+ (1,0) [0|4095] ""  gtw
 SG_ PARK_sw024_reverbTime m24 : 32|16@1+ (1,0) [0|65535] "microseconds"  gtw
 SG_ PARK_sw019_reverbTime m19 : 32|16@1+ (1,0) [0|65535] "microseconds"  gtw
 SG_ PARK_sw044_reverbTime m44 : 32|16@1+ (1,0) [0|65535] "microseconds"  gtw
 SG_ PARK_sw077_messageID m77 : 32|12@1+ (1,0) [0|4095] ""  gtw
 SG_ PARK_sw080_messageID m80 : 32|12@1+ (1,0) [0|4095] ""  gtw
 SG_ PARK_sw034_reverbTime m34 : 32|16@1+ (1,0) [0|65535] "microseconds"  gtw
 SG_ PARK_sw009_reverbTime m9 : 32|16@1+ (1,0) [0|65535] "microseconds"  gtw
 SG_ PARK_sw054_reverbTime m54 : 32|16@1+ (1,0) [0|65535] "microseconds"  gtw
 SG_ PARK_sw078_errorRx m78 : 24|8@1+ (1,0) [0|255] ""  gtw
 SG_ PARK_sw080_errorRx m80 : 24|8@1+ (1,0) [0|255] ""  gtw
 SG_ PARK_sw077_errorRx m77 : 24|8@1+ (1,0) [0|255] ""  gtw
 SG_ PARK_sw079_errorRx m79 : 24|8@1+ (1,0) [0|255] ""  gtw
 SG_ PARK_sw083_errorRx m83 : 24|8@1+ (1,0) [0|255] ""  gtw
 SG_ PARK_sw084_errorRx m84 : 24|8@1+ (1,0) [0|255] ""  gtw
 SG_ PARK_sw082_errorRx m82 : 24|8@1+ (1,0) [0|255] ""  gtw
 SG_ PARK_sw086_readRetryCounter m86 : 24|8@1+ (1,0) [0|255] ""  gtw
 SG_ PARK_sw081_errorRx m81 : 24|8@1+ (1,0) [0|255] ""  gtw
 SG_ PARK_sw042_recieveFailure m42 : 20|1@1+ (1,0) [0|1] ""  gtw
 SG_ PARK_sw037_recieveFailure m37 : 20|1@1+ (1,0) [0|1] ""  gtw
 SG_ PARK_sw052_recieveFailure m52 : 20|1@1+ (1,0) [0|1] ""  gtw
 SG_ PARK_sw057_recieveFailure m57 : 20|1@1+ (1,0) [0|1] ""  gtw
 SG_ PARK_sw027_recieveFailure m27 : 20|1@1+ (1,0) [0|1] ""  gtw
 SG_ PARK_sw022_recieveFailure m22 : 20|1@1+ (1,0) [0|1] ""  gtw
 SG_ PARK_sw047_recieveFailure m47 : 20|1@1+ (1,0) [0|1] ""  gtw
 SG_ PARK_sw017_recieveFailure m17 : 20|1@1+ (1,0) [0|1] ""  gtw
 SG_ PARK_sw032_recieveFailure m32 : 20|1@1+ (1,0) [0|1] ""  gtw
 SG_ PARK_sw007_recieveFailure m7 : 20|1@1+ (1,0) [0|1] ""  gtw
 SG_ PARK_sw002_recieveFailure m2 : 20|1@1+ (1,0) [0|1] ""  gtw
 SG_ PARK_sw012_recieveFailure m12 : 20|1@1+ (1,0) [0|1] ""  gtw
 SG_ PARK_sw032_sensorCRC m32 : 19|1@1+ (1,0) [0|1] ""  gtw
 SG_ PARK_sw042_sensorCRC m42 : 19|1@1+ (1,0) [0|1] ""  gtw
 SG_ PARK_sw047_sensorCRC m47 : 19|1@1+ (1,0) [0|1] ""  gtw
 SG_ PARK_sw027_sensorCRC m27 : 19|1@1+ (1,0) [0|1] ""  gtw
 SG_ PARK_sw002_sensorCRC m2 : 19|1@1+ (1,0) [0|1] ""  gtw
 SG_ PARK_sw052_sensorCRC m52 : 19|1@1+ (1,0) [0|1] ""  gtw
 SG_ PARK_sw017_sensorCRC m17 : 19|1@1+ (1,0) [0|1] ""  gtw
 SG_ PARK_sw012_sensorCRC m12 : 19|1@1+ (1,0) [0|1] ""  gtw
 SG_ PARK_sw022_sensorCRC m22 : 19|1@1+ (1,0) [0|1] ""  gtw
 SG_ PARK_sw057_sensorCRC m57 : 19|1@1+ (1,0) [0|1] ""  gtw
 SG_ PARK_sw007_sensorCRC m7 : 19|1@1+ (1,0) [0|1] ""  gtw
 SG_ PARK_sw037_sensorCRC m37 : 19|1@1+ (1,0) [0|1] ""  gtw
 SG_ PARK_sw037_resonanceDrift m37 : 18|1@1+ (1,0) [0|1] ""  gtw
 SG_ PARK_sw012_resonanceDrift m12 : 18|1@1+ (1,0) [0|1] ""  gtw
 SG_ PARK_sw042_resonanceDrift m42 : 18|1@1+ (1,0) [0|1] ""  gtw
 SG_ PARK_sw027_resonanceDrift m27 : 18|1@1+ (1,0) [0|1] ""  gtw
 SG_ PARK_sw022_resonanceDrift m22 : 18|1@1+ (1,0) [0|1] ""  gtw
 SG_ PARK_sw052_resonanceDrift m52 : 18|1@1+ (1,0) [0|1] ""  gtw
 SG_ PARK_sw057_resonanceDrift m57 : 18|1@1+ (1,0) [0|1] ""  gtw
 SG_ PARK_sw032_resonanceDrift m32 : 18|1@1+ (1,0) [0|1] ""  gtw
 SG_ PARK_sw047_resonanceDrift m47 : 18|1@1+ (1,0) [0|1] ""  gtw
 SG_ PARK_sw017_resonanceDrift m17 : 18|1@1+ (1,0) [0|1] ""  gtw
 SG_ PARK_sw007_resonanceDrift m7 : 18|1@1+ (1,0) [0|1] ""  gtw
 SG_ PARK_sw002_resonanceDrift m2 : 18|1@1+ (1,0) [0|1] ""  gtw
 SG_ PARK_sw052_dampResistorFail m52 : 17|1@1+ (1,0) [0|1] ""  gtw
 SG_ PARK_sw002_dampResistorFail m2 : 17|1@1+ (1,0) [0|1] ""  gtw
 SG_ PARK_sw012_dampResistorFail m12 : 17|1@1+ (1,0) [0|1] ""  gtw
 SG_ PARK_sw017_dampResistorFail m17 : 17|1@1+ (1,0) [0|1] ""  gtw
 SG_ PARK_sw022_dampResistorFail m22 : 17|1@1+ (1,0) [0|1] ""  gtw
 SG_ PARK_sw007_dampResistorFail m7 : 17|1@1+ (1,0) [0|1] ""  gtw
 SG_ PARK_sw057_dampResistorFail m57 : 17|1@1+ (1,0) [0|1] ""  gtw
 SG_ PARK_sw032_dampResistorFail m32 : 17|1@1+ (1,0) [0|1] ""  gtw
 SG_ PARK_sw037_dampResistorFail m37 : 17|1@1+ (1,0) [0|1] ""  gtw
 SG_ PARK_sw047_dampResistorFail m47 : 17|1@1+ (1,0) [0|1] ""  gtw
 SG_ PARK_sw042_dampResistorFail m42 : 17|1@1+ (1,0) [0|1] ""  gtw
 SG_ PARK_sw027_dampResistorFail m27 : 17|1@1+ (1,0) [0|1] ""  gtw
 SG_ PARK_sw035_placeHolder m35 : 16|1@1+ (1,0) [0|1] ""  gtw
 SG_ PARK_sw016_sensorTemperature m16 : 16|16@1+ (0.1,-40) [-40|200] "deg"  gtw
 SG_ PARK_sw053_placeHolder m53 : 16|1@1+ (1,0) [0|1] ""  gtw
 SG_ PARK_sw059_reverbPeriod m59 : 16|16@1+ (1,0) [0|65535] "microseconds"  gtw
 SG_ PARK_sw004_reverbPeriod m4 : 16|16@1+ (1,0) [0|65535] "microseconds"  gtw
 SG_ PARK_sw074_messageID m74 : 16|16@1+ (1,0) [0|65535] ""  gtw
 SG_ PARK_sw068_placeHolder m68 : 16|1@1+ (1,0) [0|1] ""  gtw
 SG_ PARK_sw032_membraneDisconct m32 : 16|1@1+ (1,0) [0|1] ""  gtw
 SG_ PARK_sw017_membraneDisconct m17 : 16|1@1+ (1,0) [0|1] ""  gtw
 SG_ PARK_sw078_errorExp m78 : 16|8@1+ (1,0) [0|255] ""  gtw
 SG_ PARK_sw023_placeHolder m23 : 16|1@1+ (1,0) [0|1] ""  gtw
 SG_ PARK_sw045_placeHolder m45 : 16|1@1+ (1,0) [0|1] ""  gtw
 SG_ PARK_sw018_placeHolder m18 : 16|1@1+ (1,0) [0|1] ""  gtw
 SG_ PARK_sw067_placeHolder m67 : 16|1@1+ (1,0) [0|1] ""  gtw
 SG_ PARK_sw065_expectedCRC m65 : 16|16@1+ (1,0) [0|65535] ""  gtw
 SG_ PARK_sw082_errorExp m82 : 16|8@1+ (1,0) [0|255] ""  gtw
 SG_ PARK_sw047_membraneDisconct m47 : 16|1@1+ (1,0) [0|1] ""  gtw
 SG_ PARK_sw041_sensorTemperature m41 : 16|16@1+ (0.1,-40) [-40|200] "deg"  gtw
 SG_ PARK_sw086_writeRetryCounter m86 : 16|8@1+ (1,0) [0|255] ""  gtw
 SG_ PARK_sw040_placeHolder m40 : 16|1@1+ (1,0) [0|1] ""  gtw
 SG_ PARK_sw063_voltage m63 : 16|16@1+ (0.1,0) [0|25.5] "volts"  gtw
 SG_ PARK_sw075_messageID m75 : 16|16@1+ (1,0) [0|65535] ""  gtw
 SG_ PARK_sw081_errorExp m81 : 16|8@1+ (1,0) [0|255] ""  gtw
 SG_ PARK_sw014_reverbPeriod m14 : 16|16@1+ (1,0) [0|65535] "microseconds"  gtw
 SG_ PARK_sw022_membraneDisconct m22 : 16|1@1+ (1,0) [0|1] ""  gtw
 SG_ PARK_sw049_reverbPeriod m49 : 16|16@1+ (1,0) [0|65535] "microseconds"  gtw
 SG_ PARK_sw020_placeHolder m20 : 16|1@1+ (1,0) [0|1] ""  gtw
 SG_ PARK_sw027_membraneDisconct m27 : 16|1@1+ (1,0) [0|1] ""  gtw
 SG_ PARK_sw021_sensorTemperature m21 : 16|16@1+ (0.1,-40) [-40|200] "deg"  gtw
 SG_ PARK_sw084_errorExp m84 : 16|8@1+ (1,0) [0|255] ""  gtw
 SG_ PARK_sw057_membraneDisconct m57 : 16|1@1+ (1,0) [0|1] ""  gtw
 SG_ PARK_sw062_voltage m62 : 16|16@1+ (0.1,0) [0|25.5] "volts"  gtw
 SG_ PARK_sw058_placeHolder m58 : 16|1@1+ (1,0) [0|1] ""  gtw
 SG_ PARK_sw005_placeHolder m5 : 16|1@1+ (1,0) [0|1] ""  gtw
 SG_ PARK_sw026_sensorTemperature m26 : 16|16@1+ (0.1,-40) [-40|200] "deg"  gtw
 SG_ PARK_sw033_placeHolder m33 : 16|1@1+ (1,0) [0|1] ""  gtw
 SG_ PARK_sw039_reverbPeriod m39 : 16|16@1+ (1,0) [0|65535] "microseconds"  gtw
 SG_ PARK_sw052_membraneDisconct m52 : 16|1@1+ (1,0) [0|1] ""  gtw
 SG_ PARK_sw055_placeHolder m55 : 16|1@1+ (1,0) [0|1] ""  gtw
 SG_ PARK_sw008_placeHolder m8 : 16|1@1+ (1,0) [0|1] ""  gtw
 SG_ PARK_sw079_errorExp m79 : 16|8@1+ (1,0) [0|255] ""  gtw
 SG_ PARK_sw072_messageID m72 : 16|16@1+ (1,0) [0|65535] ""  gtw
 SG_ PARK_sw038_placeHolder m38 : 16|1@1+ (1,0) [0|1] ""  gtw
 SG_ PARK_sw046_sensorTemperature m46 : 16|16@1+ (0.1,-40) [-40|200] "deg"  gtw
 SG_ PARK_sw003_placeHolder m3 : 16|1@1+ (1,0) [0|1] ""  gtw
 SG_ PARK_sw037_membraneDisconct m37 : 16|1@1+ (1,0) [0|1] ""  gtw
 SG_ PARK_sw077_errorExp m77 : 16|8@1+ (1,0) [0|255] ""  gtw
 SG_ PARK_sw080_errorExp m80 : 16|8@1+ (1,0) [0|255] ""  gtw
 SG_ PARK_sw060_placeHolder m60 : 16|1@1+ (1,0) [0|1] ""  gtw
 SG_ PARK_sw061_voltage m61 : 16|16@1+ (0.1,0) [0|25.5] "volts"  gtw
 SG_ PARK_sw064_faultCode m64 : 16|8@1+ (1,0) [0|255] ""  gtw
 SG_ PARK_sw042_membraneDisconct m42 : 16|1@1+ (1,0) [0|1] ""  gtw
 SG_ PARK_sw010_placeHolder m10 : 16|1@1+ (1,0) [0|1] ""  gtw
 SG_ PARK_sw073_messageID m73 : 16|16@1+ (1,0) [0|65535] ""  gtw
 SG_ PARK_sw029_reverbPeriod m29 : 16|16@1+ (1,0) [0|65535] "microseconds"  gtw
 SG_ PARK_sw011_sensorTemperature m11 : 16|16@1+ (0.1,-40) [-40|200] "deg"  gtw
 SG_ PARK_sw048_placeHolder m48 : 16|1@1+ (1,0) [0|1] ""  gtw
 SG_ PARK_sw012_membraneDisconct m12 : 16|1@1+ (1,0) [0|1] ""  gtw
 SG_ PARK_sw015_placeHolder m15 : 16|1@1+ (1,0) [0|1] ""  gtw
 SG_ PARK_sw024_reverbPeriod m24 : 16|16@1+ (1,0) [0|65535] "microseconds"  gtw
 SG_ PARK_sw076_messageID m76 : 16|16@1+ (1,0) [0|65535] ""  gtw
 SG_ PARK_sw036_sensorTemperature m36 : 16|16@1+ (0.1,-40) [-40|200] "deg"  gtw
 SG_ PARK_sw043_placeHolder m43 : 16|1@1+ (1,0) [0|1] ""  gtw
 SG_ PARK_sw025_placeHolder m25 : 16|1@1+ (1,0) [0|1] ""  gtw
 SG_ PARK_sw006_sensorTemperature m6 : 16|16@1+ (0.1,-40) [-40|200] "deg"  gtw
 SG_ PARK_sw044_reverbPeriod m44 : 16|16@1+ (1,0) [0|65535] "microseconds"  gtw
 SG_ PARK_sw028_placeHolder m28 : 16|1@1+ (1,0) [0|1] ""  gtw
 SG_ PARK_sw069_messageID m69 : 16|16@1+ (1,0) [0|65535] ""  gtw
 SG_ PARK_sw013_placeHolder m13 : 16|1@1+ (1,0) [0|1] ""  gtw
 SG_ PARK_sw019_reverbPeriod m19 : 16|16@1+ (1,0) [0|65535] "microseconds"  gtw
 SG_ PARK_sw056_sensorTemperature m56 : 16|16@1+ (0.1,-40) [-40|200] "deg"  gtw
 SG_ PARK_sw070_messageID m70 : 16|16@1+ (1,0) [0|65535] ""  gtw
 SG_ PARK_sw002_membraneDisconct m2 : 16|1@1+ (1,0) [0|1] ""  gtw
 SG_ PARK_sw050_placeHolder m50 : 16|1@1+ (1,0) [0|1] ""  gtw
 SG_ PARK_sw051_sensorTemperature m51 : 16|16@1+ (0.1,-40) [-40|200] "deg"  gtw
 SG_ PARK_sw034_reverbPeriod m34 : 16|16@1+ (1,0) [0|65535] "microseconds"  gtw
 SG_ PARK_sw083_errorExp m83 : 16|8@1+ (1,0) [0|255] ""  gtw
 SG_ PARK_sw007_membraneDisconct m7 : 16|1@1+ (1,0) [0|1] ""  gtw
 SG_ PARK_sw001_sensorTemperature m1 : 16|16@1+ (0.1,-40) [-40|200] "deg"  gtw
 SG_ PARK_sw066_placeHolder m66 : 16|1@1+ (1,0) [0|1] ""  gtw
 SG_ PARK_sw031_sensorTemperature m31 : 16|16@1+ (0.1,-40) [-40|200] "deg"  gtw
 SG_ PARK_sw071_messageID m71 : 16|16@1+ (1,0) [0|65535] ""  gtw
 SG_ PARK_sw054_reverbPeriod m54 : 16|16@1+ (1,0) [0|65535] "microseconds"  gtw
 SG_ PARK_sw009_reverbPeriod m9 : 16|16@1+ (1,0) [0|65535] "microseconds"  gtw
 SG_ PARK_sw030_placeHolder m30 : 16|1@1+ (1,0) [0|1] ""  gtw
 SG_ PARK_alertState : 15|1@1+ (1,0) [0|1] ""  gtw
 SG_ PARK_alertID M : 0|7@1+ (1,0) [0|86] ""  gtw

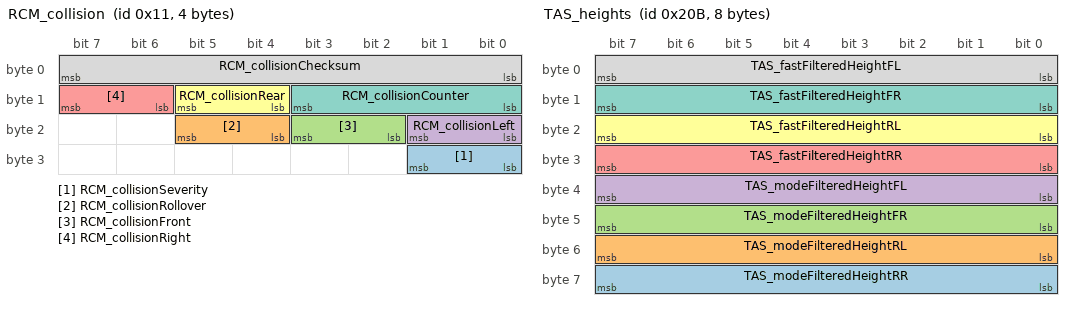
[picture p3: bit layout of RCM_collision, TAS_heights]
BO_ 17 RCM_collision: 4 CH
 SG_ RCM_collisionSeverity : 24|2@1+ (1,0) [0|3] ""  das
 SG_ RCM_collisionRollover : 20|2@1+ (1,0) [0|3] ""  das
 SG_ RCM_collisionFront : 18|2@1+ (1,0) [0|3] ""  das
 SG_ RCM_collisionLeft : 16|2@1+ (1,0) [0|3] ""  das
 SG_ RCM_collisionRight : 14|2@1+ (1,0) [0|3] ""  das
 SG_ RCM_collisionRear : 12|2@1+ (1,0) [0|3] ""  das
 SG_ RCM_collisionCounter : 8|4@1+ (1,0) [0|15] ""  gtw
 SG_ RCM_collisionChecksum : 0|8@1+ (1,0) [0|255] ""  gtw

BO_ 523 TAS_heights: 8 CH
 SG_ TAS_modeFilteredHeightRR : 56|8@1+ (1,-128) [-128|127] "mm"  gtw
 SG_ TAS_modeFilteredHeightRL : 48|8@1+ (1,-128) [-128|127] "mm"  gtw
 SG_ TAS_modeFilteredHeightFR : 40|8@1+ (1,-128) [-128|127] "mm"  gtw
 SG_ TAS_modeFilteredHeightFL : 32|8@1+ (1,-128) [-128|127] "mm"  gtw
 SG_ TAS_fastFilteredHeightRR : 24|8@1+ (1,-128) [-128|127] "mm"  gtw
 SG_ TAS_fastFilteredHeightRL : 16|8@1+ (1,-128) [-128|127] "mm"  gtw
 SG_ TAS_fastFilteredHeightFR : 8|8@1+ (1,-128) [-128|127] "mm"  gtw
 SG_ TAS_fastFilteredHeightFL : 0|8@1+ (1,-128) [-128|127] "mm"  gtw

BO_ 813 IBST_info: 8 CH
 SG_ IBST_infoComponentID m10 : 48|16@1+ (1,0) [0|65535] ""  gtw
 SG_ IBST_infoBootloaderCRC m20 : 32|32@1+ (1,0) [0|4294967295] ""  gtw
 SG_ IBST_infoVariantCRC m22 : 32|32@1+ (1,0) [0|4294967295] ""  gtw
 SG_ IBST_infoApplicationCRC m13 : 32|32@1+ (1,0) [0|4294967295] ""  gtw
 SG_ IBST_infoUsageID m11 : 32|16@1+ (1,0) [0|65535] ""  gtw
 SG_ IBST_infoAssemblyID m11 : 24|8@1+ (1,0) [0|255] ""  gtw
 SG_ IBST_infoPcbaID m11 : 16|8@1+ (1,0) [0|255] ""  gtw
 SG_ IBST_infoBootUdsProtoVersion m20 : 8|8@1+ (1,0) [0|255] ""  gtw
 SG_ IBST_infoBuildType m10 : 8|8@1+ (1,0) [0|4] ""  gtw
 SG_ IBST_infoIndex M : 0|8@1+ (1,0) [0|255] ""  gtw

BO_ 1016 UI_driverAssistControl: 8 CH
 SG_ UI_forksEnable : 63|1@1+ (1,0) [0|1] ""  das
 SG_ UI_source3D : 61|2@1+ (1,0) [0|2] ""  das
 SG_ UI_enableVisionOnlyStops : 60|1@1+ (1,0) [0|1] ""  das
 SG_ UI_enableCutinExperiments : 59|1@1+ (1,0) [0|1] ""  das
 SG_ UI_enableNavRouteCSA : 58|1@1+ (1,0) [0|1] ""  das
 SG_ UI_validationLoop : 57|1@1+ (1,0) [0|1] ""  das
 SG_ UI_alcOffHighwayEnable : 56|1@1+ (1,0) [0|1] ""  das
 SG_ UI_accFromZero : 55|1@1+ (1,0) [0|1] ""  das
 SG_ UI_autopilotAlwaysOn : 54|1@1+ (1,0) [0|1] ""  das
 SG_ UI_ulcBlindSpotConfig : 52|2@1+ (1,0) [0|2] ""  das
 SG_ UI_ulcSpeedConfig : 50|2@1+ (1,0) [0|3] ""  das
 SG_ UI_followNavRouteEnable : 49|1@1+ (1,0) [0|1] ""  das
 SG_ UI_hasDriveOnNav : 48|1@1+ (1,0) [0|1] ""  das
 SG_ UI_accFollowDistanceSetting : 45|3@1+ (1,0) [0|7] ""  das
 SG_ UI_enableRoadSegmentTelemetry : 44|1@1+ (1,0) [0|1] ""  app
 SG_ UI_enableTripTelemetry : 43|1@1+ (1,0) [0|1] ""  app
 SG_ UI_enableClipTelemetry : 42|1@1+ (1,0) [0|1] ""  app
 SG_ UI_drivingSide : 40|2@1+ (1,0) [0|2] ""  das
 SG_ UI_adaptiveSetSpeedEnable : 39|1@1+ (1,0) [0|1] ""  das
 SG_ UI_undertakeAssistEnable : 38|1@1+ (1,0) [0|1] ""  das
 SG_ UI_summonReverseDist : 32|6@1+ (1,0) [0|63] ""  das
 SG_ UI_selfParkRequest : 28|4@1+ (1,0) [0|15] ""  das
 SG_ UI_summonEntryType : 26|2@1+ (1,0) [0|3] ""  das
 SG_ UI_summonExitType : 24|2@1+ (1,0) [0|3] ""  das
 SG_ UI_lssElkEnabled : 23|1@1+ (1,0) [0|1] ""  das
 SG_ UI_curvatureDatabaseOnly : 22|1@1+ (1,0) [0|1] ""  das
 SG_ UI_visionSpeedType : 20|2@1+ (1,0) [0|3] ""  das
 SG_ UI_enableNextGenACC : 19|1@1+ (1,0) [0|1] ""  das
 SG_ UI_fuseVehiclesDisable : 18|1@1+ (1,0) [0|1] ""  das
 SG_ UI_fuseHPPDisable : 17|1@1+ (1,0) [0|1] ""  das
 SG_ UI_fuseLanesDisable : 16|1@1+ (1,0) [0|1] ""  das
 SG_ UI_ulcOffHighway : 15|1@1+ (1,0) [0|1] ""  das
 SG_ UI_handsOnRequirementDisable : 14|1@1+ (1,0) [0|1] ""  das
 SG_ UI_driveOnMapsEnable : 13|1@1+ (1,0) [0|1] ""  das
 SG_ UI_roadCheckDisable : 12|1@1+ (1,0) [0|1] ""  das
 SG_ UI_exceptionListEnable : 11|1@1+ (1,0) [0|1] ""  das
 SG_ UI_autoSummonEnable : 10|1@1+ (1,0) [0|1] ""  das
 SG_ UI_coastToCoast : 9|1@1+ (1,0) [0|1] ""  app
 SG_ UI_lssLdwEnabled : 8|1@1+ (1,0) [0|1] ""  das
 SG_ UI_lssLkaEnabled : 7|1@1+ (1,0) [0|1] ""  das
 SG_ UI_enableVinAssociation : 6|1@1+ (1,0) [0|1] ""  das
 SG_ UI_dasDeveloper : 5|1@1+ (1,0) [0|1] ""  das
 SG_ UI_curvSpeedAdaptDisable : 4|1@1+ (1,0) [0|1] ""  das
 SG_ UI_summonHeartbeat : 2|2@1+ (1,0) [0|3] ""  das
 SG_ UI_ulcStalkConfirm : 1|1@1+ (1,0) [0|1] ""  das
 SG_ UI_autopilotControlRequest : 0|1@1+ (1,0) [0|1] ""  das

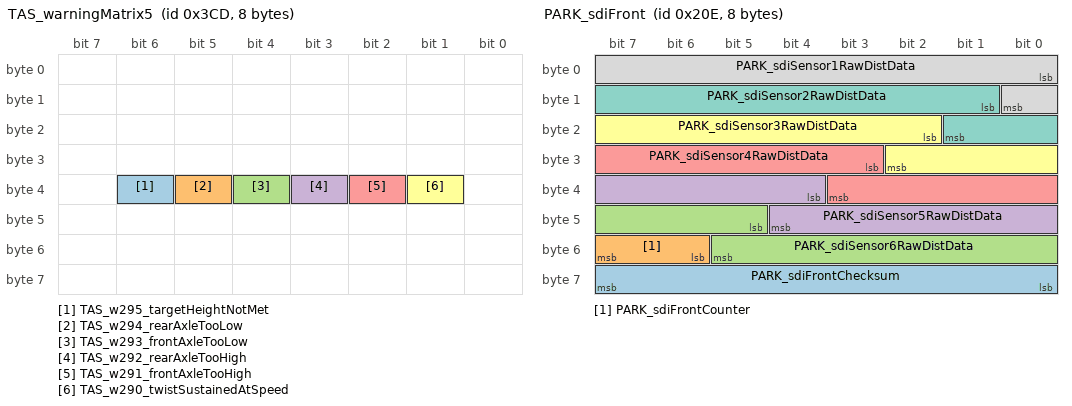
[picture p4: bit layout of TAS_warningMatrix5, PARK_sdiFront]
BO_ 973 TAS_warningMatrix5: 8 CH
 SG_ TAS_w295_targetHeightNotMet : 38|1@1+ (1,0) [0|1] ""  gtw
 SG_ TAS_w294_rearAxleTooLow : 37|1@1+ (1,0) [0|1] ""  gtw
 SG_ TAS_w293_frontAxleTooLow : 36|1@1+ (1,0) [0|1] ""  gtw
 SG_ TAS_w292_rearAxleTooHigh : 35|1@1+ (1,0) [0|1] ""  gtw
 SG_ TAS_w291_frontAxleTooHigh : 34|1@1+ (1,0) [0|1] ""  gtw
 SG_ TAS_w290_twistSustainedAtSpeed : 33|1@1+ (1,0) [0|1] ""  gtw

BO_ 526 PARK_sdiFront: 8 CH
 SG_ PARK_sdiFrontChecksum : 56|8@1+ (1,0) [0|255] ""  X
 SG_ PARK_sdiFrontCounter : 54|2@1+ (1,0) [0|3] ""  das
 SG_ PARK_sdiSensor6RawDistData : 45|9@1+ (1,0) [0|511] "cm"  das
 SG_ PARK_sdiSensor5RawDistData : 36|9@1+ (1,0) [0|511] "cm"  app
 SG_ PARK_sdiSensor4RawDistData : 27|9@1+ (1,0) [0|511] "cm"  app
 SG_ PARK_sdiSensor3RawDistData : 18|9@1+ (1,0) [0|511] "cm"  app
 SG_ PARK_sdiSensor2RawDistData : 9|9@1+ (1,0) [0|511] "cm"  app
 SG_ PARK_sdiSensor1RawDistData : 0|9@1+ (1,0) [0|511] "cm"  das

BO_ 1649 UDS_radcRequest: 8 CH
 SG_ UDS_radcRequestData : 7|64@0+ (1,0) [0|18446744073709551615] ""  aps

BO_ 680 EPBL_status: 8 CH
 SG_ EPBL_statusChecksum : 56|8@1+ (1,0) [0|255] ""  rcm
 SG_ EPBL_statusCounter : 52|4@1+ (1,0) [0|15] ""  rcm
 SG_ EPBL_blockDrive : 51|1@1+ (1,0) [0|1] ""  X
 SG_ EPBL_bothDisconnected : 50|1@1+ (1,0) [0|1] ""  X
 SG_ EPBL_winchModeAvailable : 49|1@1+ (1,0) [0|1] ""  X
 SG_ EPBL_hornRequest : 48|1@1+ (1,0) [0|1] ""  X
 SG_ EPBL_okToPark : 47|1@1+ (1,0) [0|1] ""  X
 SG_ EPBL_espPowerRequest : 46|1@1+ (1,0) [0|1] ""  X
 SG_ EPBL_winchModeTimer : 32|12@1+ (1,0) [0|4095] ""  X
 SG_ EPBL_brakeDiscWipeRequest : 30|2@1+ (1,0) [0|3] ""  X
 SG_ EPBL_cdpRequest : 27|1@1+ (1,0) [0|1] ""  X
 SG_ EPBL_updateMode : 24|1@1+ (1,0) [0|1] ""  X
 SG_ EPBL_winchModeActive : 23|1@1+ (1,0) [0|1] ""  X
 SG_ EPBL_requestUserConfirmation : 21|1@1+ (1,0) [0|1] ""  X
 SG_ EPBL_uiParkAvailable : 20|1@1+ (1,0) [0|1] ""  X
 SG_ EPBL_brakeHWConfigMismatch : 19|1@1+ (1,0) [0|1] ""  X
 SG_ EPBL_brakeLight : 18|1@1+ (1,0) [0|1] ""  X
 SG_ EPBL_summonEnabled : 17|1@1+ (1,0) [0|1] ""  X
 SG_ EPBL_telltale : 8|3@1+ (1,0) [0|7] ""  X
 SG_ EPBL_systemStatus : 0|4@1+ (1,0) [0|8] ""  park

BO_ 553 OCS1P_debugCushionSelfCNT: 8 CH
 SG_ OCS1P_cushionSelfCNTDuty : 32|32@1+ (1,0) [0|4294967295] ""  dbg
 SG_ OCS1P_cushionSelfCNTFreq : 0|32@1+ (1,0) [0|4294967295] ""  dbg

BO_ 590 PARK_pscVehSlot: 8 CH
 SG_ PARK_pscLeftCrossSizeY m1 : 56|8@1+ (4,0) [0|1020] "cm"  das
 SG_ PARK_pscRightParallelSizeY m2 : 56|8@1+ (4,0) [0|1020] "cm"  das
 SG_ PARK_pscLeftParallelSizeY m0 : 56|8@1+ (4,0) [0|1020] "cm"  das
 SG_ PARK_pscRightCrossSizeY m3 : 56|8@1+ (4,0) [0|1020] "cm"  das
 SG_ PARK_pscRightParallelSizeX m2 : 48|8@1+ (4,0) [0|1020] "cm"  das
 SG_ PARK_pscLeftParallelSizeX m0 : 48|8@1+ (4,0) [0|1020] "cm"  das
 SG_ PARK_pscLeftCrossSizeX m1 : 48|8@1+ (4,0) [0|1020] "cm"  das
 SG_ PARK_pscRightCrossSizeX m3 : 48|8@1+ (4,0) [0|1020] "cm"  das
 SG_ PARK_pscRightParallelPsi m2 : 32|13@1+ (0.0009765625,0) [0|7.9990234375] "radians"  das
 SG_ PARK_pscRightCrossPsi m3 : 32|13@1+ (0.0009765625,0) [0|7.9990234375] "radians"  das
 SG_ PARK_pscLeftCrossPsi m1 : 32|13@1+ (0.0009765625,0) [0|7.9990234375] "radians"  das
 SG_ PARK_pscLeftParallelPsi m0 : 32|13@1+ (0.0009765625,0) [0|7.9990234375] "radians"  das
 SG_ PARK_pscRightParallelVehY m2 : 16|11@1+ (2,-2048) [-2048|2046] "cm"  gtw
 SG_ PARK_pscLeftCrossVehY m1 : 16|11@1+ (2,-2048) [-2048|2046] "cm"  gtw
 SG_ PARK_pscRightCrossVehY m3 : 16|11@1+ (2,-2048) [-2048|2046] "cm"  gtw
 SG_ PARK_pscLeftParallelVehY m0 : 16|11@1+ (2,-2048) [-2048|2046] "cm"  gtw
 SG_ PARK_pscLeftCrossVehX m1 : 5|11@1+ (2,-2048) [-2048|2046] "cm"  gtw
 SG_ PARK_pscRightCrossVehX m3 : 5|11@1+ (2,-2048) [-2048|2046] "cm"  gtw
 SG_ PARK_pscRightParallelVehX m2 : 5|11@1+ (2,-2048) [-2048|2046] "cm"  gtw
 SG_ PARK_pscLeftParallelVehX m0 : 5|11@1+ (2,-2048) [-2048|2046] "cm"  gtw
 SG_ PARK_pscVehSlotType M : 0|2@1+ (1,0) [0|3] ""  das

BO_ 1645 IBST_bootID: 8 CH
 SG_ IBST_bootIdData : 0|64@1+ (1,0) [0|18446744073709551615] ""  gtwu

BO_ 1833 DBG_IsotermSMS: 8 CH
 SG_ DBG_IsotermSMS : 7|64@0+ (1,0) [0|18446744073709551615] ""  das

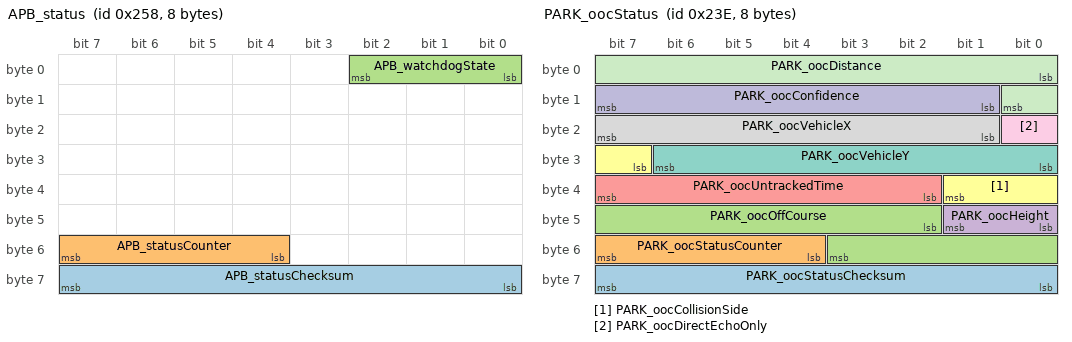
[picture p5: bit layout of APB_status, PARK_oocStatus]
BO_ 600 APB_status: 8 CH
 SG_ APB_statusChecksum : 56|8@1+ (1,0) [0|255] ""  aps
 SG_ APB_statusCounter : 52|4@1+ (1,0) [0|15] ""  aps
 SG_ APB_watchdogState : 0|3@1+ (1,0) [0|7] ""  aps

BO_ 1948 XCP_epbrRequest: 8 CH
 SG_ XCP_epbrRequest : 7|64@0+ (1,0) [0|18446744073709551615] ""  X

BO_ 574 PARK_oocStatus: 8 CH
 SG_ PARK_oocStatusChecksum : 56|8@1+ (1,0) [0|255] ""  X
 SG_ PARK_oocStatusCounter : 52|4@1+ (1,0) [0|15] ""  X
 SG_ PARK_oocOffCourse : 42|10@1+ (1,-512) [-512|511] "cm"  das
 SG_ PARK_oocHeight : 40|2@1+ (1,0) [0|3] ""  das
 SG_ PARK_oocUntrackedTime : 34|6@1+ (0.1,0) [0|6.3] "s"  das
 SG_ PARK_oocCollisionSide : 31|3@1+ (1,0) [0|7] ""  das
 SG_ PARK_oocVehicleY : 24|7@1+ (2,-128) [-128|126] "cm"  X
 SG_ PARK_oocVehicleX : 17|7@1+ (4,-114) [-114|394] "cm"  X
 SG_ PARK_oocDirectEchoOnly : 16|1@1+ (1,0) [0|1] ""  X
 SG_ PARK_oocConfidence : 9|7@1+ (1,0) [0|127] ""  das
 SG_ PARK_oocDistance : 0|9@1+ (1,0) [0|511] ""  das

BA_DEF_ SG_  "SystemSignalLongSymbol" STRING ;
BA_DEF_DEF_  "SystemSignalLongSymbol" "";
VAL_ 777 DAS_leadVeh2Id 0 "SNA" ;
VAL_ 777 DAS_leftVeh2Id 0 "SNA" ;
VAL_ 777 DAS_rightVeh2Id 0 "SNA" ;
VAL_ 777 DAS_cutinVehHeading 255 "SNA" ;
VAL_ 777 DAS_rightVeh2Heading 255 "SNA" ;
VAL_ 777 DAS_leftVeh2VxRel 15 "SNA" ;
VAL_ 777 DAS_rightVeh2VxRel 15 "SNA" ;
VAL_ 777 DAS_leadVeh2VxRel 15 "SNA" ;
VAL_ 777 DAS_rightVehHeading 255 "SNA" ;
VAL_ 777 DAS_leftVeh2Dx 255 "SNA" ;
VAL_ 777 DAS_rightVeh2Dx 255 "SNA" ;
VAL_ 777 DAS_leadVeh2Dx 255 "SNA" ;
VAL_ 777 DAS_leadVeh2Type 5 "PEDESTRIAN" 0 "UNKNOWN" 4 "BICYCLE" 3 "MOTORCYCLE" 2 "CAR" 1 "TRUCK" ;
VAL_ 777 DAS_leftVeh2Type 5 "PEDESTRIAN" 0 "UNKNOWN" 4 "BICYCLE" 3 "MOTORCYCLE" 2 "CAR" 1 "TRUCK" ;
VAL_ 777 DAS_rightVeh2Type 5 "PEDESTRIAN" 0 "UNKNOWN" 4 "BICYCLE" 3 "MOTORCYCLE" 2 "CAR" 1 "TRUCK" ;
VAL_ 777 DAS_leftVeh2Heading 255 "SNA" ;
VAL_ 777 DAS_roadSignOrientation 1 "VERTICAL_3_LIGHT" 0 "UNKNOWN" 2 "HORIZONTAL_3_LIGHT" ;
VAL_ 777 DAS_roadSignArrow 0 "CIRCLE" 4 "UNKNOWN" 1 "LEFT" 2 "RIGHT" 3 "STRAIGHT" ;
VAL_ 777 DAS_rightVehId 127 "SNA" ;
VAL_ 777 DAS_leadVehId 127 "SNA" ;
VAL_ 777 DAS_cutinVehId 127 "SNA" ;
VAL_ 777 DAS_leftVehId 127 "SNA" ;
VAL_ 777 DAS_roadSignSource 0 "NONE" 1 "NAV" 2 "VISION" ;
VAL_ 777 DAS_leftVehHeading 255 "SNA" ;
VAL_ 777 DAS_leadVehVxRel 15 "SNA" ;
VAL_ 777 DAS_cutinVehVxRel 15 "SNA" ;
VAL_ 777 DAS_rightVehVxRel 15 "SNA" ;
VAL_ 777 DAS_leftVehVxRel 15 "SNA" ;
VAL_ 777 DAS_leadVeh2Heading 255 "SNA" ;
VAL_ 777 DAS_roadSignStopLineDist 1023 "SNA" ;
VAL_ 777 DAS_rightVehDx 255 "SNA" ;
VAL_ 777 DAS_cutinVehDx 255 "SNA" ;
VAL_ 777 DAS_leftVehDx 255 "SNA" ;
VAL_ 777 DAS_leadVehDx 255 "SNA" ;
VAL_ 777 DAS_leadVehHeading 255 "SNA" ;
VAL_ 777 DAS_roadSignId 255 "SNA" 0 "STOP_SIGN" 1 "TRAFFIC_LIGHT" ;
VAL_ 777 DAS_leadVehType 5 "PEDESTRIAN" 0 "UNKNOWN" 4 "BICYCLE" 3 "MOTORCYCLE" 6 "IPSO" 2 "CAR" 1 "TRUCK" ;
VAL_ 777 DAS_rightVehType 5 "PEDESTRIAN" 0 "UNKNOWN" 4 "BICYCLE" 3 "MOTORCYCLE" 2 "CAR" 1 "TRUCK" ;
VAL_ 777 DAS_roadSignColor 0 "NONE" 1 "RED" 2 "YELLOW" 4 "RED_YELLOW" 3 "GREEN" ;
VAL_ 777 DAS_leftVehType 5 "PEDESTRIAN" 0 "UNKNOWN" 4 "BICYCLE" 3 "MOTORCYCLE" 2 "CAR" 1 "TRUCK" ;
VAL_ 777 DAS_cutinVehType 5 "PEDESTRIAN" 0 "UNKNOWN" 4 "BICYCLE" 3 "MOTORCYCLE" 2 "CAR" 1 "TRUCK" ;
VAL_ 777 DAS_objectId 2 "RIGHT_VEHICLES" 4 "ROAD_SIGN" 1 "LEFT_VEHICLES" 3 "CUTIN_VEHICLE" 0 "LEAD_VEHICLES" 5 "VEHICLE_HEADINGS" ;
VAL_ 737 VCFRONT_homelinkCommStatus 1 "HOMELINK_COMM_STATUS_OFF" 3 "HOMELINK_COMM_STATUS_FAULT" 2 "HOMELINK_COMM_STATUS_ON" 0 "HOMELINK_COMM_STATUS_SNA" ;
VAL_ 737 VCFRONT_pressureRefrigDischarge 255 "SNA" ;
VAL_ 737 VCFRONT_pressureRefrigSuction 127 "SNA" ;
VAL_ 737 VCFRONT_airCompressorStatus 5 "VCFRONT_AIR_COMPRESSOR_STATUS_RETRY_AVAILABLE" 3 "VCFRONT_AIR_COMPRESSOR_STATUS_TURNING_ON" 4 "VCFRONT_AIR_COMPRESSOR_STATUS_FAULT" 2 "VCFRONT_AIR_COMPRESSOR_STATUS_TURNING_OFF" 7 "VCFRONT_AIR_COMPRESSOR_STATUS_SNA" 1 "VCFRONT_AIR_COMPRESSOR_STATUS_ON" 0 "VCFRONT_AIR_COMPRESSOR_STATUS_OFF" ;
VAL_ 737 VCFRONT_AS8510Voltage 4095 "SNA" ;
VAL_ 737 VCFRONT_crashState 2 "CRASH_STATE_SEVERE" 0 "CRASH_STATE_IDLE" 1 "CRASH_STATE_MINOR" ;
VAL_ 737 VCFRONT_batterySMState 2 "BATTERY_SM_STATE_DISCHARGE" 7 "BATTERY_SM_STATE_FAULT" 0 "BATTERY_SM_STATE_INIT" 3 "BATTERY_SM_STATE_STANDBY" 4 "BATTERY_SM_STATE_RESISTANCE_ESTIMATION" 5 "BATTERY_SM_STATE_OTA_STANDBY" 6 "BATTERY_SM_STATE_DISCONNECTED_BATTERY_TEST" 1 "BATTERY_SM_STATE_CHARGE" ;
VAL_ 737 VCFRONT_crashDetectedType 1 "CRASH_DETECTED_TYPE_MINOR" 0 "CRASH_DETECTED_TYPE_NONE" 2 "CRASH_DETECTED_TYPE_SEVERE" ;
VAL_ 737 VCFRONT_vehicleStatusDBG 5 "VEHICLE_STATUS_SLEEP_SHUTDOWN" 12 "VEHICLE_STATUS_CONDITIONING" 9 "VEHICLE_STATUS_HV_UP_STANDBY" 13 "VEHICLE_STATUS_DRIVE" 6 "VEHICLE_STATUS_SLEEP_STANDBY" 4 "VEHICLE_STATUS_SYSTEM_CHECKS" 10 "VEHICLE_STATUS_ACCESSORY" 14 "VEHICLE_STATUS_CRASH" 2 "VEHICLE_STATUS_SILENT_WAKE" 16 "VEHICLE_STATUS_TURN_ON_RAILS" 1 "VEHICLE_STATUS_LOW_POWER_STANDBY" 8 "VEHICLE_STATUS_LV_AWAKE" 0 "VEHICLE_STATUS_INIT" 15 "VEHICLE_STATUS_OTA" 3 "VEHICLE_STATUS_BATTERY_POST_WAKE" 7 "VEHICLE_STATUS_LV_SHUTDOWN" 17 "VEHICLE_STATUS_RESET" 11 "VEHICLE_STATUS_ACCESSORY_PLUS" ;
VAL_ 737 VCFRONT_wiperState 2 "WIPER_STATE_FAULT" 12 "WIPER_STATE_INT_AUTO_HIGH" 9 "WIPER_STATE_CONT_FAST" 8 "WIPER_STATE_INTERMITTENT_LOW" 7 "WIPER_STATE_INTERMITTENT_HIGH" 0 "WIPER_STATE_SNA" 3 "WIPER_STATE_DELAYED_REST" 10 "WIPER_STATE_CONT_SLOW" 6 "WIPER_STATE_MOMENTARY_WIPE" 1 "WIPER_STATE_SERVICE" 5 "WIPER_STATE_WASH" 4 "WIPER_STATE_PARK" 11 "WIPER_STATE_INT_AUTO_LOW" ;
VAL_ 737 VCFRONT_vbatMonitorVoltage 4095 "SNA" ;
VAL_ 737 VCFRONT_iBoosterStateDBG 3 "IBOOSTER_WRITING_DATA_SHUTDOWN" 1 "IBOOSTER_ON" 0 "IBOOSTER_OFF" 4 "IBOOSTER_FORCE_OFF" 2 "IBOOSTER_GOING_DOWN" ;
VAL_ 737 VCFRONT_wiperPosition 0 "WIPER_POSITION_SNA" 1 "WIPER_POSITION_SERVICE" 2 "WIPER_POSITION_DEPRESSED_PARK" 3 "WIPER_POSITION_DELAYED_REST" 4 "WIPER_POSITION_WIPING" ;
VAL_ 737 VCFRONT_wiperSpeed 2 "WIPER_SPEED_1" 0 "WIPER_SPEED_SNA" 7 "WIPER_SPEED_LOW" 8 "WIPER_SPEED_HIGH" 3 "WIPER_SPEED_2" 5 "WIPER_SPEED_4" 4 "WIPER_SPEED_3" 6 "WIPER_SPEED_5" 1 "WIPER_SPEED_OFF" ;
VAL_ 737 VCFRONT_frunkLatchStatus 8 "LATCH_FAULT" 2 "LATCH_CLOSED" 1 "LATCH_OPENED" 3 "LATCH_CLOSING" 7 "LATCH_DEFAULT" 4 "LATCH_OPENING" 5 "LATCH_AJAR" 6 "LATCH_TIMEOUT" 0 "LATCH_SNA" ;
VAL_ 737 VCFRONT_statusIndex 5 "VCF_STS_IDX_INVALID" 4 "VCF_STS_IDX_LV_BATTERY_DEBUG" 0 "VCF_STS_IDX_BODY_CONTROLS" 3 "VCF_STS_IDX_REFRIGERANT_SYSTEM" 2 "VCF_STS_IDX_HOMELINK" 1 "VCF_STS_IDX_VEHICLE_AND_RAILS" ;
VAL_ 1030 DAS_eObjMultiplexer 4 "Mux4" 2 "Mux2" 5 "Mux5" 3 "Mux3" 0 "Mux0" 1 "Mux1" ;
VAL_ 1481 APS_sw060_collisionWarningSource 1 "SOURCE_FCW_VEHICLE" 4 "SOURCE_BCW_CIPV" 5 "SOURCE_BCW_CIPV2" 0 "SOURCE_FCW_PEDESTRIAN" 3 "SOURCE_BCW_CUTIN" 7 "SOURCE_BCW_PEDESTRIAN" 2 "SOURCE_STOPLINE" 6 "SOURCE_BCW_MCVLR" ;
VAL_ 1481 APS_sw139_overflowBus 3 "CAN_BUS_PT" 4 "CAN_BUS_PARK" 1 "CAN_BUS_CH" 5 "CAN_BUS_RAD1" 0 "CAN_BUS_PARTY" 2 "CAN_BUS_RAD0" ;
VAL_ 1481 APS_sw151_parkerType 1 "AP_PRIMARY" 0 "AP_BACKUP" ;
VAL_ 1481 APS_sw069_diAPState 6 "DI_APC_ABORTED" 8 "DI_APC_UNPARK_COMPLETE" 7 "DI_APC_RESUMED" 0 "DI_APC_UNAVAILABLE" 4 "DI_APC_COMPLETE" 5 "DI_APC_PAUSED" 1 "DI_APC_STANDBY" 3 "DI_APC_ACTIVE" 9 "DI_APC_SNA" 2 "DI_APC_STARTED" ;
VAL_ 1481 APS_sw151_recoveryPathway 1 "AP_RECOVERY_POWER_DOWN" 2 "AP_RECOVERY_LOCAL_BUILD_GPIO" 3 "AP_RECOVERY_HEALTHY_IN_PARK" 0 "AP_NO_RECOVERY_PATH" ;
VAL_ 1481 APS_sw199_abortCodePARK 31 "SNA" 15 "SYSTEM_SERVICE" 11 "HANDS_ON_DETECTED" 6 "MAX_SWA_DEV_EXCEEDED" 0 "NONE" 8 "OBSTACLE_ON_PATH" 1 "VELOCITY_TOO_HIGH" 17 "ERROR" 12 "VEHICLE_DYNAMICS_INTERVENTION" 10 "FULL_WARNING_ON_BOTH_SIDES" 5 "OFF_TRACK" 13 "EPAS_FAULT" 3 "NO_VALID_PATH" 9 "PARK_SPACE_TOO_SMALL" 4 "UNCONTROLLED_TRAVEL_DIST_REACHED" 16 "SYSTEM_FAULT" 14 "DAS_ABORT" 2 "MAX_NUM_OF_MOVES" 7 "MAX_YAW_ANGLE_REACHED" ;
VAL_ 1481 APS_sw151_diGear 1 "DI_GEAR_P" 0 "DI_GEAR_INVALID" 7 "DI_GEAR_SNA" 2 "DI_GEAR_R" 3 "DI_GEAR_N" 4 "DI_GEAR_D" ;
VAL_ 1481 APS_sw153_eacInternalState 1 "APS_EAC_STATE_MOMENTARY" 3 "APS_EAC_STATE_AUTOPARK" 5 "APS_EAC_STATE_OVERRIDE" 4 "APS_EAC_STATE_INHIBIT" 0 "APS_EAC_STATE_INIT" 2 "APS_EAC_STATE_CONTINUOUS" 7 "APS_EAC_NUM_STATES" 6 "APS_EAC_STATE_LSS" ;
VAL_ 1481 APS_sw151_apWatchDogState 1 "AP_WDOG_STATE_DEGRADED" 7 "AP_WDOG_STATE_SNA" 3 "AP_WDOG_STATE_HEALTHY" 0 "AP_WDOG_STATE_UNKNOWN" 2 "AP_WDOG_STATE_CRITICAL" ;
VAL_ 1481 APS_sw073_escalateLDWreason 0 "LC_ELDW_REASON_NONE" 1 "LC_ELDW_REASON_SINGLE_PULL" 3 "LC_ELDW_REASON_STW_TAKEOVER" 2 "LC_ELDW_REASON_DOUBLE_PULL" ;
VAL_ 1481 APS_sw227_sensorNumber 1 "SENSOR_MIDDLE" 0 "SENSOR_FRONT" ;
VAL_ 1481 APS_sw153_eacInhibitReason 5 "APS_EAC_FAULT_DAS_MIA" 2 "APS_EAC_FAULT_DURATION" 6 "APS_EAC_FAULT_DI_MIA" 1 "APS_EAC_FAULT_EPAS" 0 "APS_EAC_FAULT_NONE" 7 "APS_EAC_FAULT_LSS_DURATION" 3 "APS_EAC_FAULT_HYSTERESIS" 4 "APS_EAC_FAULT_EPAS_MIA" ;
VAL_ 1481 APS_sw135_appCriticalReason 4 "AP_CRITICAL_REASON_MIA" 2 "AP_CRITICAL_REASON_GPIO_CRITICAL" 3 "AP_CRITICAL_REASON_VERSION_MISMATCH" 0 "AP_CRITICAL_REASON_UNKNOWN" 5 "AP_CRITICAL_REASON_WATCHDOG_CRITICAL" 1 "AP_CRITICAL_REASON_BOOT_TIMEOUT" ;
VAL_ 1481 APS_sw227_sensorSide 0 "VEHICLE_SIDE_LEFT" 1 "VEHICLE_SIDE_RIGHT" ;
VAL_ 1481 APS_sw160_mismatchType 1 "AUTOPILOT_REPO_GITHASH" 0 "FIRMWARE_REPO_GITHASH" ;
VAL_ 1481 APS_sw132_mismatchType 1 "AUTOPILOT_REPO_GITHASH" 0 "FIRMWARE_REPO_GITHASH" ;
VAL_ 1481 APS_sw159_apbCriticalReason 4 "AP_CRITICAL_REASON_MIA" 2 "AP_CRITICAL_REASON_GPIO_CRITICAL" 3 "AP_CRITICAL_REASON_VERSION_MISMATCH" 0 "AP_CRITICAL_REASON_UNKNOWN" 5 "AP_CRITICAL_REASON_WATCHDOG_CRITICAL" 1 "AP_CRITICAL_REASON_BOOT_TIMEOUT" ;
VAL_ 1481 APS_sw042_health_state 3 "AP_HEALTH_SEVERELY_DEGRADED" 2 "AP_HEALTH_DEGRADED" 6 "AP_HEALTH_UNUSED" 7 "AP_HEALTH_SNA" 0 "AP_HEALTH_UNAVAILABLE" 5 "AP_HEALTH_FAULT" 4 "AP_HEALTH_ABORTING" 1 "AP_HEALTH_NOMINAL" ;
VAL_ 1481 APS_sw151_apGpioState 0 "AP_GPIO_STATE_PWR_DOWN_REBOOT" 3 "AP_GPIO_STATE_HEALTHY" 1 "AP_GPIO_STATE_DISABLED" 2 "AP_GPIO_STATE_CRITICAL" ;
VAL_ 1481 APS_alertState 0 "ALERT_CLEARED" 1 "ALERT_SET" ;
VAL_ 1481 APS_alertID 99 "APS_w099_DEPRECATED" 26 "APS_w026_ECU_timingIssue" 27 "APS_w027_ECU_Reset_Fault" 25 "APS_w025_LC_Steering_Override" 78 "APS_w078_pmmActive2" 10 "APS_w010_radcCalibIssue" 40 "APS_w040_autopilotAngleSaturated" 106 "APS_w106_torsionBarOffset" 228 "APS_w228_DEPRECATED" 19 "APS_w019_ECU_Stack_Overflow" 33 "APS_w033_gtwMia" 204 "APS_w204_apcFinalFront" 226 "APS_w226_lcCamCalNeededSpeedLmt" 133 "APS_w133_ETHSwitchError" 155 "APS_w155_ethLwipError" 134 "APS_w134_appMia" 230 "APS_w230_alcUltrasoundBlocked" 216 "APS_w216_driverOverriding" 66 "APS_w066_deserializerLockLost" 15 "APS_w015_Camera_Failsafes" 145 "APS_w145_vcrightMiaPartyBus" 86 "APS_w086_robCollision" 194 "APS_w194_accDriverResumeRqrd" 103 "APS_w103_robExperimentalAEB" 231 "APS_w231_idfEvent" 141 "APS_w141_rcmMiaPartyBus" 75 "APS_w075_scMia" 132 "APS_w132_appVersionMismatch" 62 "APS_w062_radcAlignment" 53 "APS_w053_radcCommIssue" 16 "APS_w016_aeb_e_event" 227 "APS_w227_virtualWallBlocked" 144 "APS_w144_vcleftMiaPartyBus" 150 "APS_w150_sccmMiaVehBus" 50 "APS_w050_aeb_event" 200 "APS_w200_lcSlowdown" 8 "APS_w008_parkDisabled" 7 "APS_w007_ahlbDisabled" 146 "APS_w146_epas3pMiaPartyBus" 89 "APS_w089_DEPRECATED" 100 "APS_w100_DEPRECATED" 1 "APS_w001_DEPRECATED" 136 "APS_w136_gpsDisabled" 90 "APS_w090_DEPRECATED" 197 "APS_w197_redLightWarning" 72 "APS_w072_selfparkComplete" 21 "APS_w021_ECU_Temperature_Issue" 205 "APS_w205_apcFinalRear" 68 "APS_w068_vlInconsistency" 17 "APS_w017_Cam_Msg_MIA" 207 "APS_w207_autosteerUnavailable" 105 "APS_w105_DEPRECATED" 9 "APS_w009_aebFault" 142 "APS_w142_diMiaPartyBus" 24 "APS_w024_ECU_Watchdog_Reset" 29 "APS_w029_spi_tx_error" 135 "APS_w135_appCritical" 95 "APS_w095_DEPRECATED" 35 "APS_w035_espMia" 44 "APS_w044_appMobileyeFailure" 138 "APS_w138_gpsComIssue" 96 "APS_w096_DEPRECATED" 43 "APS_w043_camLongRunTime" 206 "APS_w206_autosteerNotEnabled" 152 "APS_w152_gpsFusionStatus" 211 "APS_w211_accNoSeatBelt" 217 "APS_w217_lcUnavailableSpeeding" 224 "APS_w224_accCameraCalibration" 139 "APS_w139_udpBufferOverflow" 23 "APS_w023_ECU_Cam_Statemismatc" 137 "APS_w137_gpsFaultReset" 22 "APS_w022_ECU_EEPROM_Failure" 45 "APS_w045_radMia" 214 "APS_w214_driverNotIntracting" 74 "APS_w074_inPathStationaryObst" 130 "APS_w130_ECU_Thermal_Issue" 71 "APS_w071_selfparkStarted" 41 "APS_w041_autopilotRateSaturated" 63 "APS_w063_parkVersionMismatch" 131 "APS_w131_trap_exception" 82 "APS_w082_inPathFSviolation" 52 "APS_w052_radcSensorIssue" 38 "APS_w038_camFailure" 47 "APS_w047_edrEvent" 61 "APS_w061_tasMia" 215 "APS_w215_contDriverNotIntracting" 57 "APS_w057_mcuMia" 77 "APS_w077_pmmActive" 225 "APS_w225_lcDegradedVisSpeedLmt" 199 "APS_w199_apcAbort" 65 "APS_w065_deserializerOvercurrent" 221 "APS_w221_accRadarBlind" 88 "APS_w088_DEPRECATED" 84 "APS_w084_pmmIPSO" 32 "APS_w032_canTxError" 39 "APS_w039_sdm_rcm_Mia" 153 "APS_w153_eacInhibit" 91 "APS_w091_DEPRECATED" 0 "APS_ALERT_DO_NOT_USE_ZERO" 220 "APS_w220_lcTempUnavailableRoad" 193 "APS_w193_camWindshieldUnclean" 59 "APS_w059_parkMia" 101 "APS_w101_DEPRECATED" 102 "APS_w102_DEPRECATED" 158 "APS_w158_apbMia" 160 "APS_w160_apbVersionMismatch" 55 "APS_w055_radcVersionMismatch" 210 "APS_w210_camObstrcted" 51 "APS_w051_radcEcuIssue" 92 "APS_w092_DEPRECATED" 30 "APS_w030_Heater_Issue" 148 "APS_w148_vcrightMiaVehBus" 28 "APS_w028_spi_rx_error" 156 "APS_w156_lwipAssert" 209 "APS_w209_autoSummonRequest" 81 "APS_w081_pmmActiveBraking" 198 "APS_w198_tsrUnavailable" 58 "APS_w058_epbMia" 203 "APS_w203_apcActivation" 151 "APS_w151_apRecovered" 97 "APS_w097_DEPRECATED" 36 "APS_w036_bdyMia" 222 "APS_w222_accCameraBlind" 143 "APS_w143_espMiaPartyBus" 208 "APS_w208_rackDetected" 13 "APS_w013_Cam_Watchdog" 196 "APS_w196_stopSignWarning" 129 "APS_w129_ECU_Power_Issue" 60 "APS_w060_fcw_event" 202 "APS_w202_scwNoisyEnvironment" 195 "APS_w195_scwUnavailable" 46 "APS_w046_eepromRecordAbsent" 140 "APS_w140_vcfrontMiaVehicleBus" 85 "APS_w085_pmmSteering" 64 "APS_w064_epasMia" 3 "APS_w003_isaDisabled" 98 "APS_w098_DEPRECATED" 20 "APS_w020_ECU_checkstopError" 212 "APS_w212_lcUnavailableStrikeOut" 12 "APS_w012_Cam_BootFailure" 223 "APS_w223_accObjectInPath" 70 "APS_w070_apcIncompleteCal" 159 "APS_w159_apbCritical" 218 "APS_w218_lcSpeedExceededLimit" 229 "APS_w229_alcUltrasoundDamaged" 2 "APS_w002_ldwDisabled" 4 "APS_w004_accDisabled" 42 "APS_w042_autopilotAborting" 149 "APS_w149_epblMiaVehBus" 48 "APS_w048_DAS_Features_Disabled" 11 "APS_w011_scaEvent" 87 "APS_w087_DEPRECATED" 147 "APS_w147_vcleftMiaVehBus" 80 "APS_w080_accFailedActivation" 201 "APS_w201_lcAborting" 54 "APS_w054_camAutofix" 73 "APS_w073_issueEscalatedLDW" 67 "APS_w067_steeringAlignment" 6 "APS_w006_aebCancelled" 157 "APS_w157_autopilotReboot" 56 "APS_w056_diMia" 93 "APS_w093_DEPRECATED" 14 "APS_w014_swAssert" 83 "APS_w083_inPathRADObject" 49 "APS_w049_eyeqVersionMismatch" 76 "APS_w076_mobilEyeSetC" 34 "APS_w034_sccmMia" 5 "APS_w005_fcwCancelled" 213 "APS_w213_autosteerStruckOut" 37 "APS_w037_camTacIssue" 31 "APS_w031_canRxError" 219 "APS_w219_lcTempUnavailableSpeed" 104 "APS_w104_DEPRECATED" 69 "APS_w069_apcSpaceMasked" 94 "APS_w094_DEPRECATED" 79 "APS_w079_edrAvailable" 18 "APS_w018_ECU_Power_Issue" 161 "APS_w161_gpsAntennaDisconnected" ;
VAL_ 925 IBST_internalState 5 "TRANSITION_TO_IDLE" 0 "NO_MODE_ACTIVE" 4 "DIAGNOSTIC" 6 "POST_DRIVE_CHECK" 1 "PRE_DRIVE_CHECK" 3 "EXTERNAL_BRAKE_REQUEST" 2 "LOCAL_BRAKE_REQUEST" ;
VAL_ 925 IBST_driverBrakeApply 1 "BRAKES_NOT_APPLIED" 2 "DRIVER_APPLYING_BRAKES" 3 "FAULT" 0 "NOT_INIT_OR_OFF" ;
VAL_ 925 IBST_iBoosterStatus 6 "IBOOSTER_ACTUATION" 4 "IBOOSTER_ACTIVE_GOOD_CHECK" 2 "IBOOSTER_FAILURE" 5 "IBOOSTER_READY" 3 "IBOOSTER_DIAGNOSTIC" 0 "IBOOSTER_OFF" 1 "IBOOSTER_INIT" ;
VAL_ 49 EPAS3P_role 1 "SLAVE" 0 "MASTER" 2 "RESERVED" ;
VAL_ 49 EPAS3P_powerMode 7 "SNA" 2 "DRIVE_ON" 6 "POWERING_DOWN" 0 "DRIVE_OFF" 5 "LIMP_3" 1 "EMERGENCY_ON" 4 "LIMP_2" 3 "LIMP_1" ;
VAL_ 49 EPAS3P_state 2 "INIT_COMPLETE" 7 "EAC_ACTIVE" 4 "PASSIVE_FAULTED" 6 "ASSIST_STANDBY" 3 "PASSIVE" 0 "INIT_ARBITRATION" 15 "INVALID" 1 "INIT_PHASECUT_TEST" 5 "ASSIST_ACTIVE" 8 "EAC_STANDBY" ;
VAL_ 1349 VCFRONT_vcrightVoltage 4095 "SNA" ;
VAL_ 1349 VCFRONT_vcleftVoltage 4095 "SNA" ;
VAL_ 1349 VCFRONT_vcrightCurrent 4095 "SNA" ;
VAL_ 1349 VCFRONT_loadShedPumps_duty 127 "SNA" ;
VAL_ 1349 VCFRONT_loadShedBlower_duty 127 "SNA" ;
VAL_ 1349 VCFRONT_vcleftCurrent 4095 "SNA" ;
VAL_ 1349 VCFRONT_loadShedSMState 0 "LOADSHED_SM_STATE_INIT" 3 "LOADSHED_SM_STATE_CRITICAL" 1 "LOADSHED_SM_STATE_IDLE" 2 "LOADSHED_SM_STATE_PARTIAL" ;
VAL_ 1349 VCFRONT_systemStatusMuxIndex 0 "SYSTEM_DATA" 1 "LOADSHED_REQUESTS" ;
VAL_ 986 DAS_TE_lcAbortReason 19 "SIDE_COLLISION_IMMINENT" 31 "NO_ABORT" 24 "DRIVING_OFF_NAV" 20 "EPAS_EAC_DENIED" 28 "EPAS_ERROR_CODE" 21 "COMPONENT_MIA" 26 "FOLLOWER_OUTPUT_INVALID" 16 "CAM_MSG_MIA" 1 "HM_VIRTUAL_LANE_NO_INPUTS" 27 "PLANNER_OUTPUT_INVALID" 23 "CID_SWITCH_DISABLED" 17 "CAM_WATCHDOG" 29 "ACC_CANCEL" 25 "VEHICLE_SPEED_ABOVE_MAX" 0 "HM_LANE_VIEW_RANGE" 30 "CAMERA_FAILSAFES" 22 "CRUISE_FAULT" 18 "TRAILER_MODE" ;
VAL_ 986 DAS_TE_eventType 8 "ALC_ABORT_RIGHT" 1 "DRIVER_INTERVENTION" 4 "ANGLE_RATE_SATURATION" 3 "ANGLE_SATURATION" 0 "NONE" 6 "LDW_RIGHT" 13 "TM_EVENT_AEB" 7 "ALC_ABORT_LEFT" 2 "AUTOSTEER_ABORT" 14 "TM_EVENT_ROB" 9 "SCA_LEFT" 11 "TM_EVENT_IPSO" 5 "LDW_LEFT" 10 "SCA_RIGHT" 12 "TM_EVENT_CRASH" ;
VAL_ 986 DAS_TE_multiplexer 5 "VL" 1 "LEFT_LANE" 7 "FCM" 0 "START" 2 "RIGHT_LANE" 4 "NAV" 9 "END" 8 "IPSO" 3 "HPP" 6 "ACC" ;
VAL_ 1352 APB_buildType 0 "AP_BUILDTYPE_SIGNED" 3 "AP_BUILDTYPE_REPO" 1 "AP_BUILDTYPE_LOCAL" ;
VAL_ 1352 APB_infoIndex 0 "AP_BUILD_TYPE" 1 "FW_GITHASH" 2 "AP_GITHASH" ;
VAL_ 856 UI_sizeOfWheelSelect 0 "UNUSED" 2 "19_INCH_WHEEL" 1 "18_INCH_WHEEL" ;
VAL_ 856 UI_TPMSLearnIDMode 0 "NO_ID_LEARN_FUNCTION" 4 "AUTO_LOCATION_ACTIVE_AFTER_PWR" 2 "AUTO_LOCATION_ACTIVE_BY_MANUAL" 1 "AUTO_LEARN_ACTIVE_BY_MANUAL" 3 "AUTO_LEARN_ACTIVE_AFTER_PWR" ;
VAL_ 856 UI_TPMSMode 1 "TPMS_NORMAL_MODE" 0 "TPMS_UNUSED_MODE" 2 "TPMS_PERFORMANCE_MODE" ;
VAL_ 1821 DBG_cpLatch2MotorDirection 0 "DBG_CP_LATCH_MOTOR_ENGAGED" 1 "DBG_CP_LATCH_MOTOR_DISENGAGED" ;
VAL_ 1821 DBG_cpLatchMotorDirection 0 "DBG_CP_LATCH_MOTOR_ENGAGED" 1 "DBG_CP_LATCH_MOTOR_DISENGAGED" ;
VAL_ 1821 DBG_cpDoorMotorDirection 0 "DBG_CP_DOOR_MOTOR_CLOSED" 1 "DBG_CP_DOOR_MOTOR_OPEN" ;
VAL_ 1821 DBG_CP_debugControls_dataSelect 3 "CP_debug_dataSelect3" 0 "CP_debug_dataSelect0" 1 "CP_debug_dataSelect1" 4 "CP_debug_dataSelect4" ;
VAL_ 1019 UI_alcViewRangeSensitivity 0 "ALC_VIEW_RANGE_SENSITIVITY_DEFAULT" 2 "ALC_VIEW_RANGE_SENSITIVITY_LOW" 3 "ALC_VIEW_RANGE_SENSITIVITY_OFF" 1 "ALC_VIEW_RANGE_SENSITIVITY_HIGH" ;
VAL_ 1019 UI_alcAssertivenessRate 1 "ALC_ASSERTIVE_LESS" 0 "ALC_ASSERTIVE_DEFAULT" 2 "ALC_ASSERTIVE_OFF" ;
VAL_ 1019 UI_alcMergingIntervalHeadwayHyst 1 "ALC_AGGRESSIVENESS_LESS" 2 "ALC_AGGRESSIVENESS_EVEN_LESS" 0 "ALC_AGGRESSIVENESS_DEFAULT" 3 "ALC_AGGRESSIVENESS_OFF" ;
VAL_ 1019 UI_alcMergIntervalRearDHyst 1 "ALC_AGGRESSIVENESS_LESS" 2 "ALC_AGGRESSIVENESS_EVEN_LESS" 0 "ALC_AGGRESSIVENESS_DEFAULT" 3 "ALC_AGGRESSIVENESS_OFF" ;
VAL_ 1019 UI_alcEgoLeadingReactionAccel 1 "ALC_AGGRESSIVENESS_LESS" 2 "ALC_AGGRESSIVENESS_EVEN_LESS" 0 "ALC_AGGRESSIVENESS_DEFAULT" 3 "ALC_AGGRESSIVENESS_OFF" ;
VAL_ 1019 UI_alcUltrasonicWaitTime 4 "ALC_ULTRASONIC_WAIT_TIME_0P5_S" 0 "ALC_ULTRASONIC_WAIT_TIME_DEFAULT" 3 "ALC_ULTRASONIC_WAIT_TIME_0P25_S" 5 "ALC_ULTRASONIC_WAIT_TIME_0P75_S" 1 "ALC_ULTRASONIC_WAIT_TIME_0P1_S" 6 "ALC_ULTRASONIC_WAIT_TIME_1_S" 7 "ALC_ULTRASONIC_WAIT_TIME_OFF" ;
VAL_ 1019 UI_alcUltrasonicDistance 8 "ALC_ULTRASONIC_DISTANCE_4P5_M" 0 "ALC_ULTRASONIC_DISTANCE_DEFAULT" 4 "ALC_ULTRASONIC_DISTANCE_3P5_M" 2 "ALC_ULTRASONIC_DISTANCE_2P5_M" 1 "ALC_ULTRASONIC_DISTANCE_2_M" 6 "ALC_ULTRASONIC_DISTANCE_4_M" 3 "ALC_ULTRASONIC_DISTANCE_3_M" 7 "ALC_ULTRASONIC_DISTANCE_OFF" 5 "ALC_ULTRASONIC_DISTANCE_5_M" ;
VAL_ 1019 UI_alcDisableUltrasonicCheck 0 "ALC_DISABLE_ULTRASONIC_CHECK_OFF" 1 "ALC_DISABLE_ULTRASONIC_CHECK_ON" ;
VAL_ 1019 UI_donMinGoreWidthForAbortNotMap 0 "DON_MIN_GORE_WIDTH_FOR_ABORT_DEFAULT" 3 "DON_MIN_GORE_WIDTH_FOR_ABORT_1_M" 10 "DON_MIN_GORE_WIDTH_FOR_ABORT_4P5_M" 6 "DON_MIN_GORE_WIDTH_FOR_ABORT_2P5_M" 1 "DON_MIN_GORE_WIDTH_FOR_ABORT_0_M" 8 "DON_MIN_GORE_WIDTH_FOR_ABORT_3P5_M" 7 "DON_MIN_GORE_WIDTH_FOR_ABORT_3_M" 5 "DON_MIN_GORE_WIDTH_FOR_ABORT_2_M" 2 "DON_MIN_GORE_WIDTH_FOR_ABORT_0P5_M" 11 "DON_MIN_GORE_WIDTH_FOR_ABORT_5_M" 4 "DON_MIN_GORE_WIDTH_FOR_ABORT_1P5_M" 9 "DON_MIN_GORE_WIDTH_FOR_ABORT_4_M" ;
VAL_ 1019 UI_donAlcProgGoreAbortThres 1 "DON_ALC_PROGRESS_GORE_ABORT_THRESHOLD_0P00" 7 "DON_ALC_PROGRESS_GORE_ABORT_THRESHOLD_0P30" 0 "DON_ALC_PROGRESS_GORE_ABORT_THRESHOLD_DEFAULT" 4 "DON_ALC_PROGRESS_GORE_ABORT_THRESHOLD_0P15" 6 "DON_ALC_PROGRESS_GORE_ABORT_THRESHOLD_0P25" 5 "DON_ALC_PROGRESS_GORE_ABORT_THRESHOLD_0P20" 8 "DON_ALC_PROGRESS_GORE_ABORT_THRESHOLD_0P35" 3 "DON_ALC_PROGRESS_GORE_ABORT_THRESHOLD_0P10" 9 "DON_ALC_PROGRESS_GORE_ABORT_THRESHOLD_0P40" 2 "DON_ALC_PROGRESS_GORE_ABORT_THRESHOLD_0P05" ;
VAL_ 1019 UI_donMinGoreWidthForAbortMap 0 "DON_MIN_GORE_WIDTH_FOR_ABORT_DEFAULT" 3 "DON_MIN_GORE_WIDTH_FOR_ABORT_1_M" 10 "DON_MIN_GORE_WIDTH_FOR_ABORT_4P5_M" 6 "DON_MIN_GORE_WIDTH_FOR_ABORT_2P5_M" 1 "DON_MIN_GORE_WIDTH_FOR_ABORT_0_M" 8 "DON_MIN_GORE_WIDTH_FOR_ABORT_3P5_M" 7 "DON_MIN_GORE_WIDTH_FOR_ABORT_3_M" 5 "DON_MIN_GORE_WIDTH_FOR_ABORT_2_M" 2 "DON_MIN_GORE_WIDTH_FOR_ABORT_0P5_M" 11 "DON_MIN_GORE_WIDTH_FOR_ABORT_5_M" 4 "DON_MIN_GORE_WIDTH_FOR_ABORT_1P5_M" 9 "DON_MIN_GORE_WIDTH_FOR_ABORT_4_M" ;
VAL_ 1019 UI_donDisableCutin 1 "DON_DISABLE_CUTIN_ON" 0 "DON_DISABLE_CUTIN_OFF" ;
VAL_ 1019 UI_donStopEndOfRampBuffer 2 "DON_STOP_END_OF_RAMP_BUFFER_30_M" 4 "DON_STOP_END_OF_RAMP_BUFFER_OFF" 1 "DON_STOP_END_OF_RAMP_BUFFER_15_M" 0 "DON_STOP_END_OF_RAMP_BUFFER_DEFAULT" 3 "DON_STOP_END_OF_RAMP_BUFFER_45_M" ;
VAL_ 1019 UI_blindspotTTC 1 "BLINDSPOT_TTC_0P5_S" 6 "BLINDSPOT_TTC_5_S" 0 "BLINDSPOT_TTC_DEFAULT" 3 "BLINDSPOT_TTC_2_S" 5 "BLINDSPOT_TTC_3_S" 2 "BLINDSPOT_TTC_1_S" 4 "BLINDSPOT_TTC_4_S" 7 "BLINDSPOT_TTC_OFF" ;
VAL_ 1019 UI_blindspotDistance 4 "BLINDSPOT_DISTANCE_4_M" 5 "BLINDSPOT_DISTANCE_OFF" 1 "BLINDSPOT_DISTANCE_0P5_M" 2 "BLINDSPOT_DISTANCE_1_M" 0 "BLINDSPOT_DISTANCE_DEFAULT" 3 "BLINDSPOT_DISTANCE_2_M" ;
VAL_ 1019 UI_blindspotMinSpeed 8 "BLINDSPOT_MIN_SPEED_40_KPH" 2 "BLINDSPOT_MIN_SPEED_10_KPH" 7 "BLINDSPOT_MIN_SPEED_35_KPH" 10 "BLINDSPOT_MIN_SPEED_OFF" 1 "BLINDSPOT_MIN_SPEED_5_KPH" 4 "BLINDSPOT_MIN_SPEED_20_KPH" 0 "BLINDSPOT_MIN_SPEED_DEFAULT" 5 "BLINDSPOT_MIN_SPEED_25_KPH" 3 "BLINDSPOT_MIN_SPEED_15_KPH" 9 "BLINDSPOT_MIN_SPEED_45_KPH" 6 "BLINDSPOT_MIN_SPEED_30_KPH" ;
VAL_ 1019 UI_camBlockBlurDisable 1 "CAMERA_BLOCKAGE_BLURINESS_DISABLE" 0 "CAMERA_BLOCKAGE_BLURINESS_DEFAULT" ;
VAL_ 1019 UI_donDisableOnAutoWiperSpeed 3 "DAS_WIPER_SPEED_3" 12 "DAS_WIPER_SPEED_12" 8 "DAS_WIPER_SPEED_8" 14 "DAS_WIPER_SPEED_14" 5 "DAS_WIPER_SPEED_5" 13 "DAS_WIPER_SPEED_13" 2 "DAS_WIPER_SPEED_2" 0 "DAS_WIPER_SPEED_OFF" 4 "DAS_WIPER_SPEED_4" 1 "DAS_WIPER_SPEED_1" 15 "DAS_WIPER_SPEED_INVALID" 10 "DAS_WIPER_SPEED_10" 11 "DAS_WIPER_SPEED_11" 7 "DAS_WIPER_SPEED_7" 9 "DAS_WIPER_SPEED_9" 6 "DAS_WIPER_SPEED_6" ;
VAL_ 1019 UI_donDisableAutoWiperDuration 1 "DON_DISABLE_AUTO_WIPER_DURATION_5_S" 0 "DON_DISABLE_AUTO_WIPER_DURATION_DEFAULT" 2 "DON_DISABLE_AUTO_WIPER_DURATION_15_S" 5 "DON_DISABLE_AUTO_WIPER_DURATION_120_S" 4 "DON_DISABLE_AUTO_WIPER_DURATION_60_S" 6 "DON_DISABLE_AUTO_WIPER_DURATION_OFF" 3 "DON_DISABLE_AUTO_WIPER_DURATION_30_S" ;
VAL_ 1019 UI_camBlockLaneCheckDisable 0 "CAMERA_BLOCKAGE_PERSISTANCE_DEFAULT" 1 "CAMERA_BLOCKAGE_PERSISTANCE_DISABLE" ;
VAL_ 1019 UI_hovEnabled 1 "HOV_ON" 0 "HOV_OFF" ;
VAL_ 1019 UI_autopilotControlIndex 1 "AUTOPILOT_CONTROL_1" 6 "AUTOPILOT_CONTROL_6" 7 "AUTOPILOT_CONTROL_7" 2 "AUTOPILOT_CONTROL_2" 4 "AUTOPILOT_CONTROL_4" 3 "AUTOPILOT_CONTROL_3" 5 "AUTOPILOT_CONTROL_5" 0 "AUTOPILOT_CONTROL_0" ;
VAL_ 1497 DAS_driveOnNavUnavailableReason 0 "DON_UNAVAILABLE_NONE" 9 "DON_AUTO_WIPER_ACTIVE" 10 "DON_CONSTRUCTION_DETECTED" 11 "DON_TOLLBOOTH_DETECTED" 14 "DON_AUTOPILOT_UNAVAILABLE" 3 "DON_UNAVAILABLE_CAMERA_BLOCKED" 4 "DON_ROUTE_DOWNLOAD_FAILED" 16 "DON_NAV_ROUTE_NOT_ACTIVE" 1 "DON_INVALID_NAV_GOAL" 13 "DON_INCOMPATIBLE_WAY" 8 "DON_IMPLAUSIBLE_MAP_DATA" 12 "DON_HIGH_CURVATURE" 2 "DON_CAMERA_UNAVAILABLE" 15 "DON_FEATURE_NOT_ENABLED" 5 "DON_EDGE_LOCALIZATION_FAILED" 7 "DON_GPS_DEGRADED" 6 "DON_ULTRASONICS_INVALID" ;
VAL_ 1497 DAS_handsOnDetected 2 "HANDS_ON_DETECTED" 1 "HANDS_ON_NOT_DETECTED" 0 "HANDS_ON_SNA" ;
VAL_ 1497 DAS_aeb_not_activating_reason 9 "LCM_AEB_OVERRIDE" 4 "LCM_AEB_RELATIVE_VELOCITY" 10 "LCM_AEB_ACTIVE" 15 "LCM_AEB_RAD_NOT_ASSOCIATED" 2 "LCM_AEB_NO_COLLISION_OBJECT" 6 "LCM_AEB_CURRENT_REQUIRED_ACCELERATION" 3 "LCM_AEB_ABSOLUTE_ACCELERATION" 8 "LCM_AEB_DELAYED_EVADING_DISTANCE" 13 "LCM_AEB_CAMERA_CROSS_CHECK" 5 "LCM_AEB_COLLISION_OVERLAP_RATIO" 11 "LCM_AEB_OTHER" 7 "LCM_AEB_DELAYED_REQUIRED_ACCELERATION" 0 "LCM_AEB_FAULT" 12 "LCM_AEB_YOUNG_TRACK" 14 "LCM_AEB_CAM_NOT_ASSOCIATED" 1 "LCM_AEB_UNAVAILABLE" ;
VAL_ 1497 DAS_ACC_camStatus 3 "ACC_CAM_STATUS_FAULT" 2 "ACC_CAM_STATUS_SQUINTING" 1 "ACC_CAM_STATUS_BLIND" 0 "ACC_CAM_STATUS_HEALTHY" ;
VAL_ 1497 DAS_LC_handsOnReason 6 "VISUAL_TIMEOUT_LONG_TERM" 23 "VISUAL_ULC_REQUEST" 10 "VISUAL_TIMEOUT_CONSTRUCTION" 14 "VISUAL_TIMEOUT_RESTRICTED" 20 "CHIME1_DRIVABLE_SPACE_VIOLATION" 17 "VISUAL_ALC" 16 "VISUAL_LATERAL_ACCELERATION" 11 "VISUAL_TIMEOUT_CUTOUT_CIPV" 0 "LC_HANDS_ON_REASON_NONE" 5 "VISUAL_DRIVER_NOT_PRESENT" 4 "VISUAL_FUSION_MODEL" 8 "VISUAL_TIMEOUT_MED_SPEED" 12 "VISUAL_TIMEOUT_CIPV" 24 "VISUAL_TIMEOUT_HOMOLOGATION" 1 "CHIME1_ANGLE_SATURATION" 22 "CHIME1_TOLL_BOOTH" 2 "CHIME1_CONSTRUCTION" 21 "CHIME1_STATIONARY_RADAR" 18 "CHIME1_NO_LINES" 19 "CHIME1_RE_DEGRADED_MEASUREMENTS" 13 "VISUAL_TIMEOUT_NO_CIPV" 3 "VISUAL_FUSION_NAV" 15 "VISUAL_TIMEOUT_ACCELERATOR" 9 "VISUAL_TIMEOUT_LOW_SPEED" 7 "VISUAL_TIMEOUT_HI_SPEED" ;
VAL_ 1497 DAS_associated_rad_object 1 "OTHER" 0 "NONE" 3 "ACC1" 2 "ACC5" ;
VAL_ 1497 DAS_carLogMultiplexer 2 "FCM" 3 "PROFILER" 1 "RADAR" ;
VAL_ 926 PARK_leftSideRearRawDistData 255 "SNA" ;
VAL_ 926 PARK_leftSideFrontRawDistData 255 "SNA" ;
VAL_ 926 PARK_rightSideRearRawDistData 255 "SNA" ;
VAL_ 926 PARK_rightSideFrontRawDistData 255 "SNA" ;
VAL_ 880 EPAS3S_eacStatus 7 "SNA" 2 "EAC_ACTIVE" 4 "LANE_KEEP_ASSIST" 3 "EAC_FAULT" 1 "EAC_AVAILABLE" 5 "EMERGENCY_LANE_KEEP" 0 "EAC_INHIBITED" ;
VAL_ 880 EPAS3S_handsOnLevel 1 "LEVEL_1" 0 "LEVEL_0" 3 "LEVEL_3" 2 "LEVEL_2" ;
VAL_ 880 EPAS3S_torsionBarTorque 4095 "SNA" 4094 "UNDEFINABLE_DATA" ;
VAL_ 880 EPAS3S_eacErrorCode 15 "SNA" 11 "EAC_ERROR_HIGH_TORSION_SAFETY" 4 "EAC_ERROR_TMP_FAULT" 2 "EAC_ERROR_MAX_SPEED" 7 "EAC_ERROR_HIGH_ANGLE_RATE_REQ" 0 "EAC_ERROR_IDLE" 10 "EAC_ERROR_HIGH_MMOT_SAFETY" 6 "EAC_ERROR_HIGH_ANGLE_REQ" 8 "EAC_ERROR_HIGH_ANGLE_SAFETY" 5 "EAR_ERROR_MAX_STEER_DELTA" 13 "EAC_ERROR_PINION_VEL_DIFF" 1 "EAC_ERROR_MIN_SPEED" 14 "EAC_EXTERNAL_MONITOR_INHIBIT" 12 "EAC_ERROR_LOW_ASSIST" 9 "EAC_ERROR_HIGH_ANGLE_RATE_SAFETY" 3 "EAC_ERROR_HANDS_ON" ;
VAL_ 880 EPAS3S_steeringRackForce 1023 "SNA" 1022 "NOT_IN_SPEC" ;
VAL_ 880 EPAS3S_steeringFault 0 "NO_FAULT" 1 "FAULT" ;
VAL_ 880 EPAS3S_steeringReduced 0 "NORMAL_ASSIST" 1 "REDUCED_ASSIST" ;
VAL_ 880 EPAS3S_internalSASQF 1 "IN_SPEC" 0 "UNDEFINABLE_ACCURACY" ;
VAL_ 880 EPAS3S_currentTuneMode 3 "STEERING_TUNE_RWD_COMFORT" 1 "STEERING_TUNE_DM_STANDARD" 5 "STEERING_TUNE_RWD_SPORT" 0 "STEERING_TUNE_DM_COMFORT" 4 "STEERING_TUNE_RWD_STANDARD" 2 "STEERING_TUNE_DM_SPORT" ;
VAL_ 1529 DAS_logMltplxr 18 "DAS_L018_ME_Boot_Msg0" 16 "DAS_L016_Calibration_Reply" 21 "DAS_L021_ME_Boot_Msg3" 19 "DAS_L019_ME_Boot_Msg1" 20 "DAS_L020_ME_Boot_Msg2" 22 "DAS_L022_SCA_EVENT" 23 "DAS_L023_PMM_EVENT" 13 "DAS_L013_Vision_Init_Msg_3" 17 "DAS_L017_MESP_Health_Data" 12 "DAS_L012_Vision_Init_Msg_2" 10 "DAS_L010_Vision_Init_Msg_0" 14 "DAS_L014_Vision_Init_Msg_4" 15 "DAS_L015_Vision_Init_Msg_5" 11 "DAS_L011_Vision_Init_Msg_1" ;
VAL_ 599 DI_uiSpeedUnits 0 "DI_SPEED_MPH" 1 "DI_SPEED_KPH" ;
VAL_ 599 DI_uiSpeed 255 "DI_UI_SPEED_SNA" ;
VAL_ 599 DI_vehicleSpeed 4095 "SNA" ;
VAL_ 1486 PARK_sw082_errorType 1 "LENGTH" 0 "NONE" 2 "CHECKSUM" 3 "SEQUENCE" 5 "OVERRUN" 4 "INVALID_DATA" ;
VAL_ 1486 PARK_sw081_errorType 1 "LENGTH" 0 "NONE" 2 "CHECKSUM" 3 "SEQUENCE" 5 "OVERRUN" 4 "INVALID_DATA" ;
VAL_ 1486 PARK_sw080_errorType 1 "LENGTH" 0 "NONE" 2 "CHECKSUM" 3 "SEQUENCE" 5 "OVERRUN" 4 "INVALID_DATA" ;
VAL_ 1486 PARK_sw077_errorType 1 "LENGTH" 0 "NONE" 2 "CHECKSUM" 3 "SEQUENCE" 5 "OVERRUN" 4 "INVALID_DATA" ;
VAL_ 1486 PARK_sw078_errorType 1 "LENGTH" 0 "NONE" 2 "CHECKSUM" 3 "SEQUENCE" 5 "OVERRUN" 4 "INVALID_DATA" ;
VAL_ 1486 PARK_sw084_errorType 1 "LENGTH" 0 "NONE" 2 "CHECKSUM" 3 "SEQUENCE" 5 "OVERRUN" 4 "INVALID_DATA" ;
VAL_ 1486 PARK_sw079_errorType 1 "LENGTH" 0 "NONE" 2 "CHECKSUM" 3 "SEQUENCE" 5 "OVERRUN" 4 "INVALID_DATA" ;
VAL_ 1486 PARK_sw083_errorType 1 "LENGTH" 0 "NONE" 2 "CHECKSUM" 3 "SEQUENCE" 5 "OVERRUN" 4 "INVALID_DATA" ;
VAL_ 1486 PARK_alertState 0 "ALERT_CLEARED" 1 "ALERT_SET" ;
VAL_ 1486 PARK_alertID 30 "PARK_a030_s6_crossTalk" 58 "PARK_a058_s12_linCommError" 46 "PARK_a046_s10_overTemp" 11 "PARK_a011_s3_overTemp" 37 "PARK_a037_s8_internalFail" 44 "PARK_a044_s9_blocked" 68 "PARK_a068_hardwareWatchDog" 85 "PARK_a085_watchdogReset" 18 "PARK_a018_s4_linCommError" 52 "PARK_a052_s11_internalFail" 77 "PARK_a077_dasError" 66 "PARK_a066_calibrationMissing" 1 "PARK_a001_s1_overTemp" 61 "PARK_a061_ecuUnderVoltage" 10 "PARK_a010_s2_crossTalk" 36 "PARK_a036_s8_overTemp" 31 "PARK_a031_s7_overTemp" 59 "PARK_a059_s12_blocked" 67 "PARK_a067_privateCANBusOff" 65 "PARK_a065_crcFault" 62 "PARK_a062_ecuOverVoltage" 50 "PARK_a050_s10_crossTalk" 7 "PARK_a007_s2_internalFail" 26 "PARK_a026_s6_overTemp" 79 "PARK_a079_epasError" 35 "PARK_a035_s7_crossTalk" 29 "PARK_a029_s6_blocked" 86 "PARK_a086_nvmFault" 4 "PARK_a004_s1_blocked" 6 "PARK_a006_s2_overTemp" 41 "PARK_a041_s9_overTemp" 27 "PARK_a027_s6_internalFail" 51 "PARK_a051_s11_overTemp" 84 "PARK_a084_sccmError" 78 "PARK_a078_diError" 81 "PARK_a081_espError" 28 "PARK_a028_s6_linCommError" 32 "PARK_a032_s7_internalFail" 0 "PARK_ALERT_DO_NOT_USE_ZERO" 83 "PARK_a083_vcFrontError" 23 "PARK_a023_s5_linCommError" 19 "PARK_a019_s4_blocked" 76 "PARK_a076_vcFrontMia" 74 "PARK_a074_espMia" 57 "PARK_a057_s12_internalFail" 49 "PARK_a049_s10_blocked" 21 "PARK_a021_s5_overTemp" 60 "PARK_a060_s12_crossTalk" 53 "PARK_a053_s11_linCommError" 16 "PARK_a016_s4_overTemp" 54 "PARK_a054_s11_blocked" 43 "PARK_a043_s9_linCommError" 20 "PARK_a020_s4_crossTalk" 39 "PARK_a039_s8_blocked" 42 "PARK_a042_s9_internalFail" 82 "PARK_a082_rcmError" 73 "PARK_a073_epbMia" 56 "PARK_a056_s12_overTemp" 48 "PARK_a048_s10_linCommError" 71 "PARK_a071_diMia" 64 "PARK_a064_ecuFault" 47 "PARK_a047_s10_internalFail" 75 "PARK_a075_rcmMia" 17 "PARK_a017_s4_internalFail" 22 "PARK_a022_s5_internalFail" 5 "PARK_a005_s1_crossTalk" 69 "PARK_a069_dasMia" 40 "PARK_a040_s8_crossTalk" 33 "PARK_a033_s7_linCommError" 70 "PARK_a070_sccmMia" 34 "PARK_a034_s7_blocked" 12 "PARK_a012_s3_internalFail" 8 "PARK_a008_s2_linCommError" 63 "PARK_a063_sensorVoltage" 3 "PARK_a003_s1_linCommError" 2 "PARK_a002_s1_internalFail" 13 "PARK_a013_s3_linCommError" 25 "PARK_a025_s5_crossTalk" 14 "PARK_a014_s3_blocked" 15 "PARK_a015_s3_crossTalk" 9 "PARK_a009_s2_blocked" 72 "PARK_a072_epasMia" 80 "PARK_a080_epbError" 24 "PARK_a024_s5_blocked" 55 "PARK_a055_s11_crossTalk" 45 "PARK_a045_s9_crossTalk" 38 "PARK_a038_s8_linCommError" ;
VAL_ 17 RCM_collisionSeverity 1 "RCM_COLLISION_SEVERITY_FIRST_STAGE" 0 "RCM_COLLISION_SEVERITY_PRETENSIONER" 2 "RCM_COLLISION_SEVERITY_SECOND_STAGE" 3 "RCM_COLLISION_SEVERITY_PEDPRO_EVENT" ;
VAL_ 17 RCM_collisionRollover 0 "RCM_COLLISION_EVENT_INACTIVE" 3 "RCM_COLLISION_EVENT_SNA" 1 "RCM_COLLISION_EVENT_ACTIVE" ;
VAL_ 17 RCM_collisionFront 0 "RCM_COLLISION_EVENT_INACTIVE" 3 "RCM_COLLISION_EVENT_SNA" 1 "RCM_COLLISION_EVENT_ACTIVE" ;
VAL_ 17 RCM_collisionLeft 0 "RCM_COLLISION_EVENT_INACTIVE" 3 "RCM_COLLISION_EVENT_SNA" 1 "RCM_COLLISION_EVENT_ACTIVE" ;
VAL_ 17 RCM_collisionRight 0 "RCM_COLLISION_EVENT_INACTIVE" 3 "RCM_COLLISION_EVENT_SNA" 1 "RCM_COLLISION_EVENT_ACTIVE" ;
VAL_ 17 RCM_collisionRear 0 "RCM_COLLISION_EVENT_INACTIVE" 3 "RCM_COLLISION_EVENT_SNA" 1 "RCM_COLLISION_EVENT_ACTIVE" ;
VAL_ 523 TAS_modeFilteredHeightRR 255 "SNA" ;
VAL_ 523 TAS_modeFilteredHeightRL 255 "SNA" ;
VAL_ 523 TAS_modeFilteredHeightFR 255 "SNA" ;
VAL_ 523 TAS_modeFilteredHeightFL 255 "SNA" ;
VAL_ 523 TAS_fastFilteredHeightRR 255 "SNA" ;
VAL_ 523 TAS_fastFilteredHeightRL 255 "SNA" ;
VAL_ 523 TAS_fastFilteredHeightFR 255 "SNA" ;
VAL_ 523 TAS_fastFilteredHeightFL 255 "SNA" ;
VAL_ 813 IBST_infoBuildType 1 "INFO_PLATFORM_BUILD" 3 "INFO_TRACEABLE_CI_BUILD" 4 "INFO_MFG_BUILD" 2 "INFO_LOCAL_BUILD" 0 "INFO_UNKNOWN_BUILD" ;
VAL_ 813 IBST_infoIndex 25 "INFO_PACKAGE_PN_1_7" 30 "INFO_PACKAGE_SN_8_14" 27 "INFO_PACKAGE_PN_15_20" 0 "INFO_DEPRECATED_0" 29 "INFO_PACKAGE_SN_1_7" 10 "INFO_BUILD_HWID_COMPONENTID" 14 "INFO_BOOTLOADER_SVN" 31 "INFO_SUBCOMPONENT_GITHASH" 19 "INFO_VERSION_DEPRECATED" 7 "INFO_DEPRECATED_7" 255 "INFO_END" 9 "INFO_DEPRECATED_9" 6 "INFO_DEPRECATED_6" 20 "INFO_UDS_PROTOCOL_BOOTCRC" 3 "INFO_DEPRECATED_3" 22 "INFO_VARIANTCRC" 17 "INFO_APP_GITHASH" 8 "INFO_DEPRECATED_8" 26 "INFO_PACKAGE_PN_8_14" 5 "INFO_DEPRECATED_5" 16 "INFO_SUBCOMPONENT" 13 "INFO_APP_CRC" 2 "INFO_DEPRECATED_2" 4 "INFO_DEPRECATED_4" 15 "INFO_BOOTLOADER_CRC" 1 "INFO_DEPRECATED_1" 11 "INFO_PCBAID_ASSYID_USAGEID" 18 "INFO_BOOTLOADER_GITHASH" ;
VAL_ 1016 UI_forksEnable 1 "FORKS_ON" 0 "FORKS_OFF" ;
VAL_ 1016 UI_source3D 1 "Z_FROM_PATH_PREDICTION" 0 "Z_FROM_MAP" 2 "XYZ_PREDICTION" ;
VAL_ 1016 UI_ulcBlindSpotConfig 1 "AGGRESSIVE" 0 "STANDARD" 2 "MAD_MAX" ;
VAL_ 1016 UI_ulcSpeedConfig 0 "SPEED_BASED_ULC_DISABLED" 1 "SPEED_BASED_ULC_MILD" 3 "SPEED_BASED_ULC_MAD_MAX" 2 "SPEED_BASED_ULC_AVERAGE" ;
VAL_ 1016 UI_followNavRouteEnable 0 "NAV_ROUTE_OFF" 1 "NAV_ROUTE_ON" ;
VAL_ 1016 UI_accFollowDistanceSetting 1 "DISTANCE_SETTING_2" 4 "DISTANCE_SETTING_5" 3 "DISTANCE_SETTING_4" 0 "DISTANCE_SETTING_1" 6 "DISTANCE_SETTING_7" 5 "DISTANCE_SETTING_6" 2 "DISTANCE_SETTING_3" 7 "DISTANCE_SETTING_SNA" ;
VAL_ 1016 UI_drivingSide 2 "DRIVING_SIDE_UNKNOWN" 0 "DRIVING_SIDE_LEFT" 1 "DRIVING_SIDE_RIGHT" ;
VAL_ 1016 UI_summonReverseDist 63 "SNA" ;
VAL_ 1016 UI_selfParkRequest 15 "SNA" 2 "SELF_PARK_REVERSE" 3 "ABORT" 0 "NONE" 8 "AUTO_SUMMON_REVERSE" 4 "PRIME" 9 "AUTO_SUMMON_CANCEL" 10 "AUTO_SUMMON_PRIMED" 1 "SELF_PARK_FORWARD" 5 "PAUSE" 7 "AUTO_SUMMON_FORWARD" 11 "SMART_SUMMON" 6 "RESUME" ;
VAL_ 1016 UI_summonEntryType 3 "SNA" 2 "TURN_LEFT" 1 "TURN_RIGHT" 0 "STRAIGHT" ;
VAL_ 1016 UI_summonExitType 3 "SNA" 2 "TURN_LEFT" 1 "TURN_RIGHT" 0 "STRAIGHT" ;
VAL_ 1016 UI_lssElkEnabled 0 "ELK_OFF" 1 "ELK_ON" ;
VAL_ 1016 UI_curvatureDatabaseOnly 0 "OFF" 1 "ON" ;
VAL_ 1016 UI_visionSpeedType 3 "VISION_SPEED_OPTIMIZED" 2 "VISION_SPEED_TWO_SECOND" 1 "VISION_SPEED_ONE_SECOND" 0 "VISION_SPEED_DISABLED" ;
VAL_ 1016 UI_fuseVehiclesDisable 0 "FUSE_VEH_ON" 1 "FUSE_VEH_OFF" ;
VAL_ 1016 UI_fuseHPPDisable 1 "FUSE_HPP_OFF" 0 "FUSE_HPP_ON" ;
VAL_ 1016 UI_fuseLanesDisable 1 "FUSE_LANES_OFF" 0 "FUSE_LANES_ON" ;
VAL_ 1016 UI_handsOnRequirementDisable 1 "HANDS_ON_REQ_OFF" 0 "HANDS_ON_REQ_ON" ;
VAL_ 1016 UI_driveOnMapsEnable 1 "DOM_ON" 0 "DOM_OFF" ;
VAL_ 1016 UI_roadCheckDisable 0 "RC_ON" 1 "RC_OFF" ;
VAL_ 1016 UI_exceptionListEnable 1 "EXCEPTION_LIST_ON" 0 "EXCEPTION_LIST_OFF" ;
VAL_ 1016 UI_lssLdwEnabled 0 "LDW_OFF" 1 "LDW_ON" ;
VAL_ 1016 UI_lssLkaEnabled 1 "LKA_ON" 0 "LKA_OFF" ;
VAL_ 1016 UI_curvSpeedAdaptDisable 0 "CSA_ON" 1 "CSA_OFF" ;
VAL_ 1016 UI_autopilotControlRequest 1 "NEXT_GEN_CTRL" 0 "LEGACY_LAT_CTRL" ;
VAL_ 526 PARK_sdiSensor6RawDistData 511 "SNA" 1 "NEAR_DETECTION" 500 "NO_OBJECT_DETECTED" 0 "BLOCKED" ;
VAL_ 526 PARK_sdiSensor5RawDistData 511 "SNA" 1 "NEAR_DETECTION" 500 "NO_OBJECT_DETECTED" 0 "BLOCKED" ;
VAL_ 526 PARK_sdiSensor4RawDistData 511 "SNA" 1 "NEAR_DETECTION" 500 "NO_OBJECT_DETECTED" 0 "BLOCKED" ;
VAL_ 526 PARK_sdiSensor3RawDistData 511 "SNA" 1 "NEAR_DETECTION" 500 "NO_OBJECT_DETECTED" 0 "BLOCKED" ;
VAL_ 526 PARK_sdiSensor2RawDistData 511 "SNA" 1 "NEAR_DETECTION" 500 "NO_OBJECT_DETECTED" 0 "BLOCKED" ;
VAL_ 526 PARK_sdiSensor1RawDistData 511 "SNA" 1 "NEAR_DETECTION" 500 "NO_OBJECT_DETECTED" 0 "BLOCKED" ;
VAL_ 680 EPBL_brakeDiscWipeRequest 1 "EPB_BRAKEDISCWIPE_REQUEST_LIGHT" 3 "EPB_BRAKEDISCWIPE_REQUEST_SNA" 0 "EPB_BRAKEDISCWIPE_REQUEST_NONE" 2 "EPB_BRAKEDISCWIPE_REQUEST_STRONG" ;
VAL_ 680 EPBL_cdpRequest 0 "EPB_CDP_NOT_REQUESTED" 1 "EPB_CDP_REQUESTED" ;
VAL_ 680 EPBL_telltale 0 "EPB_TELLTALE_LAMP_OFF" 2 "EPB_TELLTALE_LAMP_AMBER_ON" 3 "EPB_TELLTALE_LAMP_RED_FLASH" 1 "EPB_TELLTALE_LAMP_RED_ON" 7 "EPB_TELLTALE_SNA" ;
VAL_ 680 EPBL_systemStatus 0 "EPB_VEHICLE_STATUS_UNKNOWN" 2 "EPB_VEHICLE_STATUS_PARKED" 6 "EPB_VEHICLE_STATUS_FAULT" 3 "EPB_VEHICLE_STATUS_DYNAMIC" 1 "EPB_VEHICLE_STATUS_RELEASED" 4 "EPB_VEHICLE_STATUS_PARKING" 5 "EPB_VEHICLE_STATUS_RELEASING" 8 "EPB_VEHICLE_STATUS_MISMATCH" 7 "EPB_VEHICLE_STATUS_FAULT_SECURE" ;
VAL_ 590 PARK_pscLeftCrossSizeY 255 "SNA" 254 "NO_SPACE" ;
VAL_ 590 PARK_pscRightParallelSizeY 255 "SNA" 254 "NO_SPACE" ;
VAL_ 590 PARK_pscLeftParallelSizeY 255 "SNA" 254 "NO_SPACE" ;
VAL_ 590 PARK_pscRightCrossSizeY 255 "SNA" 254 "NO_SPACE" ;
VAL_ 590 PARK_pscRightParallelSizeX 255 "SNA" 254 "NO_SPACE" ;
VAL_ 590 PARK_pscLeftParallelSizeX 255 "SNA" 254 "NO_SPACE" ;
VAL_ 590 PARK_pscLeftCrossSizeX 255 "SNA" 254 "NO_SPACE" ;
VAL_ 590 PARK_pscRightCrossSizeX 255 "SNA" 254 "NO_SPACE" ;
VAL_ 590 PARK_pscRightParallelPsi 8191 "SNA" 8190 "NO_SPACE" ;
VAL_ 590 PARK_pscRightCrossPsi 8191 "SNA" 8190 "NO_SPACE" ;
VAL_ 590 PARK_pscLeftCrossPsi 8191 "SNA" 8190 "NO_SPACE" ;
VAL_ 590 PARK_pscLeftParallelPsi 8191 "SNA" 8190 "NO_SPACE" ;
VAL_ 590 PARK_pscRightParallelVehY 2047 "SNA" 2046 "NO_SPACE" ;
VAL_ 590 PARK_pscLeftCrossVehY 2047 "SNA" 2046 "NO_SPACE" ;
VAL_ 590 PARK_pscRightCrossVehY 2047 "SNA" 2046 "NO_SPACE" ;
VAL_ 590 PARK_pscLeftParallelVehY 2047 "SNA" 2046 "NO_SPACE" ;
VAL_ 590 PARK_pscLeftCrossVehX 2047 "SNA" 2046 "NO_SPACE" ;
VAL_ 590 PARK_pscRightCrossVehX 2047 "SNA" 2046 "NO_SPACE" ;
VAL_ 590 PARK_pscRightParallelVehX 2047 "SNA" 2046 "NO_SPACE" ;
VAL_ 590 PARK_pscLeftParallelVehX 2047 "SNA" 2046 "NO_SPACE" ;
VAL_ 590 PARK_pscVehSlotType 1 "LEFT_CROSS" 2 "RIGHT_PARALLEL" 0 "LEFT_PARALLEL" 3 "RIGHT_CROSS" ;
VAL_ 600 APB_watchdogState 1 "AP_WDOG_STATE_DEGRADED" 7 "AP_WDOG_STATE_SNA" 3 "AP_WDOG_STATE_HEALTHY" 0 "AP_WDOG_STATE_UNKNOWN" 2 "AP_WDOG_STATE_CRITICAL" ;
VAL_ 574 PARK_oocOffCourse 1023 "NONE" ;
VAL_ 574 PARK_oocHeight 1 "LOW_OBJ" 3 "HEIGHT_UNKNOWN" 0 "NO_OBJ" 2 "HIGH_OBJ" ;
VAL_ 574 PARK_oocUntrackedTime 63 "SNA" ;
VAL_ 574 PARK_oocCollisionSide 7 "COLLISION_SNA" 4 "REAR_COLLISION" 0 "NO_COLLISION" 3 "FRONT_COLLISION" 2 "LEFT_SIDE_COLLISION" 5 "COLLISION_UNKNOWN" 1 "RIGHT_SIDE_COLLISION" ;
VAL_ 574 PARK_oocVehicleY 255 "UNKNOWN" ;
VAL_ 574 PARK_oocVehicleX 255 "UNKNOWN" ;
VAL_ 574 PARK_oocConfidence 127 "SNA" 0 "NO_CONFIDENCE" ;
VAL_ 574 PARK_oocDistance 511 "SNA" 500 "NO_OBJ_COLLISION" 501 "NOT_INITIALIZED" ;
